VERSION ""

NS_ :

BS_:

BU_: ARM APIM_CDC APIM_CISM APIM ESPM DSP APIM_CIM FCIMB RACM_RCIM HUD_ADV WCM TRM_ITRM ACM GWM _delete IPC GENERIC TSTR

BO_ 974 DCACA_Data4_HS3: 8 GWM
 SG_ LowFuelDsplyType_B_Rq : 56|1@0+ (1,0) [0|1] "SED"  IPC
 SG_ PwBedPnlEnblScnd_B_Rq : 48|1@0+ (1,0) [0|1] "SED" Vector__XXX
 SG_ DcacSysScnd_B_Falt : 40|1@0+ (1,0) [0|1] "SED" Vector__XXX
 SG_ DcacOnScnd_B_Rq : 32|1@0+ (1,0) [0|1] "SED" Vector__XXX
 SG_ DcacGfciTestScnd_B_Rq : 24|1@0+ (1,0) [0|1] "SED" Vector__XXX
 SG_ DcacGfciTest_B_Rq : 0|1@0+ (1,0) [0|1] "SED" Vector__XXX
 SG_ EngExhMdeHrStrt_D_Stat : 53|5@0+ (1,0) [0|31] "SED"  APIM_CDC,APIM,APIM_CISM,APIM_CIM
 SG_ EngExhMdeHrEnd_D_Stat : 63|5@0+ (1,0) [0|31] "SED"  APIM_CDC,APIM,APIM_CISM,APIM_CIM
 SG_ EngExhMdeHrEnbl_D_Stat : 58|2@0+ (1,0) [0|3] "SED"  APIM_CDC,APIM,APIM_CISM,APIM_CIM
 SG_ DcacOut_Pw_DsplyMx : 23|10@0+ (10,0) [0|10220] "watts"  APIM_CDC,APIM,APIM_CIM,APIM_CISM
 SG_ DcacOut1_Pw_Dsply : 39|7@0+ (100,0) [0|12600] "watts"  APIM_CDC,APIM,APIM_CIM,APIM_CISM
 SG_ DcacOut2_Pw_Dsply : 47|7@0+ (100,0) [0|12600] "watts"  APIM_CDC,APIM,APIM_CIM,APIM_CISM
 SG_ DcacHw_D_Confg : 11|4@0+ (1,0) [0|15] "SED"  APIM_CDC,APIM,APIM_CIM,APIM_CISM
 SG_ DcacFaltMsgTxt_D_Rq : 15|4@0+ (1,0) [0|15] "SED"  APIM_CDC,APIM,APIM_CIM,APIM_CISM
 SG_ DcacLoFuelMsgTxt_D_Rq : 29|5@0+ (1,0) [0|31] "SED"  APIM_CDC,APIM,APIM_CIM,APIM_CISM
 SG_ DcacEngOnMsgTxt_D_Rq : 55|2@0+ (1,0) [0|3] "SED"  APIM_CDC,APIM,APIM_CIM,APIM_CISM
 SG_ DcacElPw_D_Stat : 2|2@0+ (1,0) [0|3] "SED"  APIM_CDC,APIM,APIM_CIM,APIM_CISM
 SG_ PwBedPnlEnbl_B_Rq : 3|1@0+ (1,0) [0|1] "SED"  GENERIC
 SG_ DcacOn_B_Rq : 4|1@0+ (1,0) [0|1] "SED"  GENERIC
 SG_ DcacSys_B_Falt : 5|1@0+ (1,0) [0|1] "SED"  GENERIC
 SG_ DcacLedCtl_D_Rq : 7|2@0+ (1,0) [0|3] "SED"  GENERIC

BO_ 810 ECG_Data_HS3: 8 GWM
 SG_ OneTEditActv_B_RqCld : 32|1@0+ (1,0) [0|1] "SED"  APIM_CDC,APIM,APIM_CIM,APIM_CISM
 SG_ ExtLghtDsply_B_StatArb : 7|1@0+ (1,0) [0|1] "SED"  APIM_CDC,APIM,APIM_CIM,APIM_CISM

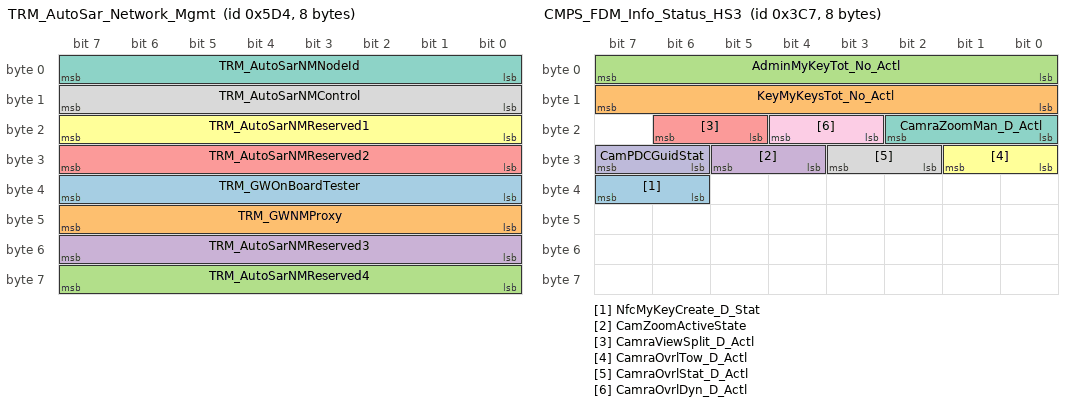
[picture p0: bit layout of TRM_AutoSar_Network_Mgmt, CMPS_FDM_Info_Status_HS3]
BO_ 1492 TRM_AutoSar_Network_Mgmt: 8 TRM_ITRM
 SG_ TRM_GWOnBoardTester : 39|8@0+ (1,0) [0|255] "unitless"  GENERIC
 SG_ TRM_GWNMProxy : 47|8@0+ (1,0) [0|255] "unitless"  GENERIC
 SG_ TRM_AutoSarNMReserved4 : 63|8@0+ (1,0) [0|255] "unitless"  GENERIC
 SG_ TRM_AutoSarNMReserved3 : 55|8@0+ (1,0) [0|255] "unitless"  GENERIC
 SG_ TRM_AutoSarNMReserved2 : 31|8@0+ (1,0) [0|255] "unitless"  GENERIC
 SG_ TRM_AutoSarNMReserved1 : 23|8@0+ (1,0) [0|255] "unitless"  GENERIC
 SG_ TRM_AutoSarNMNodeId : 7|8@0+ (1,0) [0|255] "unitless"  GENERIC
 SG_ TRM_AutoSarNMControl : 15|8@0+ (1,0) [0|255] "unitless"  GENERIC

BO_ 709 DSPAMP_RDISP_WORD_Tx: 8 DSP
 SG_ DSPAMP_RDISP_WORD_Tx : 7|64@0+ (1,0) [0|1.84467440737096E+019] "unitless"  APIM,APIM_CIM,APIM_CISM

BO_ 552 DSPAMP_Send_Signals: 8 DSP
 SG_ ActvNseMute_D_Stat : 58|2@0+ (1,0) [0|3] "SED"  APIM_CDC,APIM,APIM_CISM,APIM_CIM
 SG_ DSP_Treble_St : 55|4@0+ (1,-7) [-7|8] "unitless"  APIM_CDC,APIM,APIM_CISM,APIM_CIM
 SG_ DSP_VoiceFBVolume_Up : 35|1@0+ (1,0) [0|1] "SED"  APIM_CDC,APIM,APIM_CISM,IPC,HUD_ADV,APIM_CIM
 SG_ DSP_VoiceFBVolume_St : 63|5@0+ (1,0) [0|30] "unitless"  APIM_CDC,APIM,APIM_CISM,IPC,HUD_ADV,WCM,APIM_CIM
 SG_ DSP_TAVolume_Up : 34|1@0+ (1,0) [0|1] "SED"  APIM_CDC,APIM,APIM_CISM,IPC,HUD_ADV,APIM_CIM
 SG_ DSP_TAVolume_St : 44|5@0+ (1,0) [0|30] "unitless"  APIM_CDC,APIM,APIM_CISM,IPC,HUD_ADV,WCM,APIM_CIM
 SG_ DSP_Shaker_St : 1|1@0+ (1,0) [0|1] "SED"  APIM_CDC,APIM,APIM_CISM,APIM_CIM
 SG_ DSP_Reg_St : 27|2@0+ (1,0) [0|3] "SED"  APIM_CDC,APIM,APIM_CISM,APIM_CIM
 SG_ DSP_PhoneVolume_Up : 25|1@0+ (1,0) [0|1] "SED"  APIM_CDC,APIM,APIM_CISM,IPC,HUD_ADV,APIM_CIM
 SG_ DSP_PhoneVolume_St : 33|5@0+ (1,0) [0|30] "unitless"  APIM_CDC,APIM,APIM_CISM,IPC,HUD_ADV,WCM,APIM_CIM
 SG_ DSP_NavCmdVolume_Up : 7|1@0+ (1,0) [0|1] "SED"  APIM_CDC,APIM,APIM_CISM,IPC,HUD_ADV,APIM_CIM
 SG_ DSP_NavCmdVolume_St : 24|5@0+ (1,0) [0|30] "SED"  APIM_CDC,APIM,APIM_CISM,IPC,HUD_ADV,WCM,APIM_CIM
 SG_ DSP_Midrange_St : 51|4@0+ (1,-7) [-7|8] "unitless"  APIM_CDC,APIM,APIM_CISM,APIM_CIM
 SG_ DSP_Fader_St : 20|4@0+ (1,-7) [-7|8] "unitless"  APIM_CDC,APIM,APIM_CISM,APIM_CIM
 SG_ DSP_DSPProgram_St : 15|3@0+ (1,0) [0|7] "SED"  APIM_CDC,APIM,APIM_CISM,APIM_CIM
 SG_ DSP_DSP_St : 16|5@0+ (1,0) [0|31] "SED"  APIM_CDC,APIM,APIM_CISM,APIM_CIM
 SG_ DSP_Bass_St : 12|4@0+ (1,-7) [-7|8] "unitless"  APIM_CDC,APIM,APIM_CISM,APIM_CIM
 SG_ DSP_Balance_St : 8|4@0+ (1,-7) [-7|8] "unitless"  APIM_CDC,APIM,APIM_CISM,APIM_CIM
 SG_ DSP_AVC_St : 6|3@0+ (1,0) [0|7] "SED"  APIM_CDC,APIM,APIM_CISM,APIM_CIM
 SG_ Audio_Demo_Status : 0|1@0+ (1,0) [0|1] "SED"  APIM_CDC,APIM,APIM_CISM,APIM_CIM

BO_ 967 CMPS_FDM_Info_Status_HS3: 8 GWM
 SG_ NfcMyKeyCreate_D_Stat : 39|2@0+ (1,0) [0|3] "SED"  APIM,APIM_CIM
 SG_ KeyMyKeysTot_No_Actl : 15|8@0+ (1,0) [0|255] "unitless"  APIM,APIM_CIM
 SG_ AdminMyKeyTot_No_Actl : 7|8@0+ (1,0) [0|255] "unitless"  APIM,APIM_CIM
 SG_ CamZoomActiveState : 29|2@0+ (1,0) [0|3] "SED"  APIM_CDC,APIM,APIM_CIM,APIM_CISM
 SG_ CamraViewSplit_D_Actl : 22|2@0+ (1,0) [0|3] "SED"  APIM_CDC,APIM,APIM_CIM,APIM_CISM
 SG_ CamraOvrlTow_D_Actl : 25|2@0+ (1,0) [0|3] "SED"  APIM_CDC,APIM,APIM_CIM,APIM_CISM
 SG_ CamraZoomMan_D_Actl : 18|3@0+ (1,0) [0|7] "SED"  APIM_CDC,APIM,APIM_CIM,APIM_CISM
 SG_ CamraOvrlStat_D_Actl : 27|2@0+ (1,0) [0|3] "SED"  APIM_CDC,APIM,APIM_CIM,APIM_CISM
 SG_ CamraOvrlDyn_D_Actl : 20|2@0+ (1,0) [0|3] "SED"  APIM_CDC,APIM,APIM_CIM,APIM_CISM
 SG_ CamPDCGuidStat : 31|2@0+ (1,0) [0|3] "SED"  APIM_CDC,APIM,APIM_CIM,APIM_CISM

BO_ 1105 Image_Processing_Data_HS3: 8 GWM
 SG_ ClrExitAsstActv_B_Rq : 24|1@0+ (1,0) [0|1] "SED"  APIM_CDC,APIM,APIM_CISM,APIM_CIM
 SG_ ClrExitAsstMsgTxt2_D_Rq : 55|4@0+ (1,0) [0|15] "SED"  APIM_CDC,APIM,APIM_CISM,APIM_CIM
 SG_ TrlrRvrseEnbl_D2_Stat : 18|3@0+ (1,0) [0|7] "SED"  APIM_CDC,APIM,APIM_CIM,APIM_CISM,TRM_ITRM,IPC
 SG_ TrlrAidSwtchLamp_B_Rq : 32|1@0+ (1,0) [0|1] "SED"  TRM_ITRM
 SG_ TrlrAidEnbl_D_RqAdas : 5|3@0+ (1,0) [0|7] "SED"  GENERIC
 SG_ TrlrHitchMsgTxt_D_Rq : 47|6@0+ (1,0) [0|63] "SED"  APIM_CDC,APIM,APIM_CIM,APIM_CISM
 SG_ TrlrHitchIcon_D_Rq : 36|4@0+ (1,0) [0|15] "SED"  APIM_CDC,APIM,APIM_CIM,APIM_CISM
 SG_ CamraFrntOffRd_B_Stat : 25|1@0+ (1,0) [0|1] "SED"  APIM_CDC,APIM,APIM_CIM,APIM_CISM
 SG_ TrlrHitchChime_D_Rq : 39|3@0+ (1,0) [0|7] "SED"  APIM_CDC,IPC,APIM_CIM
 SG_ TrlrRvrseMsgTxt_D2_Rq : 31|6@0+ (1,0) [0|63] "SED"  APIM_CDC,APIM,APIM_CIM,APIM_CISM,TRM_ITRM,IPC
 SG_ RbaMsg_D_Rq : 22|2@0+ (1,0) [0|3] "SED"  APIM_CDC,APIM_CIM,IPC
 SG_ BrkDecel_B_RqRba : 8|1@0+ (1,0) [0|1] "SED" Vector__XXX
 SG_ BrkEnbl_B_RqRba : 23|1@0+ (1,0) [0|1] "SED" Vector__XXX
 SG_ Rba_D_Stat : 14|2@0+ (1,0) [0|3] "SED"  APIM_CDC,APIM,APIM_CIM,APIM_CISM,IPC
 SG_ RbaAlrt_D_Dsply : 12|2@0+ (1,0) [0|3] "SED"  APIM_CDC,APIM,APIM_CIM,APIM_CISM,IPC
 SG_ RbaMnu_D_Rq : 10|2@0+ (1,0) [0|3] "SED"  APIM_CDC,APIM,APIM_CIM,APIM_CISM
 SG_ CamraFrntStat_D_Stat : 7|2@0+ (1,0) [0|3] "SED"  APIM_CDC,APIM,APIM_CISM,APIM_CIM,FCIMB,ACM,IPC
 SG_ TrlrHitchLamp_D_Rq2 : 15|1@0+ (1,0) [0|1] "SED" Vector__XXX

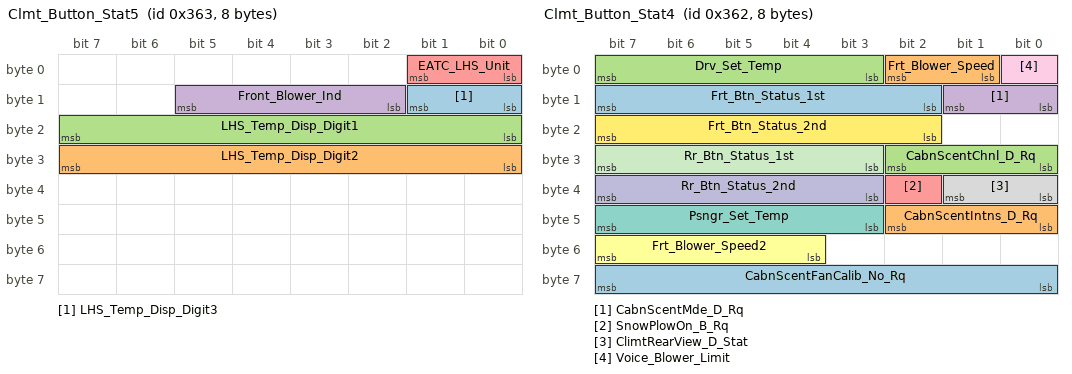
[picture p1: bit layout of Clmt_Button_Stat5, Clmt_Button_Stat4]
BO_ 867 Clmt_Button_Stat5: 8 IPC
 SG_ LHS_Temp_Disp_Digit3 : 9|2@0+ (1,0) [0|3] "SED"  HUD_ADV,GWM
 SG_ LHS_Temp_Disp_Digit2 : 31|8@0+ (1,0) [0|255] "ASCII"  HUD_ADV,GWM
 SG_ LHS_Temp_Disp_Digit1 : 23|8@0+ (1,0) [0|255] "ASCII"  HUD_ADV,GWM
 SG_ Front_Blower_Ind : 13|4@0+ (1,0) [0|15] "SED"  GWM
 SG_ EATC_LHS_Unit : 1|2@0+ (1,0) [0|3] "SED"  HUD_ADV,GWM

BO_ 866 Clmt_Button_Stat4: 8 APIM
 SG_ CabnScentFanCalib_No_Rq : 63|8@0+ (1,0) [0|255] "SED"  GWM
 SG_ CabnScentIntns_D_Rq : 42|3@0+ (1,0) [0|7] "SED"  GWM
 SG_ CabnScentChnl_D_Rq : 26|3@0+ (1,0) [0|7] "SED"  GWM
 SG_ CabnScentMde_D_Rq : 9|2@0+ (1,0) [0|3] "SED"  GWM
 SG_ SnowPlowOn_B_Rq : 34|1@0+ (1,0) [0|1] "SED"  GWM
 SG_ Frt_Blower_Speed2 : 55|4@0+ (1,0) [0|15] "SED"  RACM_RCIM,GWM
 SG_ Psngr_Set_Temp : 47|5@0+ (1,0) [0|31] "SED"  RACM_RCIM,GWM
 SG_ ClimtRearView_D_Stat : 33|2@0+ (1,0) [0|3] "SED"  GWM,RACM_RCIM
 SG_ Voice_Blower_Limit : 0|1@0+ (1,0) [0|1] "SED"  GWM
 SG_ Rr_Btn_Status_2nd : 39|5@0+ (1,0) [0|31] "SED"  RACM_RCIM,GWM
 SG_ Rr_Btn_Status_1st : 31|5@0+ (1,0) [0|31] "SED"  RACM_RCIM,GWM
 SG_ Frt_Btn_Status_2nd : 23|6@0+ (1,0) [0|63] "SED"  ACM,RACM_RCIM,GWM
 SG_ Frt_Btn_Status_1st : 15|6@0+ (1,0) [0|63] "SED"  ACM,RACM_RCIM,GWM
 SG_ Frt_Blower_Speed : 2|2@0+ (1,0) [0|3] "SED"  RACM_RCIM,GWM
 SG_ Drv_Set_Temp : 7|5@0+ (1,0) [0|31] "SED"  RACM_RCIM,GWM

BO_ 861 Clmt_Button_Stat3_HS3: 8 GWM
 SG_ Rr_Temp_Detents : 63|6@0+ (1,0) [0|63] "SED"  APIM_CDC,APIM,APIM_CIM,APIM_CISM,RACM_RCIM
 SG_ Rr_Power_Btn_Stt : 57|2@0+ (1,0) [0|3] "SED"  APIM_CDC,APIM,APIM_CIM,APIM_CISM,RACM_RCIM
 SG_ Rr_RH_Cond_Seat_Stat : 18|3@0+ (1,0) [0|7] "SED"  APIM_CDC,APIM,APIM_CIM,APIM_CISM,RACM_RCIM
 SG_ Rr_Pnl_Flr_Btn_Stt : 33|2@0+ (1,0) [0|3] "SED"  APIM_CDC,APIM,APIM_CIM,APIM_CISM,RACM_RCIM
 SG_ Rr_LH_Cond_Seat_Stat : 21|3@0+ (1,0) [0|7] "SED"  APIM_CDC,APIM,APIM_CIM,APIM_CISM,RACM_RCIM
 SG_ CC_Rr_Stat_User_Adj : 7|4@0+ (1,0) [0|15] "SED"  APIM_CDC,APIM,APIM_CIM,APIM_CISM,RACM_RCIM
 SG_ Rr_Set_Temp_Units : 41|2@0+ (1,0) [0|3] "SED"  APIM_CDC,APIM,APIM_CIM,APIM_CISM,RACM_RCIM
 SG_ Rr_RHS_Set_Temp_Dig3 : 43|2@0+ (1,0) [0|3] "SED"  APIM_CDC,APIM,APIM_CIM,APIM_CISM,RACM_RCIM
 SG_ Rr_RHS_Set_Temp_Dig2 : 51|4@0+ (1,0) [0|15] "SED"  APIM_CDC,APIM,APIM_CIM,APIM_CISM,RACM_RCIM
 SG_ Rr_RHS_Set_Temp_Dig1 : 55|4@0+ (1,0) [0|15] "SED"  APIM_CDC,APIM,APIM_CIM,APIM_CISM,RACM_RCIM
 SG_ Rr_RH_Htd_Seat_Btn_Stt : 45|2@0+ (1,0) [0|3] "SED"  APIM_CDC,APIM,APIM_CIM,APIM_CISM,RACM_RCIM
 SG_ Rr_RH_Cld_Seat_Btn_Stt : 47|2@0+ (1,0) [0|3] "SED"  APIM_CDC,APIM,APIM_CIM,APIM_CISM,RACM_RCIM
 SG_ Rr_Panel_Btn_Stt : 35|2@0+ (1,0) [0|3] "SED"  APIM_CDC,APIM,APIM_CIM,APIM_CISM,RACM_RCIM
 SG_ Rr_On_Indicator : 2|1@0+ (1,0) [0|1] "SED"  APIM_CDC,APIM,APIM_CIM,APIM_CISM,RACM_RCIM
 SG_ Rr_LHS_Set_Temp_Dig3 : 37|2@0+ (1,0) [0|3] "SED"  APIM_CDC,APIM,APIM_CIM,APIM_CISM,RACM_RCIM
 SG_ Rr_LHS_Set_Temp_Dig2 : 25|4@0+ (1,0) [0|15] "SED"  APIM_CDC,APIM,APIM_CIM,APIM_CISM,RACM_RCIM
 SG_ Rr_LHS_Set_Temp_Dig1 : 29|4@0+ (1,0) [0|15] "SED"  APIM_CDC,APIM,APIM_CIM,APIM_CISM,RACM_RCIM
 SG_ Rr_LH_Htd_Seat_Btn_Stt : 31|2@0+ (1,0) [0|3] "SED"  APIM_CDC,APIM,APIM_CIM,APIM_CISM,RACM_RCIM
 SG_ Rr_LH_Cld_Seat_Btn_Stt : 23|2@0+ (1,0) [0|3] "SED"  APIM_CDC,APIM,APIM_CIM,APIM_CISM,RACM_RCIM
 SG_ Rr_Floor_Btn_Stt : 9|2@0+ (1,0) [0|3] "SED"  APIM_CDC,APIM,APIM_CIM,APIM_CISM,RACM_RCIM
 SG_ Rr_Control_Btn_Stt : 11|2@0+ (1,0) [0|3] "SED"  APIM_CDC,APIM,APIM_CIM,APIM_CISM,RACM_RCIM
 SG_ Rr_Blower_Indicate : 15|4@0+ (1,0) [0|15] "SED"  APIM_CDC,APIM,APIM_CIM,APIM_CISM,RACM_RCIM
 SG_ Rr_AUTO_Btn_Stt : 1|2@0+ (1,0) [0|3] "SED"  APIM_CDC,APIM,APIM_CIM,APIM_CISM,RACM_RCIM

BO_ 865 Clmt_Button_Stat2_HS3: 8 GWM
 SG_ Dsp_RotAddrBtnEv_St : 63|4@0+ (1,0) [0|15] "SED"  APIM_CDC,APIM,APIM_CIM,APIM_CISM
 SG_ SelDrvMdeButtn_B_Stat : 55|1@0+ (1,0) [0|1] "SED" Vector__XXX
 SG_ SteEffortButtn_B_Stat : 54|1@0+ (1,0) [0|1] "SED"  APIM_CDC,APIM_CIM,IPC
 SG_ SelDrvMdeSwtch_D_Stat2 : 51|2@0+ (1,0) [0|3] "SED" Vector__XXX
 SG_ EngExhMdeQuiet_B_RqDrv : 52|1@0+ (1,0) [0|1] "SED"  APIM_CDC,APIM_CIM,IPC
 SG_ LnchCtlSys_B_RqDrv : 53|1@0+ (1,0) [0|1] "SED"  APIM_CDC,APIM_CIM,IPC
 SG_ CC_Fr_Stat_User_Adj : 6|3@0+ (1,0) [0|7] "SED"  HUD_ADV,GENERIC
 SG_ RHS_Auto_Seat_Btn_Stt : 57|2@0+ (1,0) [0|3] "SED"  APIM_CDC,APIM,APIM_CIM,APIM_CISM,FCIMB
 SG_ Front_Blower_Indicate : 13|4@0+ (1,0) [0|15] "SED"  APIM_CDC,APIM,APIM_CISM,HUD_ADV,APIM_CIM,IPC
 SG_ CC_Diagnostics_Active : 7|1@0+ (1,0) [0|1] "SED"  IPC
 SG_ RHS_Temp_Display_Digit3 : 3|2@0+ (1,0) [0|3] "SED"  APIM_CDC,APIM,APIM_CIM,APIM_CISM,IPC
 SG_ RHS_Temp_Display_Digit2 : 47|8@0+ (1,0) [0|255] "ASCII"  APIM_CDC,APIM,APIM_CIM,APIM_CISM,IPC
 SG_ RHS_Temp_Display_Digit1 : 39|8@0+ (1,0) [0|255] "ASCII"  APIM_CDC,APIM,APIM_CIM,APIM_CISM,IPC
 SG_ LHS_Temp_Display_Digit3 : 9|2@0+ (1,0) [0|3] "SED"  APIM_CDC,APIM,APIM_CIM,APIM_CISM,IPC
 SG_ LHS_Temp_Display_Digit2 : 31|8@0+ (1,0) [0|255] "ASCII"  APIM_CDC,APIM,APIM_CIM,APIM_CISM,IPC
 SG_ LHS_Temp_Display_Digit1 : 23|8@0+ (1,0) [0|255] "ASCII"  APIM_CDC,APIM,APIM_CIM,APIM_CISM,IPC
 SG_ EATC_RHS_Units : 15|2@0+ (1,0) [0|3] "SED"  APIM_CDC,APIM,APIM_CIM,APIM_CISM,IPC
 SG_ EATC_LHS_Units : 1|2@0+ (1,0) [0|3] "SED"  APIM_CDC,APIM,APIM_CIM,APIM_CISM,IPC
 SG_ LHS_Auto_Seat_Btn_Stt : 59|2@0+ (1,0) [0|3] "SED"  APIM_CDC,APIM,APIM_CIM,APIM_CISM,FCIMB

BO_ 1046 BrakeSysFeatures_2_HS3: 8 GWM
 SG_ PrkBrkDynmc_D_Allw : 39|2@0+ (1,0) [0|3] "SED"  IPC
 SG_ BrkPrkBrkDynmc_B_Actl : 24|1@0+ (1,0) [0|1] "SED"  IPC
 SG_ TRLR_SWAY_EVNT_IN_PROG : 25|1@0+ (1,0) [0|1] "SED"  APIM_CDC,APIM,APIM_CISM,APIM_CIM,IPC
 SG_ TRLR_SWAY_CONFIG_STAT : 26|1@0+ (1,0) [0|1] "SED"  APIM_CDC,APIM,APIM_CISM,APIM_CIM,IPC
 SG_ ReserveTracCtlPtActv : 28|1@0+ (1,0) [0|1] "SED" Vector__XXX
 SG_ HsaMde_D_Mem : 33|2@0+ (1,0) [0|3] "SED"  APIM_CDC,APIM,APIM_CISM,APIM_CIM,IPC
 SG_ BrkBstrVac_B_Rq : 27|1@0+ (1,0) [0|1] "Discrete" Vector__XXX
 SG_ BpedDiffLckTq_No_Cs : 23|8@0+ (1,0) [0|255] "unitless"  GENERIC
 SG_ DrvSlipCtlMde_D_Ind : 44|2@0+ (1,0) [0|3] "SED"  APIM_CDC,APIM_CIM,IPC
 SG_ DrvSlipCtlLamp_D_Rq : 42|2@0+ (1,0) [0|3] "SED"  APIM_CDC,APIM_CISM,APIM_CIM,IPC
 SG_ TCMode : 15|1@0+ (1,0) [0|1] "SED"  APIM_CDC,APIM,APIM_CIM,APIM_CISM,IPC
 SG_ HILL_DESC_MC : 47|3@0+ (1,0) [0|7] "SED"  APIM_CDC,APIM,APIM_CISM,APIM_CIM,IPC
 SG_ DrvAntiLckLamp_D_Rq : 55|2@0+ (1,0) [0|3] "SED"  APIM_CDC,APIM_CISM,APIM_CIM,IPC
 SG_ ChimeBrk_B_Rq : 14|1@0+ (1,0) [0|1] "SED"  APIM_CDC,APIM_CIM,IPC
 SG_ BrkLamp_B_Rq : 13|1@0+ (1,0) [0|1] "SED"  APIM_CDC,APIM_CIM,IPC
 SG_ Abs_B_Falt : 5|1@0+ (1,0) [0|1] "SED"  TRM_ITRM,IPC
 SG_ StabCtlBrk_B_Avail : 4|1@0+ (1,0) [0|1] "SED"  IPC
 SG_ DrvHdcWarnInfo_D_Rq : 35|2@0+ (1,0) [0|3] "SED"  APIM_CDC,APIM_CIM,IPC
 SG_ DrvHdcMsg_D_Rq : 10|3@0+ (1,0) [0|7] "SED"  IPC
 SG_ DrvHdcLampInfo_D_Rq : 12|2@0+ (1,0) [0|3] "SED"  APIM_CDC,APIM,APIM_CISM,APIM_CIM,IPC
 SG_ RearDiffElckrOpen_B_Rq : 40|1@0+ (1,0) [0|1] "SED"  GENERIC
 SG_ BpedMove_No_Cnt : 3|4@0+ (1,0) [0|15] "unitless"  GENERIC
 SG_ BpedMove_D_Actl : 7|2@0+ (1,0) [0|3] "SED" Vector__XXX
 SG_ RearDiffLck_Tq2_RqMx : 51|12@0+ (4,0) [0|16376] "Nm"  GENERIC
 SG_ HdcMde_D_Actl : 31|3@0+ (1,0) [0|7] "SED" Vector__XXX

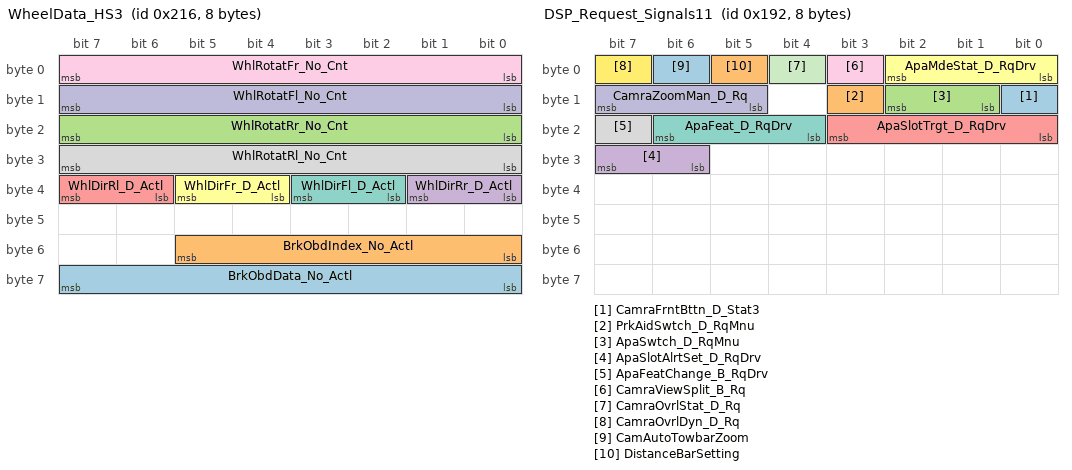
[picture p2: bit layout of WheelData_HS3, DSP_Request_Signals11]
BO_ 534 WheelData_HS3: 8 GWM
 SG_ BrkObdData_No_Actl : 63|8@0+ (1,0) [0|255] "unitless"  GENERIC
 SG_ BrkObdIndex_No_Actl : 53|6@0+ (1,0) [0|63] "unitless"  GENERIC
 SG_ WhlRotatRr_No_Cnt : 23|8@0+ (1,0) [0|255] "unitless"  APIM_CDC,APIM,APIM_CIM,APIM_CISM
 SG_ WhlDirRr_D_Actl : 33|2@0+ (1,0) [0|3] "SED"  APIM_CDC,APIM,APIM_CIM,APIM_CISM
 SG_ WhlDirRl_D_Actl : 39|2@0+ (1,0) [0|3] "SED"  APIM_CDC,APIM,APIM_CIM,APIM_CISM
 SG_ WhlDirFr_D_Actl : 37|2@0+ (1,0) [0|3] "SED"  APIM_CDC,APIM,APIM_CIM,APIM_CISM
 SG_ WhlDirFl_D_Actl : 35|2@0+ (1,0) [0|3] "SED"  APIM_CDC,APIM,APIM_CIM,APIM_CISM
 SG_ WhlRotatRl_No_Cnt : 31|8@0+ (1,0) [0|255] "unitless"  APIM_CDC,APIM,APIM_CIM,APIM_CISM
 SG_ WhlRotatFr_No_Cnt : 7|8@0+ (1,0) [0|255] "unitless"  APIM_CDC,APIM,APIM_CIM,APIM_CISM
 SG_ WhlRotatFl_No_Cnt : 15|8@0+ (1,0) [0|255] "unitless"  APIM_CDC,APIM,APIM_CIM,APIM_CISM

BO_ 402 DSP_Request_Signals11: 8 APIM_CIM
 SG_ CamraFrntBttn_D_Stat3 : 8|1@0+ (1,0) [0|1] "SED"  GWM
 SG_ PrkAidSwtch_D_RqMnu : 11|1@0+ (1,0) [0|1] "SED"  GWM
 SG_ ApaSwtch_D_RqMnu : 10|2@0+ (1,0) [0|3] "SED"  GWM
 SG_ ApaSlotAlrtSet_D_RqDrv : 31|2@0+ (1,0) [0|3] "SED"  GWM
 SG_ ApaSlotTrgt_D_RqDrv : 19|4@0+ (1,0) [0|15] "SED"  GWM
 SG_ ApaMdeStat_D_RqDrv : 2|3@0+ (1,0) [0|7] "SED"  GWM
 SG_ ApaFeat_D_RqDrv : 22|3@0+ (1,0) [0|7] "SED"  GWM
 SG_ ApaFeatChange_B_RqDrv : 23|1@0+ (1,0) [0|1] "SED"  GWM
 SG_ CamraViewSplit_B_Rq : 3|1@0+ (1,0) [0|1] "SED"  GWM
 SG_ CamraZoomMan_D_Rq : 15|3@0+ (1,0) [0|7] "SED"  GWM
 SG_ CamraOvrlStat_D_Rq : 4|1@0+ (1,0) [0|1] "SED"  IPC,GWM
 SG_ CamraOvrlDyn_D_Rq : 7|1@0+ (1,0) [0|1] "SED"  IPC,GWM
 SG_ CamAutoTowbarZoom : 6|1@0+ (1,0) [0|1] "SED"  IPC,GWM
 SG_ DistanceBarSetting : 5|1@0+ (1,0) [0|1] "SED"  GWM

BO_ 946 BodyInfo_3_HS3: 8 GWM
 SG_ ValetMode_D_Mem : 16|1@0+ (1,0) [0|1] "SED"  GENERIC
 SG_ DimmingLvlEvnt_No_Actl : 18|2@0+ (1,0) [0|3] "unitless"  APIM_CDC,APIM_CIM,IPC
 SG_ DrStatDrvErrCnt_B_Stat : 19|1@0+ (1,0) [0|1] "SED" Vector__XXX
 SG_ Backlit_LED_Status : 23|4@0+ (1,0) [0|15] "SED"  APIM_CDC,APIM,APIM_CIM,APIM_CISM,TRM_ITRM
 SG_ TurnLghtRightOn_B_Stat : 35|1@0+ (1,0) [0|1] "SED"  APIM_CDC,APIM_CISM,HUD_ADV,APIM_CIM,ACM,IPC
 SG_ TurnLghtLeftOn_B_Stat : 54|1@0+ (1,0) [0|1] "SED"  APIM_CDC,APIM_CISM,HUD_ADV,DSP,APIM_CIM,ACM,IPC
 SG_ FogLghtRearOn_B_Stat : 1|1@0+ (1,0) [0|1] "SED"  APIM_CDC,APIM_CISM,TRM_ITRM,APIM_CIM,IPC
 SG_ TurnLghtRight_D_Rq : 63|2@0+ (1,0) [0|3] "SED"  APIM_CISM,APIM_CIM,TRM_ITRM,DSP
 SG_ IgnKeyType_D_Actl : 39|4@0+ (1,0) [0|15] "SED"  APIM_CDC,APIM,APIM_CISM,APIM_CIM,DSP,ACM,IPC
 SG_ Parklamp_Status : 3|2@0+ (1,0) [0|3] "SED"  APIM_CDC,APIM,APIM_CISM,APIM_CIM,TRM_ITRM,RACM_RCIM,ACM,IPC
 SG_ Litval : 47|8@0+ (1,0) [0|253] "SED"  APIM_CDC,RACM_RCIM,APIM,APIM_CIM,APIM_CISM,ACM,IPC
 SG_ Key_In_Ignition_Stat : 11|1@0+ (1,0) [0|1] "SED"  APIM_CDC,APIM,APIM_CIM,APIM_CISM,DSP,ACM,IPC
 SG_ Ignition_Status : 7|4@0+ (1,0) [0|15] "SED"  ARM,APIM_CDC,APIM,APIM_CISM,APIM_CIM,ESPM,HUD_ADV,DSP,TRM_ITRM,RACM_RCIM,ACM,WCM,IPC
 SG_ Dimming_Lvl : 31|8@0+ (1,0) [0|253] "SED"  APIM_CDC,APIM,APIM_CISM,APIM_CIM,HUD_ADV,TRM_ITRM,RACM_RCIM,ACM,ARM,IPC
 SG_ Day_Night_Status : 15|2@0+ (1,0) [0|3] "SED"  ARM,APIM_CDC,APIM,APIM_CIM,APIM_CISM,HUD_ADV,TRM_ITRM,RACM_RCIM,ACM,IPC
 SG_ Remote_Start_Status : 13|2@0+ (1,0) [0|3] "SED"  ARM,APIM_CDC,APIM,APIM_CIM,APIM_CISM,IPC
 SG_ DrStatTgate_B_Actl : 0|1@0+ (1,0) [0|1] "SED"  APIM_CDC,APIM,APIM_CISM,APIM_CIM,TRM_ITRM,ACM,IPC
 SG_ DrStatRr_B_Actl : 49|1@0+ (1,0) [0|1] "SED"  APIM_CDC,APIM,APIM_CISM,APIM_CIM,TRM_ITRM,HUD_ADV,ACM,IPC
 SG_ DrStatRl_B_Actl : 48|1@0+ (1,0) [0|1] "SED"  APIM_CDC,APIM,APIM_CISM,APIM_CIM,TRM_ITRM,HUD_ADV,ACM,IPC
 SG_ DrStatPsngr_B_Actl : 60|1@0+ (1,0) [0|1] "SED"  APIM_CDC,APIM,APIM_CISM,APIM_CIM,TRM_ITRM,HUD_ADV,ACM,IPC
 SG_ FogLghtFrontOn_B_Stat : 56|1@0+ (1,0) [0|1] "SED"  ARM,APIM_CDC,APIM,APIM_CISM,APIM_CIM,IPC
 SG_ DrStatInnrTgate_B_Actl : 58|1@0+ (1,0) [0|1] "SED"  APIM_CDC,APIM,APIM_CISM,APIM_CIM,TRM_ITRM,HUD_ADV,IPC,ACM
 SG_ DrStatHood_B_Actl : 59|1@0+ (1,0) [0|1] "SED"  APIM_CDC,APIM,APIM_CISM,APIM_CIM,IPC,ACM
 SG_ DrStatDrv_B_Actl : 61|1@0+ (1,0) [0|1] "SED"  APIM_CDC,APIM,APIM_CISM,APIM_CIM,TRM_ITRM,HUD_ADV,ACM,IPC
 SG_ PrkBrkActv_B_Actl : 55|1@0+ (1,0) [0|1] "SED"  APIM_CDC,APIM,APIM_CIM,APIM_CISM,IPC
 SG_ LifeCycMde_D_Actl : 53|4@0+ (1,0) [0|15] "SED"  APIM_CDC,RACM_RCIM,APIM,APIM_CISM,APIM_CIM,WCM,TRM_ITRM,HUD_ADV,DSP,ACM,IPC
 SG_ Delay_Accy : 57|1@0+ (1,0) [0|1] "SED"  APIM_CDC,APIM,APIM_CISM,APIM_CIM,HUD_ADV,DSP,ACM,WCM,IPC
 SG_ TurnLghtLeft_D_Rq : 9|2@0+ (1,0) [0|3] "SED"  APIM_CISM,APIM_CIM,TRM_ITRM
 SG_ CrashEvnt_D_Stat : 34|2@0+ (1,0) [0|3] "SED" Vector__XXX
 SG_ FuelPmpInhbt_B_Stat : 32|1@0+ (1,0) [0|1] "SED" Vector__XXX
 SG_ BodySrvcRqd_B_Rq : 10|1@0+ (1,0) [0|1] "SED"  APIM_CDC,APIM_CIM,IPC

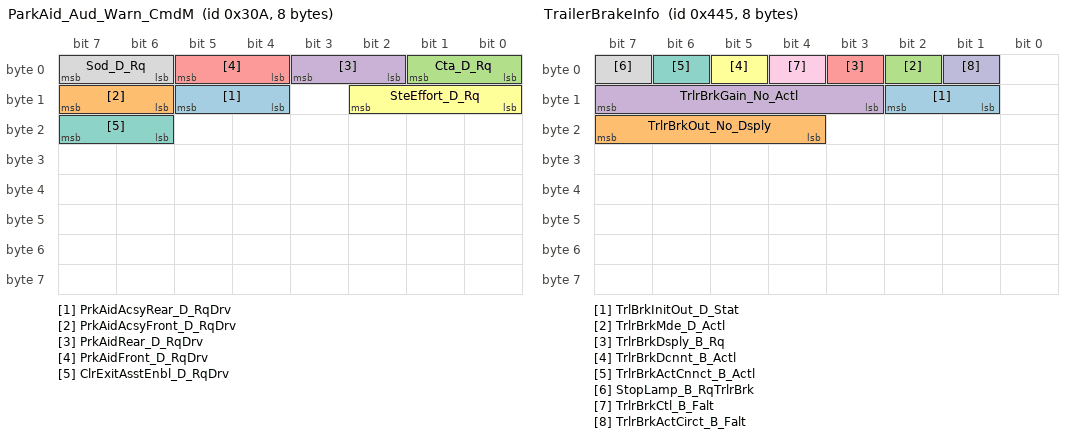
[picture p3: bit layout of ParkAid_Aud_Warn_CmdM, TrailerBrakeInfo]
BO_ 778 ParkAid_Aud_Warn_CmdM: 8 IPC
 SG_ PrkAidAcsyRear_D_RqDrv : 13|2@0+ (1,0) [0|3] "SED"  GWM
 SG_ PrkAidAcsyFront_D_RqDrv : 15|2@0+ (1,0) [0|3] "SED"  GWM
 SG_ Cta_D_Rq : 1|2@0+ (1,0) [0|3] "SED"  GWM
 SG_ PrkAidRear_D_RqDrv : 3|2@0+ (1,0) [0|3] "SED"  GWM
 SG_ PrkAidFront_D_RqDrv : 5|2@0+ (1,0) [0|3] "SED"  GWM
 SG_ SteEffort_D_Rq : 10|3@0+ (1,0) [0|7] "SED"  GWM
 SG_ ClrExitAsstEnbl_D_RqDrv : 23|2@0+ (1,0) [0|3] "SED"  GWM
 SG_ Sod_D_Rq : 7|2@0+ (1,0) [0|3] "SED"  GWM

BO_ 1093 TrailerBrakeInfo: 8 TRM_ITRM
 SG_ TrlBrkInitOut_D_Stat : 10|2@0+ (1,0) [0|3] "SED"  APIM_CDC,APIM_CIM,IPC,GWM
 SG_ TrlrBrkOut_No_Dsply : 23|4@0+ (1,0) [0|15] "unitless"  APIM_CDC,HUD_ADV,APIM_CIM,IPC,GWM
 SG_ TrlrBrkMde_D_Actl : 2|1@0+ (1,0) [0|1] "SED"  APIM_CDC,APIM_CIM,IPC,GWM
 SG_ TrlrBrkGain_No_Actl : 15|5@0+ (0.5,0) [0|15.5] "unitless"  APIM_CDC,HUD_ADV,APIM,APIM_CISM,APIM_CIM,IPC,GWM
 SG_ TrlrBrkDsply_B_Rq : 3|1@0+ (1,0) [0|1] "SED"  APIM_CDC,HUD_ADV,APIM_CIM,IPC,GWM
 SG_ TrlrBrkDcnnt_B_Actl : 5|1@0+ (1,0) [0|1] "SED"  APIM_CDC,HUD_ADV,APIM_CIM,IPC,GWM
 SG_ TrlrBrkActCnnct_B_Actl : 6|1@0+ (1,0) [0|1] "SED"  APIM_CDC,HUD_ADV,APIM,APIM_CISM,APIM_CIM,IPC,GWM
 SG_ StopLamp_B_RqTrlrBrk : 7|1@0+ (1,0) [0|1] "SED"  GWM
 SG_ TrlrBrkCtl_B_Falt : 4|1@0+ (1,0) [0|1] "SED"  APIM_CDC,APIM_CIM,IPC,GWM
 SG_ TrlrBrkActCirct_B_Falt : 1|1@0+ (1,0) [0|1] "SED"  APIM_CDC,APIM_CIM,IPC,GWM

BO_ 1879 TesterPhysicalReqTBM: 8 TSTR
 SG_ TesterPhysicalReqTBM : 7|64@0+ (1,0) [0|1.84467E+019] "unitless"  TRM_ITRM

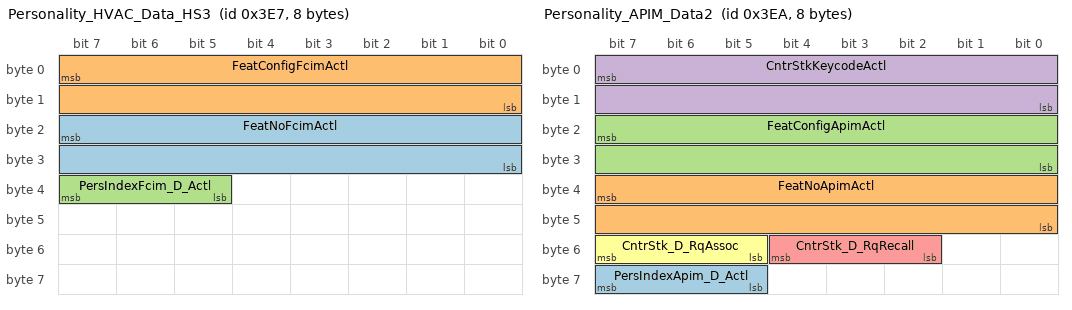
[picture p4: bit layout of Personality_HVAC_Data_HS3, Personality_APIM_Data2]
BO_ 999 Personality_HVAC_Data_HS3: 8 GWM
 SG_ FeatNoFcimActl : 23|16@0+ (1,0) [0|65535] "Number"  APIM_CDC,APIM,APIM_CIM,APIM_CISM,IPC
 SG_ FeatConfigFcimActl : 7|16@0+ (1,0) [0|65535] "Undefined"  APIM_CDC,APIM,APIM_CIM,APIM_CISM,IPC
 SG_ PersIndexFcim_D_Actl : 39|3@0+ (1,0) [0|7] "SED"  APIM_CDC,APIM,APIM_CIM,APIM_CISM,IPC

BO_ 1002 Personality_APIM_Data2: 8 APIM
 SG_ PersIndexApim_D_Actl : 63|3@0+ (1,0) [0|7] "SED"  IPC,GWM
 SG_ FeatNoApimActl : 39|16@0+ (1,0) [0|65535] "Number"  GWM,IPC
 SG_ FeatConfigApimActl : 23|16@0+ (1,0) [0|65535] "Number"  GWM,IPC
 SG_ CntrStkKeycodeActl : 7|16@0+ (1,0) [0|65535] "Undefined"  GWM
 SG_ CntrStk_D_RqRecall : 52|3@0+ (1,0) [0|7] "SED"  GWM
 SG_ CntrStk_D_RqAssoc : 55|3@0+ (1,0) [0|7] "SED"  GWM

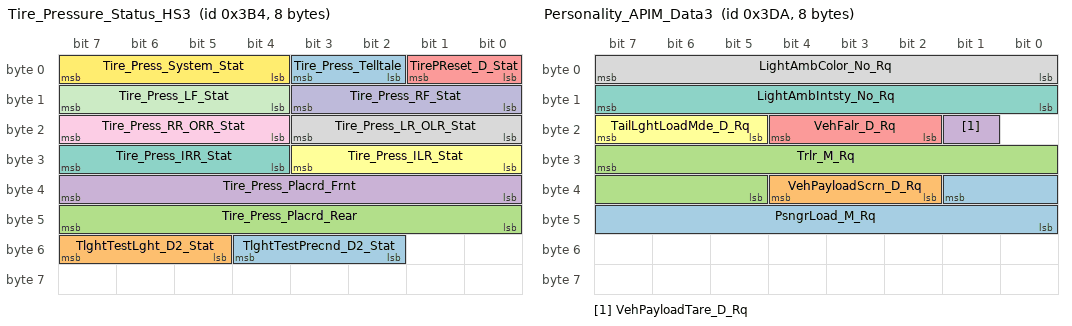
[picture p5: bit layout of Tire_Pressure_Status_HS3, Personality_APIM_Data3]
BO_ 948 Tire_Pressure_Status_HS3: 8 GWM
 SG_ TlghtTestPrecnd_D2_Stat : 52|3@0+ (1,0) [0|7] "SED"  APIM_CDC,APIM,APIM_CIM,APIM_CISM
 SG_ TlghtTestLght_D2_Stat : 55|3@0+ (1,0) [0|7] "SED"  APIM_CDC,APIM,APIM_CIM,APIM_CISM
 SG_ Tire_Press_Placrd_Rear : 47|8@0+ (1,0) [0|255] "pounds/inch^2"  APIM_CDC,APIM,APIM_CISM,APIM_CIM,IPC
 SG_ Tire_Press_Placrd_Frnt : 39|8@0+ (1,0) [0|255] "pounds/inch^2"  APIM_CDC,APIM,APIM_CISM,APIM_CIM,IPC
 SG_ TirePReset_D_Stat : 1|2@0+ (1,0) [0|3] "Discrete"  APIM_CDC,APIM,APIM_CISM,APIM_CIM,IPC
 SG_ Tire_Press_ILR_Stat : 27|4@0+ (1,0) [0|15] "SED"  APIM_CDC,HUD_ADV,APIM,APIM_CISM,APIM_CIM,IPC
 SG_ Tire_Press_IRR_Stat : 31|4@0+ (1,0) [0|15] "SED"  APIM_CDC,HUD_ADV,APIM,APIM_CISM,APIM_CIM,IPC
 SG_ Tire_Press_LR_OLR_Stat : 19|4@0+ (1,0) [0|15] "SED"  APIM_CDC,HUD_ADV,APIM,APIM_CISM,APIM_CIM,IPC
 SG_ Tire_Press_RR_ORR_Stat : 23|4@0+ (1,0) [0|15] "SED"  APIM_CDC,HUD_ADV,APIM,APIM_CISM,APIM_CIM,IPC
 SG_ Tire_Press_RF_Stat : 11|4@0+ (1,0) [0|15] "SED"  APIM_CDC,HUD_ADV,APIM,APIM_CISM,APIM_CIM,IPC
 SG_ Tire_Press_LF_Stat : 15|4@0+ (1,0) [0|15] "SED"  APIM_CDC,HUD_ADV,APIM,APIM_CISM,APIM_CIM,IPC
 SG_ Tire_Press_System_Stat : 7|4@0+ (1,0) [0|15] "SED"  APIM_CDC,APIM,APIM_CISM,APIM_CIM,IPC
 SG_ Tire_Press_Telltale : 3|2@0+ (1,0) [0|3] "SED"  APIM_CDC,APIM,APIM_CISM,APIM_CIM,IPC

BO_ 986 Personality_APIM_Data3: 8 APIM
 SG_ PsngrLoad_M_Rq : 33|10@0+ (1,0) [0|1021] "kilogram"  GWM
 SG_ VehPayloadScrn_D_Rq : 36|3@0+ (1,0) [0|7] "SED"  GWM
 SG_ Trlr_M_Rq : 31|11@0+ (10,0) [0|20450] "kilogram"  GWM
 SG_ VehPayloadTare_D_Rq : 17|1@0+ (1,0) [0|1] "SED"  GWM
 SG_ VehFalr_D_Rq : 20|3@0+ (1,0) [0|7] "SED"  GWM
 SG_ TailLghtLoadMde_D_Rq : 23|3@0+ (1,0) [0|7] "SED"  GWM
 SG_ LightAmbIntsty_No_Rq : 15|8@0+ (1,0) [0|255] "unitless"  GWM
 SG_ LightAmbColor_No_Rq : 7|8@0+ (1,0) [0|255] "Discrete"  GWM

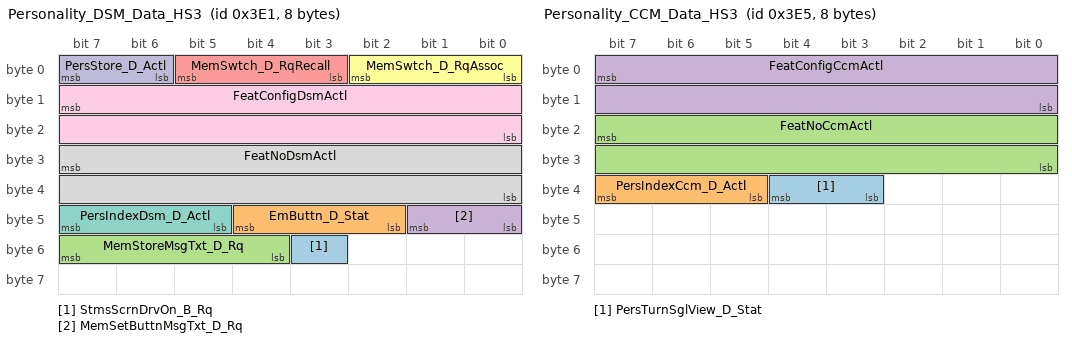
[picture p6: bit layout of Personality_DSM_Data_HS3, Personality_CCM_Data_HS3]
BO_ 993 Personality_DSM_Data_HS3: 8 GWM
 SG_ StmsScrnDrvOn_B_Rq : 51|1@0+ (1,0) [0|1] "SED"  APIM_CDC,APIM,APIM_CIM,APIM_CISM
 SG_ EmButtn_D_Stat : 44|3@0+ (1,0) [0|7] "SED"  APIM_CDC,APIM,APIM_CIM,APIM_CISM
 SG_ MemStoreMsgTxt_D_Rq : 55|4@0+ (1,0) [0|15] "SED"  APIM_CDC,APIM_CIM,IPC
 SG_ MemSetButtnMsgTxt_D_Rq : 41|2@0+ (1,0) [0|3] "SED"  APIM_CDC,APIM_CIM,IPC
 SG_ MemSwtch_D_RqRecall : 5|3@0+ (1,0) [0|7] "SED" Vector__XXX
 SG_ MemSwtch_D_RqAssoc : 2|3@0+ (1,0) [0|7] "SED" Vector__XXX
 SG_ PersIndexDsm_D_Actl : 47|3@0+ (1,0) [0|7] "SED"  APIM_CDC,APIM,APIM_CIM,APIM_CISM,IPC
 SG_ FeatNoDsmActl : 31|16@0+ (1,0) [0|65535] "Number"  APIM_CDC,APIM,APIM_CIM,APIM_CISM,IPC
 SG_ FeatConfigDsmActl : 15|16@0+ (1,0) [0|65535] "Undefined"  APIM_CDC,APIM,APIM_CIM,APIM_CISM,IPC
 SG_ PersStore_D_Actl : 7|2@0+ (1,0) [0|3] "SED"  APIM_CDC,APIM,APIM_CIM,APIM_CISM

BO_ 710 BEZEL_RDISP_WORD_Tx_HS3: 8 GWM
 SG_ BEZEL_RDISP_WORD_Tx : 7|64@0+ (1,0) [0|1.84467440737096E+019] "unitless"  APIM_CDC,APIM,APIM_CISM,APIM_CIM

BO_ 1814 TesterPhysicalReqGWM_H3: 8 TSTR
 SG_ TesterPhysicalReqGWM_H3 : 7|64@0+ (1,0) [0|1.84467E+019] "unitless"  GWM

BO_ 997 Personality_CCM_Data_HS3: 8 GWM
 SG_ PersTurnSglView_D_Stat : 36|2@0+ (1,0) [0|3] "SED"  APIM_CDC,APIM,APIM_CISM,APIM_CIM
 SG_ PersIndexCcm_D_Actl : 39|3@0+ (1,0) [0|7] "SED"  APIM_CDC,APIM,APIM_CIM,APIM_CISM,HUD_ADV,IPC
 SG_ FeatNoCcmActl : 23|16@0+ (1,0) [0|65535] "Number"  APIM_CDC,APIM,APIM_CIM,APIM_CISM,HUD_ADV,IPC
 SG_ FeatConfigCcmActl : 7|16@0+ (1,0) [0|65535] "Undefined"  APIM_CDC,APIM,APIM_CIM,APIM_CISM,HUD_ADV,IPC

BO_ 487 ACU_Request_Signals: 8 ACM
 SG_ Aioc_SetExtSrcOutpMd_Rq : 31|4@0+ (1,0) [0|15] "SED"  GENERIC

BO_ 464 ACU_Request_Signals_2: 8 ACM
 SG_ SdarsSampleRate_D_Rq : 31|2@0+ (1,0) [0|3] "SED"  APIM
 SG_ SDARS_DirectChannel_Rq : 9|10@0+ (1,0) [0|1023] "unitless"  APIM

BO_ 864 Clmt_Button_Stat1_HS3: 8 GWM
 SG_ MdeMnu_Buttn_Stat : 58|1@0+ (1,0) [0|1] "SED"  APIM_CDC,APIM,APIM_CIM,APIM_CISM
 SG_ Front_AUTO_Blwr_Lvl : 60|2@0+ (1,0) [0|3] "SED"  APIM_CDC,APIM,APIM_CIM,APIM_CISM
 SG_ RearMnu_Buttn_Stat : 48|1@0+ (1,0) [0|1] "SED"  APIM_CDC,APIM,APIM_CIM,APIM_CISM
 SG_ FrontMnu_Buttn_Stat : 49|1@0+ (1,0) [0|1] "SED"  APIM_CDC,APIM,APIM_CIM,APIM_CISM
 SG_ DrvrFcsdMde_Btn_Stt : 57|2@0+ (1,0) [0|3] "SED"  APIM_CDC,APIM,APIM_CIM,APIM_CISM
 SG_ RHS_Cond_Seat_Status : 63|3@0+ (1,0) [0|7] "SED"  APIM_CDC,APIM,APIM_CIM,APIM_CISM,IPC
 SG_ LHS_Cond_Seat_Status : 10|3@0+ (1,0) [0|7] "SED"  APIM_CDC,APIM,APIM_CIM,APIM_CISM,HUD_ADV,IPC
 SG_ Htd_Strg_Whl_Status : 27|2@0+ (1,0) [0|3] "SED"  APIM_CDC,APIM,APIM_CIM,APIM_CISM,HUD_ADV,IPC
 SG_ Htd_Strg_Whl_Btn_Stt : 29|2@0+ (1,0) [0|3] "SED"  APIM_CDC,APIM,APIM_CIM,APIM_CISM,IPC
 SG_ Defrost_Btn_Stt : 3|2@0+ (1,0) [0|3] "SED"  APIM_CDC,APIM,APIM_CIM,APIM_CISM,IPC
 SG_ CC_Fr_Btn_User_Adj : 15|5@0+ (1,0) [0|31] "SED"  APIM_CDC,APIM,APIM_CIM,APIM_CISM,HUD_ADV
 SG_ RHS_Htd_Seat_Btn_Stt : 53|2@0+ (1,0) [0|3] "SED"  APIM_CDC,APIM_CIM,IPC
 SG_ RHS_Cld_Seat_Btn_Stt : 55|2@0+ (1,0) [0|3] "SED"  APIM_CDC,APIM,APIM_CIM,APIM_CISM,IPC
 SG_ Outside_Btn_Stt : 47|2@0+ (1,0) [0|3] "SED"  IPC
 SG_ LHS_Htd_Seat_Btn_Stt : 39|2@0+ (1,0) [0|3] "SED"  APIM_CDC,APIM,APIM_CIM,APIM_CISM,IPC
 SG_ LHS_Cld_Seat_Btn_Stt : 25|2@0+ (1,0) [0|3] "SED"  APIM_CDC,APIM,APIM_CIM,APIM_CISM,IPC
 SG_ Htd_Frt_Wsh_Btn_Stt : 31|2@0+ (1,0) [0|3] "SED"  APIM_CDC,APIM,APIM_CIM,APIM_CISM,HUD_ADV,IPC
 SG_ Auto_Recirc_Btn_Stt : 5|2@0+ (1,0) [0|3] "SED"  IPC
 SG_ Recirc_Btn_Stt : 41|2@0+ (1,0) [0|3] "SED"  APIM_CDC,APIM,APIM_CIM,APIM_CISM,HUD_ADV,IPC
 SG_ Rear_Defrost_Btn_Stt : 43|2@0+ (1,0) [0|3] "SED"  APIM_CDC,APIM,APIM_CIM,APIM_CISM,HUD_ADV,IPC
 SG_ My_Temp_Btn_Stt : 33|2@0+ (1,0) [0|3] "SED"  APIM_CDC,APIM,APIM_CIM,APIM_CISM,HUD_ADV,IPC
 SG_ Max_Defrost_Btn_Stt : 35|2@0+ (1,0) [0|3] "SED"  APIM_CDC,APIM,APIM_CIM,APIM_CISM,HUD_ADV,IPC
 SG_ Max_AC_Btn_Stt : 37|2@0+ (1,0) [0|3] "SED"  APIM_CDC,APIM,APIM_CIM,APIM_CISM,HUD_ADV,IPC
 SG_ Front_AUTO_Label : 19|2@0+ (1,0) [0|3] "SED"  APIM_CDC,APIM,APIM_CIM,APIM_CISM,HUD_ADV,IPC
 SG_ Windscreen_Btn_Stt : 51|2@0+ (1,0) [0|3] "SED"  APIM_CDC,APIM,APIM_CIM,APIM_CISM,IPC
 SG_ Panel_Btn_Stt : 45|2@0+ (1,0) [0|3] "SED"  APIM_CDC,APIM,APIM_CIM,APIM_CISM,HUD_ADV,IPC
 SG_ Front_Power_Btn_Stt : 17|2@0+ (1,0) [0|3] "SED"  APIM_CDC,APIM,APIM_CIM,APIM_CISM,HUD_ADV,IPC
 SG_ Front_AUTO_Btn_Stt : 21|2@0+ (1,0) [0|3] "SED"  APIM_CDC,APIM,APIM_CIM,APIM_CISM,HUD_ADV,IPC
 SG_ Floor_Btn_Stt : 23|2@0+ (1,0) [0|3] "SED"  APIM_CDC,APIM,APIM_CIM,APIM_CISM,HUD_ADV,IPC
 SG_ Dual_Button_Stt : 1|2@0+ (1,0) [0|3] "SED"  APIM_CDC,APIM,APIM_CIM,APIM_CISM,HUD_ADV,IPC
 SG_ AC_Btn_Stt : 7|2@0+ (1,0) [0|3] "SED"  APIM_CDC,APIM,APIM_CIM,APIM_CISM,HUD_ADV,IPC

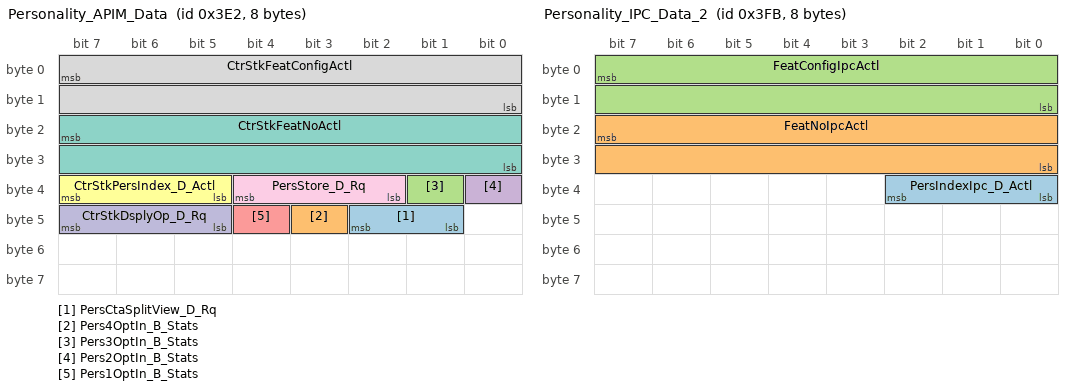
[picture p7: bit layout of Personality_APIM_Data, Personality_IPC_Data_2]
BO_ 994 Personality_APIM_Data: 8 APIM
 SG_ PersCtaSplitView_D_Rq : 42|2@0+ (1,0) [0|3] "SED"  GWM
 SG_ Pers4OptIn_B_Stats : 43|1@0+ (1,0) [0|1] "SED"  GWM
 SG_ Pers3OptIn_B_Stats : 33|1@0+ (1,0) [0|1] "SED"  GWM
 SG_ Pers2OptIn_B_Stats : 32|1@0+ (1,0) [0|1] "SED"  GWM
 SG_ Pers1OptIn_B_Stats : 44|1@0+ (1,0) [0|1] "SED"  GWM
 SG_ CtrStkPersIndex_D_Actl : 39|3@0+ (1,0) [0|7] "SED"  DSP,IPC,ACM,GWM
 SG_ CtrStkFeatNoActl : 23|16@0+ (1,0) [0|65535] "Undefined"  IPC,GWM
 SG_ CtrStkFeatConfigActl : 7|16@0+ (1,0) [0|65535] "Undefined"  IPC,GWM
 SG_ PersStore_D_Rq : 36|3@0+ (1,0) [0|7] "SED"  GWM
 SG_ CtrStkDsplyOp_D_Rq : 47|3@0+ (1,0) [0|7] "SED"  DSP,IPC,ACM,GWM

BO_ 1822 TesterPhysicalResGWM_HS3: 8 GWM
 SG_ TesterPhysicalResGWM_H3 : 7|64@0+ (1,0) [0|1.84467E+019] "unitless"  TSTR

BO_ 394 ACCDATA_3_HS3: 8 GWM
 SG_ AccStopStat_D_Dsply : 41|2@0+ (1,0) [0|3] "SED"  APIM_CDC,HUD_ADV,IPC,APIM_CIM
 SG_ AccTrgDist2_D_Dsply : 27|4@0+ (1,0) [0|15] "SED"  APIM_CDC,HUD_ADV,APIM_CIM,IPC
 SG_ AccStopRes_B_Dsply : 54|1@0+ (1,0) [0|1] "SED"  APIM_CDC,HUD_ADV,APIM_CIM,IPC
 SG_ TjaWarn_D_Rq : 50|3@0+ (1,0) [0|7] "SED"  APIM_CDC,HUD_ADV,APIM_CIM,IPC
 SG_ Tja_D_Stat : 44|3@0+ (1,0) [0|7] "SED"  APIM_CDC,HUD_ADV,APIM_CIM,IPC
 SG_ IaccLamp_D_Rq : 46|2@0+ (1,0) [0|3] "SED"  APIM_CDC,APIM,APIM_CIM,APIM_CISM,HUD_ADV,IPC
 SG_ AccMsgTxt_D2_Rq : 31|4@0+ (1,0) [0|15] "SED"  APIM_CDC,HUD_ADV,APIM_CIM,IPC
 SG_ TjaMsgTxt_D_Dsply : 53|3@0+ (1,0) [0|7] "SED"  APIM_CDC,APIM_CIM,HUD_ADV,IPC
 SG_ HaDsply_No_Cnt : 4|4@0+ (1,0) [0|15] "unitless"  APIM_CDC,IPC,APIM_CIM
 SG_ FcwDeny_B_Dsply : 10|1@0+ (1,0) [0|1] "SED"  APIM_CDC,APIM_CIM,IPC
 SG_ FcwMemStat_B_Actl : 13|1@0+ (1,0) [0|1] "SED"  APIM_CDC,APIM_CIM,IPC
 SG_ AccTGap_B_Dsply : 35|1@0+ (1,0) [0|1] "SED"  APIM_CDC,HUD_ADV,APIM_CIM,IPC
 SG_ CadsAlignIncplt_B_Actl : 11|1@0+ (1,0) [0|1] "SED"  APIM_CDC,APIM_CIM,IPC
 SG_ AccFllwMde_B_Dsply : 17|1@0+ (1,0) [0|1] "SED"  APIM_CDC,HUD_ADV,APIM_CIM,IPC
 SG_ CadsRadrBlck_B_Actl : 22|1@0+ (1,0) [0|1] "SED"  APIM_CDC,APIM_CIM,IPC
 SG_ CmbbPostEvnt_B_Dsply : 15|1@0+ (1,0) [0|1] "SED"  APIM_CDC,APIM_CIM,IPC
 SG_ AccStopMde_B_Dsply : 0|1@0+ (1,0) [0|1] "SED"  APIM_CDC,HUD_ADV,APIM_CIM,IPC
 SG_ FcwMemSens_D_Actl : 20|2@0+ (1,0) [0|3] "SED"  APIM_CDC,APIM_CIM,IPC
 SG_ FcwMsgTxt_D_Rq : 7|3@0+ (1,0) [0|7] "SED"  APIM_CDC,APIM_CIM,IPC
 SG_ AccTGap_D_Dsply : 34|3@0+ (1,0) [0|7] "SED"  APIM_CDC,HUD_ADV,APIM_CIM,IPC
 SG_ AccMemEnbl_B_RqDrv : 36|1@0+ (1,0) [0|1] "SED"  APIM_CDC,APIM_CIM,IPC
 SG_ HaDsply_No_Cs : 63|8@0+ (1,0) [0|255] "unitless"  APIM_CDC,IPC,APIM_CIM
 SG_ AccWarn_D_Dsply : 39|2@0+ (1,0) [0|3] "SED"  APIM_CDC,HUD_ADV,APIM_CIM,IPC
 SG_ FcwVisblWarn_B_Rq : 47|1@0+ (1,0) [0|1] "SED"  APIM_CDC,HUD_ADV,APIM_CIM,IPC
 SG_ FcwAudioWarn_B_Rq : 8|1@0+ (1,0) [0|1] "SED"  APIM_CDC,APIM_CIM,IPC

BO_ 1068 EnginePwrData_HS3: 8 GWM
 SG_ TrlrAidMsgTxt_D_Rq : 30|5@0+ (1,0) [0|31] "SED"  APIM_CDC,APIM_CIM,IPC

BO_ 1019 Personality_IPC_Data_2: 8 IPC
 SG_ PersIndexIpc_D_Actl : 34|3@0+ (1,0) [0|7] "SED"  APIM,APIM_CISM,GWM
 SG_ FeatNoIpcActl : 23|16@0+ (1,0) [0|65535] "Number"  APIM,APIM_CISM,GWM
 SG_ FeatConfigIpcActl : 7|16@0+ (1,0) [0|65535] "unitless"  APIM,APIM_CISM,GWM

BO_ 909 Body_Info_6_HS3: 8 GWM
 SG_ IgnPsswrdDsply_B_Rq : 57|1@0+ (1,0) [0|1] "SED"  APIM_CDC,APIM,APIM_CIM,APIM_CISM,IPC
 SG_ ElPwPoint_D_Rq : 59|2@0+ (1,0) [0|3] "SED"  GENERIC
 SG_ PoliceIdlMde_D_Stat : 55|4@0+ (1,0) [0|15] "SED"  APIM_CDC,APIM_CIM,IPC
 SG_ DrLatchMsgTxt_D_Rq : 43|3@0+ (1,0) [0|7] "SED"  APIM_CDC,APIM_CIM,IPC
 SG_ WiprFront_D_Stat2 : 63|4@0+ (1,0) [0|15] "SED"  APIM_CDC,APIM,APIM_CIM,APIM_CISM
 SG_ HazrdLght_B_Stat : 56|1@0+ (1,0) [0|1] "SED"  APIM_CDC,APIM,APIM_CIM,APIM_CISM
 SG_ TurnLghtSwtch_D_Stat2 : 49|2@0+ (1,0) [0|3] "SED"  APIM_CDC,APIM_CIM,IPC
 SG_ HeadLghtHiPrmsn_D_Stat : 51|2@0+ (1,0) [0|3] "SED"  GENERIC
 SG_ SecurityMsgTxt_D_Rq : 47|2@0+ (1,0) [0|3] "SED" Vector__XXX
 SG_ SteWhlLckMsgTxt_D_Rq : 25|2@0+ (1,0) [0|3] "SED"  APIM_CDC,APIM_CIM,IPC
 SG_ immoMsgTxt_D_Rq : 39|4@0+ (1,0) [0|15] "SED"  APIM_CDC,APIM_CIM,IPC
 SG_ PrsnlDevcChrgEnbl_B_Rq : 40|1@0+ (1,0) [0|1] "SED"  APIM_CDC,APIM,APIM_CIM,APIM_CISM,WCM
 SG_ PrmtrAlrmEvnt_D_Stat : 35|4@0+ (1,0) [0|15] "SED" Vector__XXX
 SG_ TracKeyMde_D_Stat : 45|2@0+ (1,0) [0|3] "SED"  APIM_CDC,APIM_CIM,IPC
 SG_ Keycode_Status : 15|20@0+ (1,0) [0|1048575] "unitless"  APIM_CDC,APIM_CIM,IPC
 SG_ PEBackupSlot_Stats : 27|2@0+ (1,0) [0|3] "SED"  APIM_CDC,APIM_CIM,IPC
 SG_ KeyMykeyTot_No_Cnt : 3|4@0+ (1,0) [0|15] "Counts"  APIM_CDC,APIM_CIM,ACM,IPC
 SG_ KeyAdmnTot_No_Cnt : 7|4@0+ (1,0) [0|15] "Counts"  APIM_CDC,APIM_CIM,IPC

BO_ 1824 TesterPhysicalReqIPC: 8 TSTR
 SG_ TesterPhysicalReqIPC : 7|64@0+ (1,0) [0|1.84467E+019] "unitless"  IPC

BO_TX_BU_ 867 : APIM_CDC,IPC;
BO_TX_BU_ 866 : APIM_CDC,APIM_CIM,APIM_CISM,APIM;
BO_TX_BU_ 402 : APIM,APIM_CDC,APIM_CISM,APIM_CIM;
BO_TX_BU_ 778 : APIM_CDC,APIM_CIM,IPC;
BO_TX_BU_ 1002 : APIM_CDC,APIM_CIM,APIM_CISM,APIM;
BO_TX_BU_ 986 : APIM_CDC,APIM_CIM,APIM_CISM,APIM;
BO_TX_BU_ 487 : APIM_CISM,ACM;
BO_TX_BU_ 994 : APIM_CDC,APIM_CIM,APIM_CISM,APIM;
BO_TX_BU_ 1019 : APIM_CDC,IPC;
CM_ SG_ 709 DSPAMP_RDISP_WORD_Tx "Object:BezelDiagnostics.DSP_Bezel_Diag_Data";
CM_ SG_ 552 DSP_Treble_St "Object Audio.Treble.St

Level -7..0..7";
CM_ SG_ 552 DSP_VoiceFBVolume_Up "Object AudioControl.DSP_VR_Vol_updated";
CM_ SG_ 552 DSP_VoiceFBVolume_St "Object.VolumeControl.DSP_VR_Vol_Level.St 
0x0 No Volume
0x1 Vol_Step1
0x2 Vol_Step2
0x3 Vol_Step3
Cont.
0x1E Vol_Step30";
CM_ SG_ 552 DSP_TAVolume_Up "Object Audio.DSP_TA_Vol_Updated
Indicate user value recalls if the value is set to lower/upper border ";
CM_ SG_ 552 DSP_TAVolume_St "Object.VolumeControl.DSP_TA_Vol_Level.St

0x0 No Volume
0x1 Vol_Step1
0x2 Vol_Step2
0x3 Vol_Step3
Cont.
0x1E Vol_Step30";
CM_ SG_ 552 DSP_Shaker_St "Method DSP_Shaker.St";
CM_ SG_ 552 DSP_Reg_St "Object Tuner.REG";
CM_ SG_ 552 DSP_PhoneVolume_Up "Object.VolumeControl.DSP_Phone_Vol_Updated
";
CM_ SG_ 552 DSP_PhoneVolume_St "Object.VolumeControl.DSP_Phone_Vol_Level.St

0x0 No Volume
0x1 Vol_Step1
0x2 Vol_Step2
0x3 Vol_Step3
Cont.
0x1E Vol_Step30";
CM_ SG_ 552 DSP_NavCmdVolume_Up "Object Audio.NavCmdVolume_UP. DSP_Prompt_Vol_Updated
";
CM_ SG_ 552 DSP_NavCmdVolume_St "Object Audio.NavCmdVolume. DSP_Prompt_Vol_Level.St

0x0 No Volume
0x1 Vol_Step1
0x2 Vol_Step2
0x3 Vol_Step3
Cont.
0x1E Vol_Step30";
CM_ SG_ 552 DSP_Midrange_St "MidRange.St

Level -7..0..7";
CM_ SG_ 552 DSP_Fader_St "Object Audio.Fader

Fade.St

Level -7..0..7";
CM_ SG_ 552 DSP_DSPProgram_St "Object Audio.DSPProgram
";
CM_ SG_ 552 DSP_DSP_St "Object Audio.DSP

";
CM_ SG_ 552 DSP_Bass_St "Object Audio.Bass.St

Level -7..0..7";
CM_ SG_ 552 DSP_Balance_St "Object Audio.Balance.St

Level -7..0..7";
CM_ SG_ 552 DSP_AVC_St "Object Audio.AVC
Off, Level 1 .. Level 7

Object.AudioSettings.DSP_Speed_Comp_Vol.St 
";
CM_ SG_ 552 Audio_Demo_Status "Object.AudioSettings.Audio_Demo_Status";
CM_ BO_ 967 "2008' programs, Tx by IC;  updated on 5/6/05";
CM_ SG_ 867 LHS_Temp_Disp_Digit3 "Added for MY 08";
CM_ SG_ 867 LHS_Temp_Disp_Digit2 "Added for MY 08";
CM_ SG_ 867 LHS_Temp_Disp_Digit1 "Added for MY 08";
CM_ SG_ 867 EATC_LHS_Unit "Added for MY 08";
CM_ BO_ 866 "APIM Tx";
CM_ SG_ 865 RHS_Temp_Display_Digit3 "Added for MY 08";
CM_ SG_ 865 RHS_Temp_Display_Digit2 "Added for MY 08";
CM_ SG_ 865 RHS_Temp_Display_Digit1 "Added for MY 08";
CM_ SG_ 865 LHS_Temp_Display_Digit3 "Added for MY 08";
CM_ SG_ 865 LHS_Temp_Display_Digit2 "Added for MY 08";
CM_ SG_ 865 LHS_Temp_Display_Digit1 "Added for MY 08";
CM_ SG_ 865 EATC_RHS_Units "Added for MY 08";
CM_ SG_ 865 EATC_LHS_Units "Added for MY 08";
CM_ SG_ 1046 TCMode "Signal data set to 0x0 for ABS only vehicle option content";
CM_ SG_ 1046 DrvAntiLckLamp_D_Rq "update value table v8.34, not align w/GSDB, need etracker.  ABS & IPC implemented as updated.";
CM_ SG_ 1046 BpedMove_D_Actl "CCMGenSigTimeoutTime=1000";
CM_ SG_ 534 BrkObdData_No_Actl "Signal not transmitted on gas, diesel and HEV.  Only supported on PHEV.";
CM_ SG_ 534 BrkObdIndex_No_Actl "Signal not transmitted on gas, diesel and HEV.  Only supported on PHEV.";
CM_ SG_ 534 WhlRotatRr_No_Cnt "DCR 1833 to update Tx from GWM to EP100ms. Wheel Count signals are used by complex algorithm to determine Tire Pressure by Location & can't change from 20msec. (jweinfur)";
CM_ SG_ 534 WhlRotatRl_No_Cnt "DCR 1833 to update Tx from GWM to EP100ms. Wheel Count signals are used by complex algorithm to determine Tire Pressure by Location & can't change from 20msec. (jweinfur)";
CM_ SG_ 534 WhlRotatFr_No_Cnt "DCR 1833 to update Tx from GWM to EP100ms. Wheel Count signals are used by complex algorithm to determine Tire Pressure by Location & can't change from 20msec. (jweinfur)";
CM_ SG_ 534 WhlRotatFl_No_Cnt "DCR 1833 to update Tx from GWM to EP100ms. Wheel Count signals are used by complex algorithm to determine Tire Pressure by Location & can't change from 20msec. (jweinfur)";
CM_ BO_ 402 "FCDIM,APIM Tx";
CM_ SG_ 946 Dimming_Lvl "Refer to Vehicle Interior Illum Dimming Ctrl Sys Eng Spec, Table 2

";
CM_ SG_ 946 PrkBrkActv_B_Actl "Signal not transmitted on vehicles with electric park brake. ";
CM_ SG_ 1093 StopLamp_B_RqTrlrBrk "Signal not transmitted on all variants.";
CM_ BO_ 948 "$3B4 used by CGEA SPDJB";
CM_ BO_ 986 "APIM Tx";
CM_ BO_ 710 "TP message(Transport Protocol), Rx's HS3 APIM & MFD, transmitted immediately";
CM_ SG_ 487 Aioc_SetExtSrcOutpMd_Rq "Object Audio Management Audio Switch.SetBVCOutputMode";
CM_ SG_ 394 HaDsply_No_Cnt "Signal not transmitted on gas variants.";
CM_ SG_ 394 HaDsply_No_Cs "Signal not transmitted on gas variants.";
BA_DEF_ BO_  "FrameRouting" STRING ;
BA_DEF_ BO_  "NetworkInitialization" ENUM  "No","Yes";
BA_DEF_ BO_  "GenMsgStartDelayTime" INT 0 10000;
BA_DEF_ BO_  "GenMsgNrOfRepetition" INT 0 100;
BA_DEF_ BO_  "GenMsgDelayTime" INT 0 1000;
BA_DEF_ BO_  "GenMsgCycleTime" INT 0 100000;
BA_DEF_ BO_  "GenMsgSendType" ENUM  "FixedPeriodic","Event","EnabledPeriodic","NotUsed","NotUsed","EventPeriodic","NotUsed","NotUsed","NoMsgSendType";
BA_DEF_ SG_  "U_P702_MY2024_Tx" ENUM  "No","Yes";
BA_DEF_ SG_  "U_V710_MY2023_Tx" ENUM  "No","Yes";
BA_DEF_ SG_  "U_CDX74X_MY2024_Tx" ENUM  "No","Yes";
BA_DEF_ SG_  "U_CDX707_MY2023_Tx" ENUM  "No","Yes";
BA_DEF_ SG_  "U_P708_MY2023_Tx" ENUM  "No","Yes";
BA_DEF_ SG_  "U_V713AV_MY2022_Tx" ENUM  "No","Yes";
BA_DEF_ SG_  "U_V713N_MY2022_Tx" ENUM  "No","Yes";
BA_DEF_ SG_  "ECGUsedTxSignal" ENUM  "No","Yes";
BA_DEF_ SG_  "U_P702_MY2024_Rx" ENUM  "No","Yes";
BA_DEF_ SG_  "U_V710_MY2023_Rx" ENUM  "No","Yes";
BA_DEF_ SG_  "U_CDX74X_MY2024_Rx" ENUM  "No","Yes";
BA_DEF_ SG_  "U_CDX707_MY2023_Rx" ENUM  "No","Yes";
BA_DEF_ SG_  "U_P708_MY2023_Rx" ENUM  "No","Yes";
BA_DEF_ SG_  "U_V713AV_MY2022_Rx" ENUM  "No","Yes";
BA_DEF_ SG_  "U_V713N_MY2022_Rx" ENUM  "No","Yes";
BA_DEF_ SG_  "ECGUsedRxSignal" ENUM  "No","Yes";
BA_DEF_ SG_  "UsedOnPgmDBC" ENUM  "No","Yes";
BA_DEF_ SG_  "ContentDependant" ENUM  "No","Yes";
BA_DEF_ SG_  "GenSigStartValue" HEX 0 268435455;
BA_DEF_ SG_  "MetaData" ENUM  "No","Yes";
BA_DEF_ SG_  "WakeupSignal" ENUM  "No","Yes";
BA_DEF_ SG_  "GenSigInactiveValue" INT 0 100000;
BA_DEF_ SG_  "GenSigSendType" ENUM  "Cyclic","OnWrite","vector_leerstring","OnChange","vector_leerstring","IfActive","vector_leerstring","NoSigSendType";
BA_DEF_ BO_  "TpTxIndex" INT 0 536870911;
BA_DEF_ BO_  "OvtpPushApplication" ENUM  "FALSE","TRUE";
BA_DEF_ BO_  "SCP_FreshnessValueLength" INT 0 512;
BA_DEF_ BO_  "SCP_DataId" INT 0 17663;
BA_DEF_ BO_  "SCP_FreshnessValueTxLength" INT 0 512;
BA_DEF_ BO_  "SCP_AuthInfoTxLength" INT 0 512;
BA_DEF_ BO_  "SC_Message" ENUM  "No","Yes";
BA_DEF_ BO_  "GenMsgRoutingTimeoutTime" INT 0 5000;
BA_DEF_ BO_  "MessageGateway" ENUM  "No","Yes";
BA_DEF_ BO_  "NmAsrMessage" ENUM  "No","Yes";
BA_DEF_ BO_  "DiagState" ENUM  "No","Yes";
BA_DEF_ BO_  "DiagRequest" ENUM  "No","Yes";
BA_DEF_ BO_  "DiagResponse" ENUM  "No","Yes";
BA_DEF_ BO_  "NmMessage" ENUM  "No","Yes";
BA_DEF_ BO_  "GenMsgILSupport" ENUM  "No","Yes";
BA_DEF_DEF_  "FrameRouting" "";
BA_DEF_DEF_  "NetworkInitialization" "Yes";
BA_DEF_DEF_  "GenMsgStartDelayTime" 0;
BA_DEF_DEF_  "GenMsgNrOfRepetition" 1;
BA_DEF_DEF_  "GenMsgDelayTime" 20;
BA_DEF_DEF_  "GenMsgCycleTime" 0;
BA_DEF_DEF_  "GenMsgSendType" "NoMsgSendType";
BA_DEF_DEF_  "U_P702_MY2024_Tx" "No";
BA_DEF_DEF_  "U_V710_MY2023_Tx" "No";
BA_DEF_DEF_  "U_CDX74X_MY2024_Tx" "No";
BA_DEF_DEF_  "U_CDX707_MY2023_Tx" "No";
BA_DEF_DEF_  "U_P708_MY2023_Tx" "No";
BA_DEF_DEF_  "U_V713AV_MY2022_Tx" "No";
BA_DEF_DEF_  "U_V713N_MY2022_Tx" "No";
BA_DEF_DEF_  "ECGUsedTxSignal" "No";
BA_DEF_DEF_  "U_P702_MY2024_Rx" "No";
BA_DEF_DEF_  "U_V710_MY2023_Rx" "No";
BA_DEF_DEF_  "U_CDX74X_MY2024_Rx" "No";
BA_DEF_DEF_  "U_CDX707_MY2023_Rx" "No";
BA_DEF_DEF_  "U_P708_MY2023_Rx" "No";
BA_DEF_DEF_  "U_V713AV_MY2022_Rx" "No";
BA_DEF_DEF_  "U_V713N_MY2022_Rx" "No";
BA_DEF_DEF_  "ECGUsedRxSignal" "No";
BA_DEF_DEF_  "UsedOnPgmDBC" "Yes";
BA_DEF_DEF_  "ContentDependant" "No";
BA_DEF_DEF_  "GenSigStartValue" 0;
BA_DEF_DEF_  "MetaData" "No";
BA_DEF_DEF_  "WakeupSignal" "No";
BA_DEF_DEF_  "GenSigInactiveValue" 0;
BA_DEF_DEF_  "GenSigSendType" "NoSigSendType";
BA_DEF_DEF_  "TpTxIndex" 0;
BA_DEF_DEF_  "OvtpPushApplication" "FALSE";
BA_DEF_DEF_  "SCP_FreshnessValueLength" 64;
BA_DEF_DEF_  "SCP_DataId" 0;
BA_DEF_DEF_  "SCP_FreshnessValueTxLength" 11;
BA_DEF_DEF_  "SCP_AuthInfoTxLength" 53;
BA_DEF_DEF_  "SC_Message" "No";
BA_DEF_DEF_  "GenMsgRoutingTimeoutTime" 0;
BA_DEF_DEF_  "MessageGateway" "No";
BA_DEF_DEF_  "NmAsrMessage" "No";
BA_DEF_DEF_  "DiagState" "No";
BA_DEF_DEF_  "DiagRequest" "No";
BA_DEF_DEF_  "DiagResponse" "No";
BA_DEF_DEF_  "NmMessage" "No";
BA_DEF_DEF_  "GenMsgILSupport" "Yes";
BA_ "FrameRouting" BO_ 974 "FD1_CAN,0x36E;";
BA_ "GenMsgSendType" BO_ 810 5;
BA_ "GenMsgCycleTime" BO_ 810 1000;
BA_ "GenMsgILSupport" BO_ 1492 0;
BA_ "NmAsrMessage" BO_ 1492 1;
BA_ "GenMsgSendType" BO_ 1492 0;
BA_ "GenMsgCycleTime" BO_ 1492 1000;
BA_ "NetworkInitialization" BO_ 1492 0;
BA_ "TpTxIndex" BO_ 709 25;
BA_ "GenMsgSendType" BO_ 552 5;
BA_ "GenMsgCycleTime" BO_ 552 1000;
BA_ "FrameRouting" BO_ 967 "FD1_CAN,0x3C7;";
BA_ "FrameRouting" BO_ 1105 "FD1_CAN,0x451;FD3_CAN,0x451";
BA_ "GenMsgSendType" BO_ 867 1;
BA_ "NetworkInitialization" BO_ 867 0;
BA_ "GenMsgSendType" BO_ 866 5;
BA_ "GenMsgCycleTime" BO_ 866 1000;
BA_ "FrameRouting" BO_ 861 "MS1_CAN,0x357;";
BA_ "FrameRouting" BO_ 865 "MS1_CAN,0x356;";
BA_ "FrameRouting" BO_ 1046 "FD1_CAN,0x416;";
BA_ "FrameRouting" BO_ 534 "FD1_CAN,0x216;";
BA_ "GenMsgSendType" BO_ 402 5;
BA_ "GenMsgCycleTime" BO_ 402 1000;
BA_ "FrameRouting" BO_ 946 "FD1_CAN,0x3B3;";
BA_ "GenMsgSendType" BO_ 778 5;
BA_ "GenMsgCycleTime" BO_ 778 200;
BA_ "GenMsgSendType" BO_ 1093 0;
BA_ "GenMsgCycleTime" BO_ 1093 100;
BA_ "GenMsgILSupport" BO_ 1879 0;
BA_ "DiagRequest" BO_ 1879 1;
BA_ "GenMsgSendType" BO_ 1879 1;
BA_ "GenMsgDelayTime" BO_ 1879 0;
BA_ "NetworkInitialization" BO_ 1879 0;
BA_ "FrameRouting" BO_ 999 "MS1_CAN,0x3E7;";
BA_ "GenMsgSendType" BO_ 1002 5;
BA_ "GenMsgCycleTime" BO_ 1002 1000;
BA_ "FrameRouting" BO_ 948 "FD1_CAN,0x3B4;";
BA_ "GenMsgSendType" BO_ 986 5;
BA_ "GenMsgCycleTime" BO_ 986 1000;
BA_ "FrameRouting" BO_ 993 "MS1_CAN,0x3E1;";
BA_ "TpTxIndex" BO_ 710 26;
BA_ "FrameRouting" BO_ 710 "MS1_CAN,0x2C6;";
BA_ "GenMsgILSupport" BO_ 1814 0;
BA_ "DiagRequest" BO_ 1814 1;
BA_ "GenMsgSendType" BO_ 1814 1;
BA_ "GenMsgDelayTime" BO_ 1814 0;
BA_ "NetworkInitialization" BO_ 1814 0;
BA_ "FrameRouting" BO_ 997 "FD1_CAN,0x3E5;FD3_CAN,0x3E5";
BA_ "GenMsgSendType" BO_ 487 1;
BA_ "GenMsgSendType" BO_ 464 1;
BA_ "FrameRouting" BO_ 864 "MS1_CAN,0x355;";
BA_ "GenMsgSendType" BO_ 994 5;
BA_ "GenMsgCycleTime" BO_ 994 1000;
BA_ "GenMsgILSupport" BO_ 1822 0;
BA_ "DiagResponse" BO_ 1822 1;
BA_ "GenMsgSendType" BO_ 1822 1;
BA_ "GenMsgDelayTime" BO_ 1822 0;
BA_ "NetworkInitialization" BO_ 1822 0;
BA_ "FrameRouting" BO_ 394 "FD1_CAN,0x18A;FD3_CAN,0x18A";
BA_ "MessageGateway" BO_ 1068 1;
BA_ "GenMsgSendType" BO_ 1068 5;
BA_ "GenMsgCycleTime" BO_ 1068 250;
BA_ "GenMsgDelayTime" BO_ 1068 10;
BA_ "GenMsgSendType" BO_ 1019 5;
BA_ "GenMsgCycleTime" BO_ 1019 1000;
BA_ "FrameRouting" BO_ 909 "FD1_CAN,0x38D;";
BA_ "GenMsgILSupport" BO_ 1824 0;
BA_ "DiagRequest" BO_ 1824 1;
BA_ "GenMsgSendType" BO_ 1824 1;
BA_ "GenMsgDelayTime" BO_ 1824 0;
BA_ "NetworkInitialization" BO_ 1824 0;
BA_ "U_V713AV_MY2022_Rx" SG_ 974 EngExhMdeHrStrt_D_Stat 1;
BA_ "U_P708_MY2023_Rx" SG_ 974 EngExhMdeHrStrt_D_Stat 1;
BA_ "U_V710_MY2023_Rx" SG_ 974 EngExhMdeHrStrt_D_Stat 1;
BA_ "U_P702_MY2024_Rx" SG_ 974 EngExhMdeHrStrt_D_Stat 1;
BA_ "U_V713AV_MY2022_Rx" SG_ 974 EngExhMdeHrEnd_D_Stat 1;
BA_ "U_P708_MY2023_Rx" SG_ 974 EngExhMdeHrEnd_D_Stat 1;
BA_ "U_V710_MY2023_Rx" SG_ 974 EngExhMdeHrEnd_D_Stat 1;
BA_ "U_P702_MY2024_Rx" SG_ 974 EngExhMdeHrEnd_D_Stat 1;
BA_ "U_V713AV_MY2022_Rx" SG_ 974 EngExhMdeHrEnbl_D_Stat 1;
BA_ "U_P708_MY2023_Rx" SG_ 974 EngExhMdeHrEnbl_D_Stat 1;
BA_ "U_V710_MY2023_Rx" SG_ 974 EngExhMdeHrEnbl_D_Stat 1;
BA_ "U_P702_MY2024_Rx" SG_ 974 EngExhMdeHrEnbl_D_Stat 1;
BA_ "U_V710_MY2023_Rx" SG_ 974 DcacOut_Pw_DsplyMx 1;
BA_ "U_P708_MY2023_Rx" SG_ 974 DcacOut_Pw_DsplyMx 1;
BA_ "U_P702_MY2024_Rx" SG_ 974 DcacOut_Pw_DsplyMx 1;
BA_ "U_V710_MY2023_Rx" SG_ 974 DcacOut1_Pw_Dsply 1;
BA_ "U_P708_MY2023_Rx" SG_ 974 DcacOut1_Pw_Dsply 1;
BA_ "U_P702_MY2024_Rx" SG_ 974 DcacOut1_Pw_Dsply 1;
BA_ "U_V710_MY2023_Rx" SG_ 974 DcacOut2_Pw_Dsply 1;
BA_ "U_P708_MY2023_Rx" SG_ 974 DcacOut2_Pw_Dsply 1;
BA_ "U_P702_MY2024_Rx" SG_ 974 DcacOut2_Pw_Dsply 1;
BA_ "U_V710_MY2023_Rx" SG_ 974 DcacHw_D_Confg 1;
BA_ "U_P708_MY2023_Rx" SG_ 974 DcacHw_D_Confg 1;
BA_ "U_P702_MY2024_Rx" SG_ 974 DcacHw_D_Confg 1;
BA_ "U_V710_MY2023_Rx" SG_ 974 DcacFaltMsgTxt_D_Rq 1;
BA_ "U_P708_MY2023_Rx" SG_ 974 DcacFaltMsgTxt_D_Rq 1;
BA_ "U_P702_MY2024_Rx" SG_ 974 DcacFaltMsgTxt_D_Rq 1;
BA_ "U_V710_MY2023_Rx" SG_ 974 DcacLoFuelMsgTxt_D_Rq 1;
BA_ "U_P708_MY2023_Rx" SG_ 974 DcacLoFuelMsgTxt_D_Rq 1;
BA_ "U_P702_MY2024_Rx" SG_ 974 DcacLoFuelMsgTxt_D_Rq 1;
BA_ "U_V710_MY2023_Rx" SG_ 974 DcacEngOnMsgTxt_D_Rq 1;
BA_ "U_P708_MY2023_Rx" SG_ 974 DcacEngOnMsgTxt_D_Rq 1;
BA_ "U_P702_MY2024_Rx" SG_ 974 DcacEngOnMsgTxt_D_Rq 1;
BA_ "GenSigStartValue" SG_ 974 DcacElPw_D_Stat 1;
BA_ "U_V710_MY2023_Rx" SG_ 974 DcacElPw_D_Stat 1;
BA_ "U_P708_MY2023_Rx" SG_ 974 DcacElPw_D_Stat 1;
BA_ "U_P702_MY2024_Rx" SG_ 974 DcacElPw_D_Stat 1;
BA_ "GenSigSendType" SG_ 810 OneTEditActv_B_RqCld 3;
BA_ "U_V710_MY2023_Rx" SG_ 810 OneTEditActv_B_RqCld 1;
BA_ "U_P708_MY2023_Rx" SG_ 810 OneTEditActv_B_RqCld 1;
BA_ "U_P702_MY2024_Rx" SG_ 810 OneTEditActv_B_RqCld 1;
BA_ "ECGUsedTxSignal" SG_ 810 OneTEditActv_B_RqCld 1;
BA_ "U_V713N_MY2022_Tx" SG_ 810 OneTEditActv_B_RqCld 1;
BA_ "U_V713AV_MY2022_Tx" SG_ 810 OneTEditActv_B_RqCld 1;
BA_ "U_CDX74X_MY2024_Tx" SG_ 810 OneTEditActv_B_RqCld 1;
BA_ "U_V710_MY2023_Tx" SG_ 810 OneTEditActv_B_RqCld 1;
BA_ "WakeupSignal" SG_ 810 ExtLghtDsply_B_StatArb 1;
BA_ "GenSigSendType" SG_ 810 ExtLghtDsply_B_StatArb 3;
BA_ "U_V710_MY2023_Rx" SG_ 810 ExtLghtDsply_B_StatArb 1;
BA_ "U_P708_MY2023_Rx" SG_ 810 ExtLghtDsply_B_StatArb 1;
BA_ "U_P702_MY2024_Rx" SG_ 810 ExtLghtDsply_B_StatArb 1;
BA_ "ECGUsedTxSignal" SG_ 810 ExtLghtDsply_B_StatArb 1;
BA_ "U_V713N_MY2022_Tx" SG_ 810 ExtLghtDsply_B_StatArb 1;
BA_ "U_V713AV_MY2022_Tx" SG_ 810 ExtLghtDsply_B_StatArb 1;
BA_ "U_P708_MY2023_Tx" SG_ 810 ExtLghtDsply_B_StatArb 1;
BA_ "U_CDX74X_MY2024_Tx" SG_ 810 ExtLghtDsply_B_StatArb 1;
BA_ "U_V710_MY2023_Tx" SG_ 810 ExtLghtDsply_B_StatArb 1;
BA_ "GenSigStartValue" SG_ 1492 TRM_GWOnBoardTester 255;
BA_ "U_P708_MY2023_Tx" SG_ 1492 TRM_GWOnBoardTester 1;
BA_ "U_CDX707_MY2023_Tx" SG_ 1492 TRM_GWOnBoardTester 1;
BA_ "U_CDX74X_MY2024_Tx" SG_ 1492 TRM_GWOnBoardTester 1;
BA_ "U_V710_MY2023_Tx" SG_ 1492 TRM_GWOnBoardTester 1;
BA_ "U_P702_MY2024_Tx" SG_ 1492 TRM_GWOnBoardTester 1;
BA_ "GenSigStartValue" SG_ 1492 TRM_GWNMProxy 255;
BA_ "U_P708_MY2023_Tx" SG_ 1492 TRM_GWNMProxy 1;
BA_ "U_CDX707_MY2023_Tx" SG_ 1492 TRM_GWNMProxy 1;
BA_ "U_CDX74X_MY2024_Tx" SG_ 1492 TRM_GWNMProxy 1;
BA_ "U_V710_MY2023_Tx" SG_ 1492 TRM_GWNMProxy 1;
BA_ "U_P702_MY2024_Tx" SG_ 1492 TRM_GWNMProxy 1;
BA_ "GenSigStartValue" SG_ 1492 TRM_AutoSarNMReserved4 255;
BA_ "U_P708_MY2023_Tx" SG_ 1492 TRM_AutoSarNMReserved4 1;
BA_ "U_CDX707_MY2023_Tx" SG_ 1492 TRM_AutoSarNMReserved4 1;
BA_ "U_CDX74X_MY2024_Tx" SG_ 1492 TRM_AutoSarNMReserved4 1;
BA_ "U_V710_MY2023_Tx" SG_ 1492 TRM_AutoSarNMReserved4 1;
BA_ "U_P702_MY2024_Tx" SG_ 1492 TRM_AutoSarNMReserved4 1;
BA_ "GenSigStartValue" SG_ 1492 TRM_AutoSarNMReserved3 255;
BA_ "U_P708_MY2023_Tx" SG_ 1492 TRM_AutoSarNMReserved3 1;
BA_ "U_CDX707_MY2023_Tx" SG_ 1492 TRM_AutoSarNMReserved3 1;
BA_ "U_CDX74X_MY2024_Tx" SG_ 1492 TRM_AutoSarNMReserved3 1;
BA_ "U_V710_MY2023_Tx" SG_ 1492 TRM_AutoSarNMReserved3 1;
BA_ "U_P702_MY2024_Tx" SG_ 1492 TRM_AutoSarNMReserved3 1;
BA_ "GenSigStartValue" SG_ 1492 TRM_AutoSarNMReserved2 255;
BA_ "U_P708_MY2023_Tx" SG_ 1492 TRM_AutoSarNMReserved2 1;
BA_ "U_CDX707_MY2023_Tx" SG_ 1492 TRM_AutoSarNMReserved2 1;
BA_ "U_CDX74X_MY2024_Tx" SG_ 1492 TRM_AutoSarNMReserved2 1;
BA_ "U_V710_MY2023_Tx" SG_ 1492 TRM_AutoSarNMReserved2 1;
BA_ "U_P702_MY2024_Tx" SG_ 1492 TRM_AutoSarNMReserved2 1;
BA_ "GenSigStartValue" SG_ 1492 TRM_AutoSarNMReserved1 255;
BA_ "U_P708_MY2023_Tx" SG_ 1492 TRM_AutoSarNMReserved1 1;
BA_ "U_CDX707_MY2023_Tx" SG_ 1492 TRM_AutoSarNMReserved1 1;
BA_ "U_CDX74X_MY2024_Tx" SG_ 1492 TRM_AutoSarNMReserved1 1;
BA_ "U_V710_MY2023_Tx" SG_ 1492 TRM_AutoSarNMReserved1 1;
BA_ "U_P702_MY2024_Tx" SG_ 1492 TRM_AutoSarNMReserved1 1;
BA_ "GenSigStartValue" SG_ 1492 TRM_AutoSarNMNodeId 212;
BA_ "U_P708_MY2023_Tx" SG_ 1492 TRM_AutoSarNMNodeId 1;
BA_ "U_CDX707_MY2023_Tx" SG_ 1492 TRM_AutoSarNMNodeId 1;
BA_ "U_CDX74X_MY2024_Tx" SG_ 1492 TRM_AutoSarNMNodeId 1;
BA_ "U_V710_MY2023_Tx" SG_ 1492 TRM_AutoSarNMNodeId 1;
BA_ "U_P702_MY2024_Tx" SG_ 1492 TRM_AutoSarNMNodeId 1;
BA_ "U_P708_MY2023_Tx" SG_ 1492 TRM_AutoSarNMControl 1;
BA_ "U_CDX707_MY2023_Tx" SG_ 1492 TRM_AutoSarNMControl 1;
BA_ "U_CDX74X_MY2024_Tx" SG_ 1492 TRM_AutoSarNMControl 1;
BA_ "U_V710_MY2023_Tx" SG_ 1492 TRM_AutoSarNMControl 1;
BA_ "U_P702_MY2024_Tx" SG_ 1492 TRM_AutoSarNMControl 1;
BA_ "U_P708_MY2023_Rx" SG_ 709 DSPAMP_RDISP_WORD_Tx 1;
BA_ "U_CDX74X_MY2024_Tx" SG_ 709 DSPAMP_RDISP_WORD_Tx 1;
BA_ "U_V710_MY2023_Tx" SG_ 709 DSPAMP_RDISP_WORD_Tx 1;
BA_ "GenSigSendType" SG_ 552 ActvNseMute_D_Stat 3;
BA_ "U_V710_MY2023_Rx" SG_ 552 ActvNseMute_D_Stat 1;
BA_ "U_P708_MY2023_Rx" SG_ 552 ActvNseMute_D_Stat 1;
BA_ "U_P702_MY2024_Rx" SG_ 552 ActvNseMute_D_Stat 1;
BA_ "U_CDX74X_MY2024_Tx" SG_ 552 ActvNseMute_D_Stat 1;
BA_ "U_V710_MY2023_Tx" SG_ 552 ActvNseMute_D_Stat 1;
BA_ "GenSigSendType" SG_ 552 DSP_Treble_St 3;
BA_ "U_V710_MY2023_Rx" SG_ 552 DSP_Treble_St 1;
BA_ "U_P708_MY2023_Rx" SG_ 552 DSP_Treble_St 1;
BA_ "U_P702_MY2024_Rx" SG_ 552 DSP_Treble_St 1;
BA_ "U_CDX74X_MY2024_Tx" SG_ 552 DSP_Treble_St 1;
BA_ "U_V710_MY2023_Tx" SG_ 552 DSP_Treble_St 1;
BA_ "GenSigSendType" SG_ 552 DSP_VoiceFBVolume_Up 1;
BA_ "U_P708_MY2023_Rx" SG_ 552 DSP_VoiceFBVolume_Up 1;
BA_ "U_P702_MY2024_Rx" SG_ 552 DSP_VoiceFBVolume_Up 1;
BA_ "U_V710_MY2023_Rx" SG_ 552 DSP_VoiceFBVolume_Up 1;
BA_ "U_CDX74X_MY2024_Tx" SG_ 552 DSP_VoiceFBVolume_Up 1;
BA_ "U_V710_MY2023_Tx" SG_ 552 DSP_VoiceFBVolume_Up 1;
BA_ "U_V713N_MY2022_Rx" SG_ 552 DSP_VoiceFBVolume_St 1;
BA_ "U_P708_MY2023_Rx" SG_ 552 DSP_VoiceFBVolume_St 1;
BA_ "U_CDX74X_MY2024_Rx" SG_ 552 DSP_VoiceFBVolume_St 1;
BA_ "U_P702_MY2024_Rx" SG_ 552 DSP_VoiceFBVolume_St 1;
BA_ "U_V710_MY2023_Rx" SG_ 552 DSP_VoiceFBVolume_St 1;
BA_ "U_CDX74X_MY2024_Tx" SG_ 552 DSP_VoiceFBVolume_St 1;
BA_ "U_V710_MY2023_Tx" SG_ 552 DSP_VoiceFBVolume_St 1;
BA_ "GenSigSendType" SG_ 552 DSP_TAVolume_Up 1;
BA_ "U_P708_MY2023_Rx" SG_ 552 DSP_TAVolume_Up 1;
BA_ "U_P702_MY2024_Rx" SG_ 552 DSP_TAVolume_Up 1;
BA_ "U_V710_MY2023_Rx" SG_ 552 DSP_TAVolume_Up 1;
BA_ "U_CDX74X_MY2024_Tx" SG_ 552 DSP_TAVolume_Up 1;
BA_ "U_V710_MY2023_Tx" SG_ 552 DSP_TAVolume_Up 1;
BA_ "U_V713N_MY2022_Rx" SG_ 552 DSP_TAVolume_St 1;
BA_ "U_P708_MY2023_Rx" SG_ 552 DSP_TAVolume_St 1;
BA_ "U_CDX74X_MY2024_Rx" SG_ 552 DSP_TAVolume_St 1;
BA_ "U_P702_MY2024_Rx" SG_ 552 DSP_TAVolume_St 1;
BA_ "U_V710_MY2023_Rx" SG_ 552 DSP_TAVolume_St 1;
BA_ "U_CDX74X_MY2024_Tx" SG_ 552 DSP_TAVolume_St 1;
BA_ "U_V710_MY2023_Tx" SG_ 552 DSP_TAVolume_St 1;
BA_ "GenSigSendType" SG_ 552 DSP_Shaker_St 3;
BA_ "U_V710_MY2023_Rx" SG_ 552 DSP_Shaker_St 1;
BA_ "U_P708_MY2023_Rx" SG_ 552 DSP_Shaker_St 1;
BA_ "U_P702_MY2024_Rx" SG_ 552 DSP_Shaker_St 1;
BA_ "GenSigSendType" SG_ 552 DSP_Reg_St 3;
BA_ "U_V710_MY2023_Rx" SG_ 552 DSP_Reg_St 1;
BA_ "U_P708_MY2023_Rx" SG_ 552 DSP_Reg_St 1;
BA_ "U_P702_MY2024_Rx" SG_ 552 DSP_Reg_St 1;
BA_ "U_CDX74X_MY2024_Tx" SG_ 552 DSP_Reg_St 1;
BA_ "U_V710_MY2023_Tx" SG_ 552 DSP_Reg_St 1;
BA_ "GenSigSendType" SG_ 552 DSP_PhoneVolume_Up 1;
BA_ "U_P708_MY2023_Rx" SG_ 552 DSP_PhoneVolume_Up 1;
BA_ "U_P702_MY2024_Rx" SG_ 552 DSP_PhoneVolume_Up 1;
BA_ "U_V710_MY2023_Rx" SG_ 552 DSP_PhoneVolume_Up 1;
BA_ "U_CDX74X_MY2024_Tx" SG_ 552 DSP_PhoneVolume_Up 1;
BA_ "U_V710_MY2023_Tx" SG_ 552 DSP_PhoneVolume_Up 1;
BA_ "U_V713N_MY2022_Rx" SG_ 552 DSP_PhoneVolume_St 1;
BA_ "U_P708_MY2023_Rx" SG_ 552 DSP_PhoneVolume_St 1;
BA_ "U_CDX74X_MY2024_Rx" SG_ 552 DSP_PhoneVolume_St 1;
BA_ "U_P702_MY2024_Rx" SG_ 552 DSP_PhoneVolume_St 1;
BA_ "U_V710_MY2023_Rx" SG_ 552 DSP_PhoneVolume_St 1;
BA_ "U_CDX74X_MY2024_Tx" SG_ 552 DSP_PhoneVolume_St 1;
BA_ "U_V710_MY2023_Tx" SG_ 552 DSP_PhoneVolume_St 1;
BA_ "GenSigSendType" SG_ 552 DSP_NavCmdVolume_Up 1;
BA_ "U_P708_MY2023_Rx" SG_ 552 DSP_NavCmdVolume_Up 1;
BA_ "U_P702_MY2024_Rx" SG_ 552 DSP_NavCmdVolume_Up 1;
BA_ "U_V710_MY2023_Rx" SG_ 552 DSP_NavCmdVolume_Up 1;
BA_ "U_CDX74X_MY2024_Tx" SG_ 552 DSP_NavCmdVolume_Up 1;
BA_ "U_V710_MY2023_Tx" SG_ 552 DSP_NavCmdVolume_Up 1;
BA_ "U_V713N_MY2022_Rx" SG_ 552 DSP_NavCmdVolume_St 1;
BA_ "U_P708_MY2023_Rx" SG_ 552 DSP_NavCmdVolume_St 1;
BA_ "U_CDX74X_MY2024_Rx" SG_ 552 DSP_NavCmdVolume_St 1;
BA_ "U_P702_MY2024_Rx" SG_ 552 DSP_NavCmdVolume_St 1;
BA_ "U_V710_MY2023_Rx" SG_ 552 DSP_NavCmdVolume_St 1;
BA_ "U_CDX74X_MY2024_Tx" SG_ 552 DSP_NavCmdVolume_St 1;
BA_ "U_V710_MY2023_Tx" SG_ 552 DSP_NavCmdVolume_St 1;
BA_ "GenSigSendType" SG_ 552 DSP_Midrange_St 3;
BA_ "U_V710_MY2023_Rx" SG_ 552 DSP_Midrange_St 1;
BA_ "U_P708_MY2023_Rx" SG_ 552 DSP_Midrange_St 1;
BA_ "U_P702_MY2024_Rx" SG_ 552 DSP_Midrange_St 1;
BA_ "U_CDX74X_MY2024_Tx" SG_ 552 DSP_Midrange_St 1;
BA_ "U_V710_MY2023_Tx" SG_ 552 DSP_Midrange_St 1;
BA_ "GenSigSendType" SG_ 552 DSP_Fader_St 3;
BA_ "U_V710_MY2023_Rx" SG_ 552 DSP_Fader_St 1;
BA_ "U_P708_MY2023_Rx" SG_ 552 DSP_Fader_St 1;
BA_ "U_P702_MY2024_Rx" SG_ 552 DSP_Fader_St 1;
BA_ "U_CDX74X_MY2024_Tx" SG_ 552 DSP_Fader_St 1;
BA_ "U_V710_MY2023_Tx" SG_ 552 DSP_Fader_St 1;
BA_ "GenSigSendType" SG_ 552 DSP_DSPProgram_St 3;
BA_ "U_V710_MY2023_Rx" SG_ 552 DSP_DSPProgram_St 1;
BA_ "U_P708_MY2023_Rx" SG_ 552 DSP_DSPProgram_St 1;
BA_ "U_P702_MY2024_Rx" SG_ 552 DSP_DSPProgram_St 1;
BA_ "U_CDX74X_MY2024_Tx" SG_ 552 DSP_DSPProgram_St 1;
BA_ "U_V710_MY2023_Tx" SG_ 552 DSP_DSPProgram_St 1;
BA_ "GenSigSendType" SG_ 552 DSP_DSP_St 3;
BA_ "U_V710_MY2023_Rx" SG_ 552 DSP_DSP_St 1;
BA_ "U_P708_MY2023_Rx" SG_ 552 DSP_DSP_St 1;
BA_ "U_P702_MY2024_Rx" SG_ 552 DSP_DSP_St 1;
BA_ "U_CDX74X_MY2024_Tx" SG_ 552 DSP_DSP_St 1;
BA_ "U_V710_MY2023_Tx" SG_ 552 DSP_DSP_St 1;
BA_ "GenSigSendType" SG_ 552 DSP_Bass_St 3;
BA_ "U_V710_MY2023_Rx" SG_ 552 DSP_Bass_St 1;
BA_ "U_P708_MY2023_Rx" SG_ 552 DSP_Bass_St 1;
BA_ "U_P702_MY2024_Rx" SG_ 552 DSP_Bass_St 1;
BA_ "U_CDX74X_MY2024_Tx" SG_ 552 DSP_Bass_St 1;
BA_ "U_V710_MY2023_Tx" SG_ 552 DSP_Bass_St 1;
BA_ "GenSigSendType" SG_ 552 DSP_Balance_St 3;
BA_ "U_V710_MY2023_Rx" SG_ 552 DSP_Balance_St 1;
BA_ "U_P708_MY2023_Rx" SG_ 552 DSP_Balance_St 1;
BA_ "U_P702_MY2024_Rx" SG_ 552 DSP_Balance_St 1;
BA_ "U_CDX74X_MY2024_Tx" SG_ 552 DSP_Balance_St 1;
BA_ "U_V710_MY2023_Tx" SG_ 552 DSP_Balance_St 1;
BA_ "GenSigSendType" SG_ 552 DSP_AVC_St 3;
BA_ "U_V710_MY2023_Rx" SG_ 552 DSP_AVC_St 1;
BA_ "U_P708_MY2023_Rx" SG_ 552 DSP_AVC_St 1;
BA_ "U_P702_MY2024_Rx" SG_ 552 DSP_AVC_St 1;
BA_ "U_CDX74X_MY2024_Tx" SG_ 552 DSP_AVC_St 1;
BA_ "U_V710_MY2023_Tx" SG_ 552 DSP_AVC_St 1;
BA_ "GenSigSendType" SG_ 552 Audio_Demo_Status 3;
BA_ "U_V710_MY2023_Rx" SG_ 552 Audio_Demo_Status 1;
BA_ "U_P708_MY2023_Rx" SG_ 552 Audio_Demo_Status 1;
BA_ "U_P702_MY2024_Rx" SG_ 552 Audio_Demo_Status 1;
BA_ "U_V710_MY2023_Tx" SG_ 552 Audio_Demo_Status 1;
BA_ "U_P708_MY2023_Rx" SG_ 967 NfcMyKeyCreate_D_Stat 1;
BA_ "U_P708_MY2023_Rx" SG_ 967 KeyMyKeysTot_No_Actl 1;
BA_ "U_P708_MY2023_Rx" SG_ 967 AdminMyKeyTot_No_Actl 1;
BA_ "U_V710_MY2023_Rx" SG_ 967 CamZoomActiveState 1;
BA_ "U_P708_MY2023_Rx" SG_ 967 CamZoomActiveState 1;
BA_ "U_P702_MY2024_Rx" SG_ 967 CamZoomActiveState 1;
BA_ "GenSigStartValue" SG_ 967 CamraViewSplit_D_Actl 2;
BA_ "U_V710_MY2023_Rx" SG_ 967 CamraViewSplit_D_Actl 1;
BA_ "U_P708_MY2023_Rx" SG_ 967 CamraViewSplit_D_Actl 1;
BA_ "U_P702_MY2024_Rx" SG_ 967 CamraViewSplit_D_Actl 1;
BA_ "U_V710_MY2023_Rx" SG_ 967 CamraOvrlTow_D_Actl 1;
BA_ "U_P708_MY2023_Rx" SG_ 967 CamraOvrlTow_D_Actl 1;
BA_ "U_P702_MY2024_Rx" SG_ 967 CamraOvrlTow_D_Actl 1;
BA_ "U_V710_MY2023_Rx" SG_ 967 CamraZoomMan_D_Actl 1;
BA_ "U_P708_MY2023_Rx" SG_ 967 CamraZoomMan_D_Actl 1;
BA_ "U_P702_MY2024_Rx" SG_ 967 CamraZoomMan_D_Actl 1;
BA_ "U_V710_MY2023_Rx" SG_ 967 CamraOvrlStat_D_Actl 1;
BA_ "U_P708_MY2023_Rx" SG_ 967 CamraOvrlStat_D_Actl 1;
BA_ "U_P702_MY2024_Rx" SG_ 967 CamraOvrlStat_D_Actl 1;
BA_ "U_V710_MY2023_Rx" SG_ 967 CamraOvrlDyn_D_Actl 1;
BA_ "U_P708_MY2023_Rx" SG_ 967 CamraOvrlDyn_D_Actl 1;
BA_ "U_P702_MY2024_Rx" SG_ 967 CamraOvrlDyn_D_Actl 1;
BA_ "U_V710_MY2023_Rx" SG_ 967 CamPDCGuidStat 1;
BA_ "U_P708_MY2023_Rx" SG_ 967 CamPDCGuidStat 1;
BA_ "U_P702_MY2024_Rx" SG_ 967 CamPDCGuidStat 1;
BA_ "U_P708_MY2023_Rx" SG_ 1105 ClrExitAsstActv_B_Rq 1;
BA_ "U_V710_MY2023_Rx" SG_ 1105 ClrExitAsstActv_B_Rq 1;
BA_ "U_P702_MY2024_Rx" SG_ 1105 ClrExitAsstActv_B_Rq 1;
BA_ "U_P708_MY2023_Rx" SG_ 1105 ClrExitAsstMsgTxt2_D_Rq 1;
BA_ "U_V710_MY2023_Rx" SG_ 1105 ClrExitAsstMsgTxt2_D_Rq 1;
BA_ "U_P702_MY2024_Rx" SG_ 1105 ClrExitAsstMsgTxt2_D_Rq 1;
BA_ "U_V713N_MY2022_Rx" SG_ 1105 TrlrRvrseEnbl_D2_Stat 1;
BA_ "U_V713AV_MY2022_Rx" SG_ 1105 TrlrRvrseEnbl_D2_Stat 1;
BA_ "U_P708_MY2023_Rx" SG_ 1105 TrlrRvrseEnbl_D2_Stat 1;
BA_ "U_V710_MY2023_Rx" SG_ 1105 TrlrRvrseEnbl_D2_Stat 1;
BA_ "U_P702_MY2024_Rx" SG_ 1105 TrlrRvrseEnbl_D2_Stat 1;
BA_ "U_P708_MY2023_Rx" SG_ 1105 TrlrAidSwtchLamp_B_Rq 1;
BA_ "U_P702_MY2024_Rx" SG_ 1105 TrlrAidSwtchLamp_B_Rq 1;
BA_ "U_V710_MY2023_Rx" SG_ 1105 TrlrHitchMsgTxt_D_Rq 1;
BA_ "U_P708_MY2023_Rx" SG_ 1105 TrlrHitchMsgTxt_D_Rq 1;
BA_ "U_P702_MY2024_Rx" SG_ 1105 TrlrHitchMsgTxt_D_Rq 1;
BA_ "U_V710_MY2023_Rx" SG_ 1105 TrlrHitchIcon_D_Rq 1;
BA_ "U_P708_MY2023_Rx" SG_ 1105 TrlrHitchIcon_D_Rq 1;
BA_ "U_P702_MY2024_Rx" SG_ 1105 TrlrHitchIcon_D_Rq 1;
BA_ "U_V710_MY2023_Rx" SG_ 1105 CamraFrntOffRd_B_Stat 1;
BA_ "U_P708_MY2023_Rx" SG_ 1105 CamraFrntOffRd_B_Stat 1;
BA_ "U_P702_MY2024_Rx" SG_ 1105 CamraFrntOffRd_B_Stat 1;
BA_ "U_V713N_MY2022_Rx" SG_ 1105 TrlrHitchChime_D_Rq 1;
BA_ "U_V713AV_MY2022_Rx" SG_ 1105 TrlrHitchChime_D_Rq 1;
BA_ "U_P708_MY2023_Rx" SG_ 1105 TrlrHitchChime_D_Rq 1;
BA_ "U_V710_MY2023_Rx" SG_ 1105 TrlrHitchChime_D_Rq 1;
BA_ "U_P702_MY2024_Rx" SG_ 1105 TrlrHitchChime_D_Rq 1;
BA_ "U_V713N_MY2022_Rx" SG_ 1105 TrlrRvrseMsgTxt_D2_Rq 1;
BA_ "U_V713AV_MY2022_Rx" SG_ 1105 TrlrRvrseMsgTxt_D2_Rq 1;
BA_ "U_P708_MY2023_Rx" SG_ 1105 TrlrRvrseMsgTxt_D2_Rq 1;
BA_ "U_V710_MY2023_Rx" SG_ 1105 TrlrRvrseMsgTxt_D2_Rq 1;
BA_ "U_P702_MY2024_Rx" SG_ 1105 TrlrRvrseMsgTxt_D2_Rq 1;
BA_ "U_V713N_MY2022_Rx" SG_ 1105 RbaMsg_D_Rq 1;
BA_ "U_V713AV_MY2022_Rx" SG_ 1105 RbaMsg_D_Rq 1;
BA_ "U_P708_MY2023_Rx" SG_ 1105 RbaMsg_D_Rq 1;
BA_ "U_V710_MY2023_Rx" SG_ 1105 RbaMsg_D_Rq 1;
BA_ "U_P702_MY2024_Rx" SG_ 1105 RbaMsg_D_Rq 1;
BA_ "WakeupSignal" SG_ 1105 BrkDecel_B_RqRba 1;
BA_ "WakeupSignal" SG_ 1105 BrkEnbl_B_RqRba 1;
BA_ "GenSigStartValue" SG_ 1105 Rba_D_Stat 1;
BA_ "U_V713N_MY2022_Rx" SG_ 1105 Rba_D_Stat 1;
BA_ "U_V713AV_MY2022_Rx" SG_ 1105 Rba_D_Stat 1;
BA_ "U_P708_MY2023_Rx" SG_ 1105 Rba_D_Stat 1;
BA_ "U_V710_MY2023_Rx" SG_ 1105 Rba_D_Stat 1;
BA_ "U_P702_MY2024_Rx" SG_ 1105 Rba_D_Stat 1;
BA_ "U_V713N_MY2022_Rx" SG_ 1105 RbaAlrt_D_Dsply 1;
BA_ "U_V713AV_MY2022_Rx" SG_ 1105 RbaAlrt_D_Dsply 1;
BA_ "U_P708_MY2023_Rx" SG_ 1105 RbaAlrt_D_Dsply 1;
BA_ "U_V710_MY2023_Rx" SG_ 1105 RbaAlrt_D_Dsply 1;
BA_ "U_P702_MY2024_Rx" SG_ 1105 RbaAlrt_D_Dsply 1;
BA_ "U_V710_MY2023_Rx" SG_ 1105 RbaMnu_D_Rq 1;
BA_ "U_P708_MY2023_Rx" SG_ 1105 RbaMnu_D_Rq 1;
BA_ "U_P702_MY2024_Rx" SG_ 1105 RbaMnu_D_Rq 1;
BA_ "U_V713N_MY2022_Rx" SG_ 1105 CamraFrntStat_D_Stat 1;
BA_ "U_V713AV_MY2022_Rx" SG_ 1105 CamraFrntStat_D_Stat 1;
BA_ "U_P708_MY2023_Rx" SG_ 1105 CamraFrntStat_D_Stat 1;
BA_ "U_V710_MY2023_Rx" SG_ 1105 CamraFrntStat_D_Stat 1;
BA_ "U_P702_MY2024_Rx" SG_ 1105 CamraFrntStat_D_Stat 1;
BA_ "GenSigSendType" SG_ 867 LHS_Temp_Disp_Digit3 1;
BA_ "U_P708_MY2023_Rx" SG_ 867 LHS_Temp_Disp_Digit3 1;
BA_ "U_P702_MY2024_Rx" SG_ 867 LHS_Temp_Disp_Digit3 1;
BA_ "U_P702_MY2024_Tx" SG_ 867 LHS_Temp_Disp_Digit3 1;
BA_ "GenSigSendType" SG_ 867 LHS_Temp_Disp_Digit2 1;
BA_ "U_P708_MY2023_Rx" SG_ 867 LHS_Temp_Disp_Digit2 1;
BA_ "U_P702_MY2024_Rx" SG_ 867 LHS_Temp_Disp_Digit2 1;
BA_ "U_P702_MY2024_Tx" SG_ 867 LHS_Temp_Disp_Digit2 1;
BA_ "GenSigSendType" SG_ 867 LHS_Temp_Disp_Digit1 1;
BA_ "U_P708_MY2023_Rx" SG_ 867 LHS_Temp_Disp_Digit1 1;
BA_ "U_P702_MY2024_Rx" SG_ 867 LHS_Temp_Disp_Digit1 1;
BA_ "U_P702_MY2024_Tx" SG_ 867 LHS_Temp_Disp_Digit1 1;
BA_ "GenSigStartValue" SG_ 867 Front_Blower_Ind 15;
BA_ "GenSigSendType" SG_ 867 Front_Blower_Ind 1;
BA_ "U_V713N_MY2022_Tx" SG_ 867 Front_Blower_Ind 1;
BA_ "U_V713AV_MY2022_Tx" SG_ 867 Front_Blower_Ind 1;
BA_ "U_P702_MY2024_Tx" SG_ 867 Front_Blower_Ind 1;
BA_ "GenSigSendType" SG_ 867 EATC_LHS_Unit 1;
BA_ "U_P708_MY2023_Rx" SG_ 867 EATC_LHS_Unit 1;
BA_ "U_P702_MY2024_Rx" SG_ 867 EATC_LHS_Unit 1;
BA_ "U_P702_MY2024_Tx" SG_ 867 EATC_LHS_Unit 1;
BA_ "GenSigSendType" SG_ 866 CabnScentFanCalib_No_Rq 3;
BA_ "U_P702_MY2024_Tx" SG_ 866 CabnScentFanCalib_No_Rq 1;
BA_ "GenSigSendType" SG_ 866 CabnScentIntns_D_Rq 3;
BA_ "U_P702_MY2024_Tx" SG_ 866 CabnScentIntns_D_Rq 1;
BA_ "GenSigSendType" SG_ 866 CabnScentChnl_D_Rq 3;
BA_ "U_P702_MY2024_Tx" SG_ 866 CabnScentChnl_D_Rq 1;
BA_ "GenSigSendType" SG_ 866 CabnScentMde_D_Rq 3;
BA_ "U_P702_MY2024_Tx" SG_ 866 CabnScentMde_D_Rq 1;
BA_ "GenSigSendType" SG_ 866 SnowPlowOn_B_Rq 3;
BA_ "U_V710_MY2023_Tx" SG_ 866 SnowPlowOn_B_Rq 1;
BA_ "U_P708_MY2023_Tx" SG_ 866 SnowPlowOn_B_Rq 1;
BA_ "U_P702_MY2024_Tx" SG_ 866 SnowPlowOn_B_Rq 1;
BA_ "GenSigSendType" SG_ 866 Frt_Blower_Speed2 3;
BA_ "U_CDX74X_MY2024_Rx" SG_ 866 Frt_Blower_Speed2 1;
BA_ "U_V710_MY2023_Tx" SG_ 866 Frt_Blower_Speed2 1;
BA_ "U_P708_MY2023_Tx" SG_ 866 Frt_Blower_Speed2 1;
BA_ "U_P702_MY2024_Tx" SG_ 866 Frt_Blower_Speed2 1;
BA_ "GenSigSendType" SG_ 866 Psngr_Set_Temp 3;
BA_ "U_CDX74X_MY2024_Rx" SG_ 866 Psngr_Set_Temp 1;
BA_ "U_V710_MY2023_Tx" SG_ 866 Psngr_Set_Temp 1;
BA_ "U_P708_MY2023_Tx" SG_ 866 Psngr_Set_Temp 1;
BA_ "U_P702_MY2024_Tx" SG_ 866 Psngr_Set_Temp 1;
BA_ "GenSigSendType" SG_ 866 ClimtRearView_D_Stat 3;
BA_ "U_CDX74X_MY2024_Rx" SG_ 866 ClimtRearView_D_Stat 1;
BA_ "U_V710_MY2023_Tx" SG_ 866 ClimtRearView_D_Stat 1;
BA_ "U_P708_MY2023_Tx" SG_ 866 ClimtRearView_D_Stat 1;
BA_ "U_P702_MY2024_Tx" SG_ 866 ClimtRearView_D_Stat 1;
BA_ "GenSigSendType" SG_ 866 Voice_Blower_Limit 3;
BA_ "U_V710_MY2023_Tx" SG_ 866 Voice_Blower_Limit 1;
BA_ "U_P708_MY2023_Tx" SG_ 866 Voice_Blower_Limit 1;
BA_ "U_P702_MY2024_Tx" SG_ 866 Voice_Blower_Limit 1;
BA_ "GenSigSendType" SG_ 866 Rr_Btn_Status_2nd 3;
BA_ "U_CDX74X_MY2024_Rx" SG_ 866 Rr_Btn_Status_2nd 1;
BA_ "U_V710_MY2023_Tx" SG_ 866 Rr_Btn_Status_2nd 1;
BA_ "U_P708_MY2023_Tx" SG_ 866 Rr_Btn_Status_2nd 1;
BA_ "U_P702_MY2024_Tx" SG_ 866 Rr_Btn_Status_2nd 1;
BA_ "GenSigSendType" SG_ 866 Rr_Btn_Status_1st 3;
BA_ "U_CDX74X_MY2024_Rx" SG_ 866 Rr_Btn_Status_1st 1;
BA_ "U_V710_MY2023_Tx" SG_ 866 Rr_Btn_Status_1st 1;
BA_ "U_P708_MY2023_Tx" SG_ 866 Rr_Btn_Status_1st 1;
BA_ "U_P702_MY2024_Tx" SG_ 866 Rr_Btn_Status_1st 1;
BA_ "GenSigSendType" SG_ 866 Frt_Btn_Status_2nd 3;
BA_ "U_CDX74X_MY2024_Rx" SG_ 866 Frt_Btn_Status_2nd 1;
BA_ "U_V710_MY2023_Tx" SG_ 866 Frt_Btn_Status_2nd 1;
BA_ "U_P708_MY2023_Tx" SG_ 866 Frt_Btn_Status_2nd 1;
BA_ "U_P702_MY2024_Tx" SG_ 866 Frt_Btn_Status_2nd 1;
BA_ "GenSigSendType" SG_ 866 Frt_Btn_Status_1st 3;
BA_ "U_CDX74X_MY2024_Rx" SG_ 866 Frt_Btn_Status_1st 1;
BA_ "U_V710_MY2023_Tx" SG_ 866 Frt_Btn_Status_1st 1;
BA_ "U_P708_MY2023_Tx" SG_ 866 Frt_Btn_Status_1st 1;
BA_ "U_P702_MY2024_Tx" SG_ 866 Frt_Btn_Status_1st 1;
BA_ "GenSigSendType" SG_ 866 Frt_Blower_Speed 3;
BA_ "U_CDX74X_MY2024_Rx" SG_ 866 Frt_Blower_Speed 1;
BA_ "U_V710_MY2023_Tx" SG_ 866 Frt_Blower_Speed 1;
BA_ "U_P708_MY2023_Tx" SG_ 866 Frt_Blower_Speed 1;
BA_ "U_P702_MY2024_Tx" SG_ 866 Frt_Blower_Speed 1;
BA_ "GenSigSendType" SG_ 866 Drv_Set_Temp 3;
BA_ "U_CDX74X_MY2024_Rx" SG_ 866 Drv_Set_Temp 1;
BA_ "U_V710_MY2023_Tx" SG_ 866 Drv_Set_Temp 1;
BA_ "U_P708_MY2023_Tx" SG_ 866 Drv_Set_Temp 1;
BA_ "U_P702_MY2024_Tx" SG_ 866 Drv_Set_Temp 1;
BA_ "U_CDX74X_MY2024_Rx" SG_ 861 Rr_Temp_Detents 1;
BA_ "U_V710_MY2023_Rx" SG_ 861 Rr_Temp_Detents 1;
BA_ "U_P708_MY2023_Rx" SG_ 861 Rr_Temp_Detents 1;
BA_ "U_P702_MY2024_Rx" SG_ 861 Rr_Temp_Detents 1;
BA_ "GenSigStartValue" SG_ 861 Rr_Power_Btn_Stt 2;
BA_ "U_CDX74X_MY2024_Rx" SG_ 861 Rr_Power_Btn_Stt 1;
BA_ "U_V710_MY2023_Rx" SG_ 861 Rr_Power_Btn_Stt 1;
BA_ "U_P708_MY2023_Rx" SG_ 861 Rr_Power_Btn_Stt 1;
BA_ "U_P702_MY2024_Rx" SG_ 861 Rr_Power_Btn_Stt 1;
BA_ "U_CDX74X_MY2024_Rx" SG_ 861 Rr_RH_Cond_Seat_Stat 1;
BA_ "U_V710_MY2023_Rx" SG_ 861 Rr_RH_Cond_Seat_Stat 1;
BA_ "U_P708_MY2023_Rx" SG_ 861 Rr_RH_Cond_Seat_Stat 1;
BA_ "U_P702_MY2024_Rx" SG_ 861 Rr_RH_Cond_Seat_Stat 1;
BA_ "GenSigStartValue" SG_ 861 Rr_Pnl_Flr_Btn_Stt 2;
BA_ "U_CDX74X_MY2024_Rx" SG_ 861 Rr_Pnl_Flr_Btn_Stt 1;
BA_ "U_V710_MY2023_Rx" SG_ 861 Rr_Pnl_Flr_Btn_Stt 1;
BA_ "U_P708_MY2023_Rx" SG_ 861 Rr_Pnl_Flr_Btn_Stt 1;
BA_ "U_P702_MY2024_Rx" SG_ 861 Rr_Pnl_Flr_Btn_Stt 1;
BA_ "U_CDX74X_MY2024_Rx" SG_ 861 Rr_LH_Cond_Seat_Stat 1;
BA_ "U_V710_MY2023_Rx" SG_ 861 Rr_LH_Cond_Seat_Stat 1;
BA_ "U_P708_MY2023_Rx" SG_ 861 Rr_LH_Cond_Seat_Stat 1;
BA_ "U_P702_MY2024_Rx" SG_ 861 Rr_LH_Cond_Seat_Stat 1;
BA_ "U_CDX74X_MY2024_Rx" SG_ 861 CC_Rr_Stat_User_Adj 1;
BA_ "U_V710_MY2023_Rx" SG_ 861 CC_Rr_Stat_User_Adj 1;
BA_ "U_P708_MY2023_Rx" SG_ 861 CC_Rr_Stat_User_Adj 1;
BA_ "U_P702_MY2024_Rx" SG_ 861 CC_Rr_Stat_User_Adj 1;
BA_ "GenSigStartValue" SG_ 861 Rr_Set_Temp_Units 2;
BA_ "U_CDX74X_MY2024_Rx" SG_ 861 Rr_Set_Temp_Units 1;
BA_ "U_V710_MY2023_Rx" SG_ 861 Rr_Set_Temp_Units 1;
BA_ "U_P708_MY2023_Rx" SG_ 861 Rr_Set_Temp_Units 1;
BA_ "U_P702_MY2024_Rx" SG_ 861 Rr_Set_Temp_Units 1;
BA_ "GenSigStartValue" SG_ 861 Rr_RHS_Set_Temp_Dig3 2;
BA_ "U_CDX74X_MY2024_Rx" SG_ 861 Rr_RHS_Set_Temp_Dig3 1;
BA_ "U_V710_MY2023_Rx" SG_ 861 Rr_RHS_Set_Temp_Dig3 1;
BA_ "U_P708_MY2023_Rx" SG_ 861 Rr_RHS_Set_Temp_Dig3 1;
BA_ "U_P702_MY2024_Rx" SG_ 861 Rr_RHS_Set_Temp_Dig3 1;
BA_ "GenSigStartValue" SG_ 861 Rr_RHS_Set_Temp_Dig2 15;
BA_ "U_CDX74X_MY2024_Rx" SG_ 861 Rr_RHS_Set_Temp_Dig2 1;
BA_ "U_V710_MY2023_Rx" SG_ 861 Rr_RHS_Set_Temp_Dig2 1;
BA_ "U_P708_MY2023_Rx" SG_ 861 Rr_RHS_Set_Temp_Dig2 1;
BA_ "U_P702_MY2024_Rx" SG_ 861 Rr_RHS_Set_Temp_Dig2 1;
BA_ "GenSigStartValue" SG_ 861 Rr_RHS_Set_Temp_Dig1 15;
BA_ "U_CDX74X_MY2024_Rx" SG_ 861 Rr_RHS_Set_Temp_Dig1 1;
BA_ "U_V710_MY2023_Rx" SG_ 861 Rr_RHS_Set_Temp_Dig1 1;
BA_ "U_P708_MY2023_Rx" SG_ 861 Rr_RHS_Set_Temp_Dig1 1;
BA_ "U_P702_MY2024_Rx" SG_ 861 Rr_RHS_Set_Temp_Dig1 1;
BA_ "GenSigStartValue" SG_ 861 Rr_RH_Htd_Seat_Btn_Stt 2;
BA_ "U_CDX74X_MY2024_Rx" SG_ 861 Rr_RH_Htd_Seat_Btn_Stt 1;
BA_ "U_V710_MY2023_Rx" SG_ 861 Rr_RH_Htd_Seat_Btn_Stt 1;
BA_ "U_P708_MY2023_Rx" SG_ 861 Rr_RH_Htd_Seat_Btn_Stt 1;
BA_ "U_P702_MY2024_Rx" SG_ 861 Rr_RH_Htd_Seat_Btn_Stt 1;
BA_ "GenSigStartValue" SG_ 861 Rr_RH_Cld_Seat_Btn_Stt 2;
BA_ "U_CDX74X_MY2024_Rx" SG_ 861 Rr_RH_Cld_Seat_Btn_Stt 1;
BA_ "U_V710_MY2023_Rx" SG_ 861 Rr_RH_Cld_Seat_Btn_Stt 1;
BA_ "U_P708_MY2023_Rx" SG_ 861 Rr_RH_Cld_Seat_Btn_Stt 1;
BA_ "U_P702_MY2024_Rx" SG_ 861 Rr_RH_Cld_Seat_Btn_Stt 1;
BA_ "GenSigStartValue" SG_ 861 Rr_Panel_Btn_Stt 2;
BA_ "U_CDX74X_MY2024_Rx" SG_ 861 Rr_Panel_Btn_Stt 1;
BA_ "U_V710_MY2023_Rx" SG_ 861 Rr_Panel_Btn_Stt 1;
BA_ "U_P708_MY2023_Rx" SG_ 861 Rr_Panel_Btn_Stt 1;
BA_ "U_P702_MY2024_Rx" SG_ 861 Rr_Panel_Btn_Stt 1;
BA_ "U_CDX74X_MY2024_Rx" SG_ 861 Rr_On_Indicator 1;
BA_ "U_V710_MY2023_Rx" SG_ 861 Rr_On_Indicator 1;
BA_ "U_P708_MY2023_Rx" SG_ 861 Rr_On_Indicator 1;
BA_ "U_P702_MY2024_Rx" SG_ 861 Rr_On_Indicator 1;
BA_ "U_CDX74X_MY2024_Rx" SG_ 861 Rr_LHS_Set_Temp_Dig3 1;
BA_ "U_V710_MY2023_Rx" SG_ 861 Rr_LHS_Set_Temp_Dig3 1;
BA_ "U_P708_MY2023_Rx" SG_ 861 Rr_LHS_Set_Temp_Dig3 1;
BA_ "U_P702_MY2024_Rx" SG_ 861 Rr_LHS_Set_Temp_Dig3 1;
BA_ "GenSigStartValue" SG_ 861 Rr_LHS_Set_Temp_Dig2 15;
BA_ "U_CDX74X_MY2024_Rx" SG_ 861 Rr_LHS_Set_Temp_Dig2 1;
BA_ "U_V710_MY2023_Rx" SG_ 861 Rr_LHS_Set_Temp_Dig2 1;
BA_ "U_P708_MY2023_Rx" SG_ 861 Rr_LHS_Set_Temp_Dig2 1;
BA_ "U_P702_MY2024_Rx" SG_ 861 Rr_LHS_Set_Temp_Dig2 1;
BA_ "GenSigStartValue" SG_ 861 Rr_LHS_Set_Temp_Dig1 15;
BA_ "U_CDX74X_MY2024_Rx" SG_ 861 Rr_LHS_Set_Temp_Dig1 1;
BA_ "U_V710_MY2023_Rx" SG_ 861 Rr_LHS_Set_Temp_Dig1 1;
BA_ "U_P708_MY2023_Rx" SG_ 861 Rr_LHS_Set_Temp_Dig1 1;
BA_ "U_P702_MY2024_Rx" SG_ 861 Rr_LHS_Set_Temp_Dig1 1;
BA_ "GenSigStartValue" SG_ 861 Rr_LH_Htd_Seat_Btn_Stt 2;
BA_ "U_CDX74X_MY2024_Rx" SG_ 861 Rr_LH_Htd_Seat_Btn_Stt 1;
BA_ "U_V710_MY2023_Rx" SG_ 861 Rr_LH_Htd_Seat_Btn_Stt 1;
BA_ "U_P708_MY2023_Rx" SG_ 861 Rr_LH_Htd_Seat_Btn_Stt 1;
BA_ "U_P702_MY2024_Rx" SG_ 861 Rr_LH_Htd_Seat_Btn_Stt 1;
BA_ "GenSigStartValue" SG_ 861 Rr_LH_Cld_Seat_Btn_Stt 2;
BA_ "U_CDX74X_MY2024_Rx" SG_ 861 Rr_LH_Cld_Seat_Btn_Stt 1;
BA_ "U_V710_MY2023_Rx" SG_ 861 Rr_LH_Cld_Seat_Btn_Stt 1;
BA_ "U_P708_MY2023_Rx" SG_ 861 Rr_LH_Cld_Seat_Btn_Stt 1;
BA_ "U_P702_MY2024_Rx" SG_ 861 Rr_LH_Cld_Seat_Btn_Stt 1;
BA_ "GenSigStartValue" SG_ 861 Rr_Floor_Btn_Stt 2;
BA_ "U_CDX74X_MY2024_Rx" SG_ 861 Rr_Floor_Btn_Stt 1;
BA_ "U_V710_MY2023_Rx" SG_ 861 Rr_Floor_Btn_Stt 1;
BA_ "U_P708_MY2023_Rx" SG_ 861 Rr_Floor_Btn_Stt 1;
BA_ "U_P702_MY2024_Rx" SG_ 861 Rr_Floor_Btn_Stt 1;
BA_ "GenSigStartValue" SG_ 861 Rr_Control_Btn_Stt 2;
BA_ "U_CDX74X_MY2024_Rx" SG_ 861 Rr_Control_Btn_Stt 1;
BA_ "U_V710_MY2023_Rx" SG_ 861 Rr_Control_Btn_Stt 1;
BA_ "U_P708_MY2023_Rx" SG_ 861 Rr_Control_Btn_Stt 1;
BA_ "U_P702_MY2024_Rx" SG_ 861 Rr_Control_Btn_Stt 1;
BA_ "GenSigStartValue" SG_ 861 Rr_Blower_Indicate 15;
BA_ "U_CDX74X_MY2024_Rx" SG_ 861 Rr_Blower_Indicate 1;
BA_ "U_V710_MY2023_Rx" SG_ 861 Rr_Blower_Indicate 1;
BA_ "U_P708_MY2023_Rx" SG_ 861 Rr_Blower_Indicate 1;
BA_ "U_P702_MY2024_Rx" SG_ 861 Rr_Blower_Indicate 1;
BA_ "GenSigStartValue" SG_ 861 Rr_AUTO_Btn_Stt 2;
BA_ "U_CDX74X_MY2024_Rx" SG_ 861 Rr_AUTO_Btn_Stt 1;
BA_ "U_V710_MY2023_Rx" SG_ 861 Rr_AUTO_Btn_Stt 1;
BA_ "U_P708_MY2023_Rx" SG_ 861 Rr_AUTO_Btn_Stt 1;
BA_ "U_P702_MY2024_Rx" SG_ 861 Rr_AUTO_Btn_Stt 1;
BA_ "GenSigStartValue" SG_ 865 Dsp_RotAddrBtnEv_St 7;
BA_ "U_V710_MY2023_Rx" SG_ 865 Dsp_RotAddrBtnEv_St 1;
BA_ "U_P708_MY2023_Rx" SG_ 865 Dsp_RotAddrBtnEv_St 1;
BA_ "U_P702_MY2024_Rx" SG_ 865 Dsp_RotAddrBtnEv_St 1;
BA_ "U_V713N_MY2022_Rx" SG_ 865 SteEffortButtn_B_Stat 1;
BA_ "U_V713AV_MY2022_Rx" SG_ 865 SteEffortButtn_B_Stat 1;
BA_ "U_P708_MY2023_Rx" SG_ 865 SteEffortButtn_B_Stat 1;
BA_ "U_V710_MY2023_Rx" SG_ 865 SteEffortButtn_B_Stat 1;
BA_ "U_P702_MY2024_Rx" SG_ 865 SteEffortButtn_B_Stat 1;
BA_ "U_V713N_MY2022_Rx" SG_ 865 EngExhMdeQuiet_B_RqDrv 1;
BA_ "U_V713AV_MY2022_Rx" SG_ 865 EngExhMdeQuiet_B_RqDrv 1;
BA_ "U_P708_MY2023_Rx" SG_ 865 EngExhMdeQuiet_B_RqDrv 1;
BA_ "U_V710_MY2023_Rx" SG_ 865 EngExhMdeQuiet_B_RqDrv 1;
BA_ "U_P702_MY2024_Rx" SG_ 865 EngExhMdeQuiet_B_RqDrv 1;
BA_ "U_V713N_MY2022_Rx" SG_ 865 LnchCtlSys_B_RqDrv 1;
BA_ "U_V713AV_MY2022_Rx" SG_ 865 LnchCtlSys_B_RqDrv 1;
BA_ "U_P708_MY2023_Rx" SG_ 865 LnchCtlSys_B_RqDrv 1;
BA_ "U_V710_MY2023_Rx" SG_ 865 LnchCtlSys_B_RqDrv 1;
BA_ "U_P702_MY2024_Rx" SG_ 865 LnchCtlSys_B_RqDrv 1;
BA_ "U_P708_MY2023_Rx" SG_ 865 CC_Fr_Stat_User_Adj 1;
BA_ "U_P702_MY2024_Rx" SG_ 865 CC_Fr_Stat_User_Adj 1;
BA_ "GenSigStartValue" SG_ 865 RHS_Auto_Seat_Btn_Stt 2;
BA_ "U_V710_MY2023_Rx" SG_ 865 RHS_Auto_Seat_Btn_Stt 1;
BA_ "U_P708_MY2023_Rx" SG_ 865 RHS_Auto_Seat_Btn_Stt 1;
BA_ "U_P702_MY2024_Rx" SG_ 865 RHS_Auto_Seat_Btn_Stt 1;
BA_ "GenSigStartValue" SG_ 865 Front_Blower_Indicate 15;
BA_ "U_V713N_MY2022_Rx" SG_ 865 Front_Blower_Indicate 1;
BA_ "U_P708_MY2023_Rx" SG_ 865 Front_Blower_Indicate 1;
BA_ "U_V710_MY2023_Rx" SG_ 865 Front_Blower_Indicate 1;
BA_ "U_P702_MY2024_Rx" SG_ 865 Front_Blower_Indicate 1;
BA_ "U_V713N_MY2022_Rx" SG_ 865 CC_Diagnostics_Active 1;
BA_ "U_V713AV_MY2022_Rx" SG_ 865 CC_Diagnostics_Active 1;
BA_ "U_V713N_MY2022_Rx" SG_ 865 RHS_Temp_Display_Digit3 1;
BA_ "U_V713AV_MY2022_Rx" SG_ 865 RHS_Temp_Display_Digit3 1;
BA_ "U_V710_MY2023_Rx" SG_ 865 RHS_Temp_Display_Digit3 1;
BA_ "U_P708_MY2023_Rx" SG_ 865 RHS_Temp_Display_Digit3 1;
BA_ "U_P702_MY2024_Rx" SG_ 865 RHS_Temp_Display_Digit3 1;
BA_ "U_V713N_MY2022_Rx" SG_ 865 RHS_Temp_Display_Digit2 1;
BA_ "U_V713AV_MY2022_Rx" SG_ 865 RHS_Temp_Display_Digit2 1;
BA_ "U_V710_MY2023_Rx" SG_ 865 RHS_Temp_Display_Digit2 1;
BA_ "U_P708_MY2023_Rx" SG_ 865 RHS_Temp_Display_Digit2 1;
BA_ "U_P702_MY2024_Rx" SG_ 865 RHS_Temp_Display_Digit2 1;
BA_ "U_V713N_MY2022_Rx" SG_ 865 RHS_Temp_Display_Digit1 1;
BA_ "U_V713AV_MY2022_Rx" SG_ 865 RHS_Temp_Display_Digit1 1;
BA_ "U_V710_MY2023_Rx" SG_ 865 RHS_Temp_Display_Digit1 1;
BA_ "U_P708_MY2023_Rx" SG_ 865 RHS_Temp_Display_Digit1 1;
BA_ "U_P702_MY2024_Rx" SG_ 865 RHS_Temp_Display_Digit1 1;
BA_ "U_V713N_MY2022_Rx" SG_ 865 LHS_Temp_Display_Digit3 1;
BA_ "U_V713AV_MY2022_Rx" SG_ 865 LHS_Temp_Display_Digit3 1;
BA_ "U_V710_MY2023_Rx" SG_ 865 LHS_Temp_Display_Digit3 1;
BA_ "U_P708_MY2023_Rx" SG_ 865 LHS_Temp_Display_Digit3 1;
BA_ "U_P702_MY2024_Rx" SG_ 865 LHS_Temp_Display_Digit3 1;
BA_ "U_V713N_MY2022_Rx" SG_ 865 LHS_Temp_Display_Digit2 1;
BA_ "U_V713AV_MY2022_Rx" SG_ 865 LHS_Temp_Display_Digit2 1;
BA_ "U_V710_MY2023_Rx" SG_ 865 LHS_Temp_Display_Digit2 1;
BA_ "U_P708_MY2023_Rx" SG_ 865 LHS_Temp_Display_Digit2 1;
BA_ "U_P702_MY2024_Rx" SG_ 865 LHS_Temp_Display_Digit2 1;
BA_ "U_V713N_MY2022_Rx" SG_ 865 LHS_Temp_Display_Digit1 1;
BA_ "U_V713AV_MY2022_Rx" SG_ 865 LHS_Temp_Display_Digit1 1;
BA_ "U_V710_MY2023_Rx" SG_ 865 LHS_Temp_Display_Digit1 1;
BA_ "U_P708_MY2023_Rx" SG_ 865 LHS_Temp_Display_Digit1 1;
BA_ "U_P702_MY2024_Rx" SG_ 865 LHS_Temp_Display_Digit1 1;
BA_ "U_V713N_MY2022_Rx" SG_ 865 EATC_RHS_Units 1;
BA_ "U_V713AV_MY2022_Rx" SG_ 865 EATC_RHS_Units 1;
BA_ "U_V710_MY2023_Rx" SG_ 865 EATC_RHS_Units 1;
BA_ "U_P708_MY2023_Rx" SG_ 865 EATC_RHS_Units 1;
BA_ "U_P702_MY2024_Rx" SG_ 865 EATC_RHS_Units 1;
BA_ "U_V713N_MY2022_Rx" SG_ 865 EATC_LHS_Units 1;
BA_ "U_V713AV_MY2022_Rx" SG_ 865 EATC_LHS_Units 1;
BA_ "U_V710_MY2023_Rx" SG_ 865 EATC_LHS_Units 1;
BA_ "U_P708_MY2023_Rx" SG_ 865 EATC_LHS_Units 1;
BA_ "U_P702_MY2024_Rx" SG_ 865 EATC_LHS_Units 1;
BA_ "GenSigStartValue" SG_ 865 LHS_Auto_Seat_Btn_Stt 2;
BA_ "U_V710_MY2023_Rx" SG_ 865 LHS_Auto_Seat_Btn_Stt 1;
BA_ "U_P708_MY2023_Rx" SG_ 865 LHS_Auto_Seat_Btn_Stt 1;
BA_ "U_P702_MY2024_Rx" SG_ 865 LHS_Auto_Seat_Btn_Stt 1;
BA_ "U_V713N_MY2022_Rx" SG_ 1046 PrkBrkDynmc_D_Allw 1;
BA_ "U_V713AV_MY2022_Rx" SG_ 1046 PrkBrkDynmc_D_Allw 1;
BA_ "U_V713N_MY2022_Rx" SG_ 1046 BrkPrkBrkDynmc_B_Actl 1;
BA_ "U_V713AV_MY2022_Rx" SG_ 1046 BrkPrkBrkDynmc_B_Actl 1;
BA_ "U_V713N_MY2022_Rx" SG_ 1046 TRLR_SWAY_EVNT_IN_PROG 1;
BA_ "U_V713AV_MY2022_Rx" SG_ 1046 TRLR_SWAY_EVNT_IN_PROG 1;
BA_ "U_P708_MY2023_Rx" SG_ 1046 TRLR_SWAY_EVNT_IN_PROG 1;
BA_ "U_V710_MY2023_Rx" SG_ 1046 TRLR_SWAY_EVNT_IN_PROG 1;
BA_ "U_P702_MY2024_Rx" SG_ 1046 TRLR_SWAY_EVNT_IN_PROG 1;
BA_ "U_V713N_MY2022_Rx" SG_ 1046 TRLR_SWAY_CONFIG_STAT 1;
BA_ "U_V713AV_MY2022_Rx" SG_ 1046 TRLR_SWAY_CONFIG_STAT 1;
BA_ "U_P708_MY2023_Rx" SG_ 1046 TRLR_SWAY_CONFIG_STAT 1;
BA_ "U_V710_MY2023_Rx" SG_ 1046 TRLR_SWAY_CONFIG_STAT 1;
BA_ "U_P702_MY2024_Rx" SG_ 1046 TRLR_SWAY_CONFIG_STAT 1;
BA_ "GenSigStartValue" SG_ 1046 HsaMde_D_Mem 1;
BA_ "U_V713N_MY2022_Rx" SG_ 1046 HsaMde_D_Mem 1;
BA_ "U_P708_MY2023_Rx" SG_ 1046 HsaMde_D_Mem 1;
BA_ "U_V710_MY2023_Rx" SG_ 1046 HsaMde_D_Mem 1;
BA_ "U_P702_MY2024_Rx" SG_ 1046 HsaMde_D_Mem 1;
BA_ "MetaData" SG_ 1046 BpedDiffLckTq_No_Cs 1;
BA_ "U_V713N_MY2022_Rx" SG_ 1046 DrvSlipCtlMde_D_Ind 1;
BA_ "U_V713AV_MY2022_Rx" SG_ 1046 DrvSlipCtlMde_D_Ind 1;
BA_ "U_P708_MY2023_Rx" SG_ 1046 DrvSlipCtlMde_D_Ind 1;
BA_ "U_V710_MY2023_Rx" SG_ 1046 DrvSlipCtlMde_D_Ind 1;
BA_ "U_P702_MY2024_Rx" SG_ 1046 DrvSlipCtlMde_D_Ind 1;
BA_ "U_V713N_MY2022_Rx" SG_ 1046 DrvSlipCtlLamp_D_Rq 1;
BA_ "U_P708_MY2023_Rx" SG_ 1046 DrvSlipCtlLamp_D_Rq 1;
BA_ "U_V710_MY2023_Rx" SG_ 1046 DrvSlipCtlLamp_D_Rq 1;
BA_ "U_P702_MY2024_Rx" SG_ 1046 DrvSlipCtlLamp_D_Rq 1;
BA_ "U_V713N_MY2022_Rx" SG_ 1046 TCMode 1;
BA_ "U_V713AV_MY2022_Rx" SG_ 1046 TCMode 1;
BA_ "U_V710_MY2023_Rx" SG_ 1046 TCMode 1;
BA_ "U_P708_MY2023_Rx" SG_ 1046 TCMode 1;
BA_ "U_P702_MY2024_Rx" SG_ 1046 TCMode 1;
BA_ "U_V713N_MY2022_Rx" SG_ 1046 HILL_DESC_MC 1;
BA_ "U_V713AV_MY2022_Rx" SG_ 1046 HILL_DESC_MC 1;
BA_ "U_P708_MY2023_Rx" SG_ 1046 HILL_DESC_MC 1;
BA_ "U_V710_MY2023_Rx" SG_ 1046 HILL_DESC_MC 1;
BA_ "U_P702_MY2024_Rx" SG_ 1046 HILL_DESC_MC 1;
BA_ "U_V713N_MY2022_Rx" SG_ 1046 DrvAntiLckLamp_D_Rq 1;
BA_ "U_P708_MY2023_Rx" SG_ 1046 DrvAntiLckLamp_D_Rq 1;
BA_ "U_V710_MY2023_Rx" SG_ 1046 DrvAntiLckLamp_D_Rq 1;
BA_ "U_P702_MY2024_Rx" SG_ 1046 DrvAntiLckLamp_D_Rq 1;
BA_ "U_V713N_MY2022_Rx" SG_ 1046 ChimeBrk_B_Rq 1;
BA_ "U_V713AV_MY2022_Rx" SG_ 1046 ChimeBrk_B_Rq 1;
BA_ "U_P708_MY2023_Rx" SG_ 1046 ChimeBrk_B_Rq 1;
BA_ "U_V710_MY2023_Rx" SG_ 1046 ChimeBrk_B_Rq 1;
BA_ "U_P702_MY2024_Rx" SG_ 1046 ChimeBrk_B_Rq 1;
BA_ "U_V713N_MY2022_Rx" SG_ 1046 BrkLamp_B_Rq 1;
BA_ "U_V713AV_MY2022_Rx" SG_ 1046 BrkLamp_B_Rq 1;
BA_ "U_P708_MY2023_Rx" SG_ 1046 BrkLamp_B_Rq 1;
BA_ "U_V710_MY2023_Rx" SG_ 1046 BrkLamp_B_Rq 1;
BA_ "U_P702_MY2024_Rx" SG_ 1046 BrkLamp_B_Rq 1;
BA_ "U_V713N_MY2022_Rx" SG_ 1046 Abs_B_Falt 1;
BA_ "U_V713AV_MY2022_Rx" SG_ 1046 Abs_B_Falt 1;
BA_ "U_P708_MY2023_Rx" SG_ 1046 Abs_B_Falt 1;
BA_ "U_P702_MY2024_Rx" SG_ 1046 Abs_B_Falt 1;
BA_ "GenSigStartValue" SG_ 1046 StabCtlBrk_B_Avail 1;
BA_ "U_V713N_MY2022_Rx" SG_ 1046 StabCtlBrk_B_Avail 1;
BA_ "U_V713AV_MY2022_Rx" SG_ 1046 StabCtlBrk_B_Avail 1;
BA_ "U_V713N_MY2022_Rx" SG_ 1046 DrvHdcWarnInfo_D_Rq 1;
BA_ "U_V713AV_MY2022_Rx" SG_ 1046 DrvHdcWarnInfo_D_Rq 1;
BA_ "U_P702_MY2024_Rx" SG_ 1046 DrvHdcWarnInfo_D_Rq 1;
BA_ "U_V713N_MY2022_Rx" SG_ 1046 DrvHdcMsg_D_Rq 1;
BA_ "U_V713AV_MY2022_Rx" SG_ 1046 DrvHdcMsg_D_Rq 1;
BA_ "U_V713N_MY2022_Rx" SG_ 1046 DrvHdcLampInfo_D_Rq 1;
BA_ "U_V713AV_MY2022_Rx" SG_ 1046 DrvHdcLampInfo_D_Rq 1;
BA_ "U_P708_MY2023_Rx" SG_ 1046 DrvHdcLampInfo_D_Rq 1;
BA_ "U_V710_MY2023_Rx" SG_ 1046 DrvHdcLampInfo_D_Rq 1;
BA_ "U_P702_MY2024_Rx" SG_ 1046 DrvHdcLampInfo_D_Rq 1;
BA_ "MetaData" SG_ 1046 BpedMove_No_Cnt 1;
BA_ "GenSigStartValue" SG_ 1046 BpedMove_D_Actl 3;
BA_ "GenSigStartValue" SG_ 1046 RearDiffLck_Tq2_RqMx 4094;
BA_ "MetaData" SG_ 534 WhlRotatRr_No_Cnt 1;
BA_ "U_V710_MY2023_Rx" SG_ 534 WhlRotatRr_No_Cnt 1;
BA_ "U_P708_MY2023_Rx" SG_ 534 WhlRotatRr_No_Cnt 1;
BA_ "U_P702_MY2024_Rx" SG_ 534 WhlRotatRr_No_Cnt 1;
BA_ "U_V710_MY2023_Rx" SG_ 534 WhlDirRr_D_Actl 1;
BA_ "U_P708_MY2023_Rx" SG_ 534 WhlDirRr_D_Actl 1;
BA_ "U_P702_MY2024_Rx" SG_ 534 WhlDirRr_D_Actl 1;
BA_ "U_V710_MY2023_Rx" SG_ 534 WhlDirRl_D_Actl 1;
BA_ "U_P708_MY2023_Rx" SG_ 534 WhlDirRl_D_Actl 1;
BA_ "U_P702_MY2024_Rx" SG_ 534 WhlDirRl_D_Actl 1;
BA_ "U_V710_MY2023_Rx" SG_ 534 WhlDirFr_D_Actl 1;
BA_ "U_P708_MY2023_Rx" SG_ 534 WhlDirFr_D_Actl 1;
BA_ "U_P702_MY2024_Rx" SG_ 534 WhlDirFr_D_Actl 1;
BA_ "U_V710_MY2023_Rx" SG_ 534 WhlDirFl_D_Actl 1;
BA_ "U_P708_MY2023_Rx" SG_ 534 WhlDirFl_D_Actl 1;
BA_ "U_P702_MY2024_Rx" SG_ 534 WhlDirFl_D_Actl 1;
BA_ "MetaData" SG_ 534 WhlRotatRl_No_Cnt 1;
BA_ "U_V710_MY2023_Rx" SG_ 534 WhlRotatRl_No_Cnt 1;
BA_ "U_P708_MY2023_Rx" SG_ 534 WhlRotatRl_No_Cnt 1;
BA_ "U_P702_MY2024_Rx" SG_ 534 WhlRotatRl_No_Cnt 1;
BA_ "MetaData" SG_ 534 WhlRotatFr_No_Cnt 1;
BA_ "U_V710_MY2023_Rx" SG_ 534 WhlRotatFr_No_Cnt 1;
BA_ "U_P708_MY2023_Rx" SG_ 534 WhlRotatFr_No_Cnt 1;
BA_ "U_P702_MY2024_Rx" SG_ 534 WhlRotatFr_No_Cnt 1;
BA_ "MetaData" SG_ 534 WhlRotatFl_No_Cnt 1;
BA_ "U_V710_MY2023_Rx" SG_ 534 WhlRotatFl_No_Cnt 1;
BA_ "U_P708_MY2023_Rx" SG_ 534 WhlRotatFl_No_Cnt 1;
BA_ "U_P702_MY2024_Rx" SG_ 534 WhlRotatFl_No_Cnt 1;
BA_ "GenSigSendType" SG_ 402 CamraFrntBttn_D_Stat3 3;
BA_ "U_V713AV_MY2022_Tx" SG_ 402 CamraFrntBttn_D_Stat3 1;
BA_ "U_P708_MY2023_Tx" SG_ 402 CamraFrntBttn_D_Stat3 1;
BA_ "U_V710_MY2023_Tx" SG_ 402 CamraFrntBttn_D_Stat3 1;
BA_ "U_P702_MY2024_Tx" SG_ 402 CamraFrntBttn_D_Stat3 1;
BA_ "GenSigSendType" SG_ 402 PrkAidSwtch_D_RqMnu 3;
BA_ "U_V713AV_MY2022_Tx" SG_ 402 PrkAidSwtch_D_RqMnu 1;
BA_ "U_P708_MY2023_Tx" SG_ 402 PrkAidSwtch_D_RqMnu 1;
BA_ "U_V710_MY2023_Tx" SG_ 402 PrkAidSwtch_D_RqMnu 1;
BA_ "U_P702_MY2024_Tx" SG_ 402 PrkAidSwtch_D_RqMnu 1;
BA_ "GenSigSendType" SG_ 402 ApaSwtch_D_RqMnu 3;
BA_ "U_V713AV_MY2022_Tx" SG_ 402 ApaSwtch_D_RqMnu 1;
BA_ "U_P708_MY2023_Tx" SG_ 402 ApaSwtch_D_RqMnu 1;
BA_ "U_V710_MY2023_Tx" SG_ 402 ApaSwtch_D_RqMnu 1;
BA_ "U_P702_MY2024_Tx" SG_ 402 ApaSwtch_D_RqMnu 1;
BA_ "GenSigSendType" SG_ 402 ApaSlotAlrtSet_D_RqDrv 3;
BA_ "U_V713AV_MY2022_Tx" SG_ 402 ApaSlotAlrtSet_D_RqDrv 1;
BA_ "U_P708_MY2023_Tx" SG_ 402 ApaSlotAlrtSet_D_RqDrv 1;
BA_ "U_V710_MY2023_Tx" SG_ 402 ApaSlotAlrtSet_D_RqDrv 1;
BA_ "U_P702_MY2024_Tx" SG_ 402 ApaSlotAlrtSet_D_RqDrv 1;
BA_ "GenSigSendType" SG_ 402 ApaSlotTrgt_D_RqDrv 3;
BA_ "U_V713AV_MY2022_Tx" SG_ 402 ApaSlotTrgt_D_RqDrv 1;
BA_ "U_P708_MY2023_Tx" SG_ 402 ApaSlotTrgt_D_RqDrv 1;
BA_ "U_V710_MY2023_Tx" SG_ 402 ApaSlotTrgt_D_RqDrv 1;
BA_ "U_P702_MY2024_Tx" SG_ 402 ApaSlotTrgt_D_RqDrv 1;
BA_ "GenSigSendType" SG_ 402 ApaMdeStat_D_RqDrv 3;
BA_ "U_V713AV_MY2022_Tx" SG_ 402 ApaMdeStat_D_RqDrv 1;
BA_ "U_P708_MY2023_Tx" SG_ 402 ApaMdeStat_D_RqDrv 1;
BA_ "U_V710_MY2023_Tx" SG_ 402 ApaMdeStat_D_RqDrv 1;
BA_ "U_P702_MY2024_Tx" SG_ 402 ApaMdeStat_D_RqDrv 1;
BA_ "GenSigSendType" SG_ 402 ApaFeat_D_RqDrv 3;
BA_ "U_V713AV_MY2022_Tx" SG_ 402 ApaFeat_D_RqDrv 1;
BA_ "U_P708_MY2023_Tx" SG_ 402 ApaFeat_D_RqDrv 1;
BA_ "U_V710_MY2023_Tx" SG_ 402 ApaFeat_D_RqDrv 1;
BA_ "U_P702_MY2024_Tx" SG_ 402 ApaFeat_D_RqDrv 1;
BA_ "GenSigSendType" SG_ 402 ApaFeatChange_B_RqDrv 3;
BA_ "U_V713AV_MY2022_Tx" SG_ 402 ApaFeatChange_B_RqDrv 1;
BA_ "U_P708_MY2023_Tx" SG_ 402 ApaFeatChange_B_RqDrv 1;
BA_ "U_V710_MY2023_Tx" SG_ 402 ApaFeatChange_B_RqDrv 1;
BA_ "U_P702_MY2024_Tx" SG_ 402 ApaFeatChange_B_RqDrv 1;
BA_ "GenSigSendType" SG_ 402 CamraViewSplit_B_Rq 3;
BA_ "U_V713AV_MY2022_Tx" SG_ 402 CamraViewSplit_B_Rq 1;
BA_ "U_P708_MY2023_Tx" SG_ 402 CamraViewSplit_B_Rq 1;
BA_ "U_V710_MY2023_Tx" SG_ 402 CamraViewSplit_B_Rq 1;
BA_ "U_P702_MY2024_Tx" SG_ 402 CamraViewSplit_B_Rq 1;
BA_ "GenSigSendType" SG_ 402 CamraZoomMan_D_Rq 3;
BA_ "U_V713AV_MY2022_Tx" SG_ 402 CamraZoomMan_D_Rq 1;
BA_ "U_P708_MY2023_Tx" SG_ 402 CamraZoomMan_D_Rq 1;
BA_ "U_V710_MY2023_Tx" SG_ 402 CamraZoomMan_D_Rq 1;
BA_ "U_P702_MY2024_Tx" SG_ 402 CamraZoomMan_D_Rq 1;
BA_ "GenSigSendType" SG_ 402 CamraOvrlStat_D_Rq 3;
BA_ "U_V713N_MY2022_Rx" SG_ 402 CamraOvrlStat_D_Rq 1;
BA_ "U_V713AV_MY2022_Rx" SG_ 402 CamraOvrlStat_D_Rq 1;
BA_ "U_V713AV_MY2022_Tx" SG_ 402 CamraOvrlStat_D_Rq 1;
BA_ "U_P708_MY2023_Tx" SG_ 402 CamraOvrlStat_D_Rq 1;
BA_ "U_V710_MY2023_Tx" SG_ 402 CamraOvrlStat_D_Rq 1;
BA_ "U_P702_MY2024_Tx" SG_ 402 CamraOvrlStat_D_Rq 1;
BA_ "GenSigSendType" SG_ 402 CamraOvrlDyn_D_Rq 3;
BA_ "U_V713N_MY2022_Rx" SG_ 402 CamraOvrlDyn_D_Rq 1;
BA_ "U_V713AV_MY2022_Rx" SG_ 402 CamraOvrlDyn_D_Rq 1;
BA_ "U_V713AV_MY2022_Tx" SG_ 402 CamraOvrlDyn_D_Rq 1;
BA_ "U_P708_MY2023_Tx" SG_ 402 CamraOvrlDyn_D_Rq 1;
BA_ "U_V710_MY2023_Tx" SG_ 402 CamraOvrlDyn_D_Rq 1;
BA_ "U_P702_MY2024_Tx" SG_ 402 CamraOvrlDyn_D_Rq 1;
BA_ "GenSigSendType" SG_ 402 CamAutoTowbarZoom 3;
BA_ "U_V713N_MY2022_Rx" SG_ 402 CamAutoTowbarZoom 1;
BA_ "U_V713AV_MY2022_Rx" SG_ 402 CamAutoTowbarZoom 1;
BA_ "U_V713AV_MY2022_Tx" SG_ 402 CamAutoTowbarZoom 1;
BA_ "U_P708_MY2023_Tx" SG_ 402 CamAutoTowbarZoom 1;
BA_ "U_V710_MY2023_Tx" SG_ 402 CamAutoTowbarZoom 1;
BA_ "U_P702_MY2024_Tx" SG_ 402 CamAutoTowbarZoom 1;
BA_ "GenSigSendType" SG_ 402 DistanceBarSetting 3;
BA_ "U_V713AV_MY2022_Tx" SG_ 402 DistanceBarSetting 1;
BA_ "U_P708_MY2023_Tx" SG_ 402 DistanceBarSetting 1;
BA_ "U_V710_MY2023_Tx" SG_ 402 DistanceBarSetting 1;
BA_ "U_P702_MY2024_Tx" SG_ 402 DistanceBarSetting 1;
BA_ "WakeupSignal" SG_ 946 DimmingLvlEvnt_No_Actl 1;
BA_ "U_V713N_MY2022_Rx" SG_ 946 DimmingLvlEvnt_No_Actl 1;
BA_ "U_V713AV_MY2022_Rx" SG_ 946 DimmingLvlEvnt_No_Actl 1;
BA_ "U_P708_MY2023_Rx" SG_ 946 DimmingLvlEvnt_No_Actl 1;
BA_ "U_V710_MY2023_Rx" SG_ 946 DimmingLvlEvnt_No_Actl 1;
BA_ "U_P702_MY2024_Rx" SG_ 946 DimmingLvlEvnt_No_Actl 1;
BA_ "WakeupSignal" SG_ 946 Backlit_LED_Status 1;
BA_ "U_CDX74X_MY2024_Rx" SG_ 946 Backlit_LED_Status 1;
BA_ "U_V710_MY2023_Rx" SG_ 946 Backlit_LED_Status 1;
BA_ "U_P708_MY2023_Rx" SG_ 946 Backlit_LED_Status 1;
BA_ "U_P702_MY2024_Rx" SG_ 946 Backlit_LED_Status 1;
BA_ "U_V713N_MY2022_Rx" SG_ 946 TurnLghtRightOn_B_Stat 1;
BA_ "U_V713AV_MY2022_Rx" SG_ 946 TurnLghtRightOn_B_Stat 1;
BA_ "U_P708_MY2023_Rx" SG_ 946 TurnLghtRightOn_B_Stat 1;
BA_ "U_V710_MY2023_Rx" SG_ 946 TurnLghtRightOn_B_Stat 1;
BA_ "U_P702_MY2024_Rx" SG_ 946 TurnLghtRightOn_B_Stat 1;
BA_ "U_V713N_MY2022_Rx" SG_ 946 TurnLghtLeftOn_B_Stat 1;
BA_ "U_V713AV_MY2022_Rx" SG_ 946 TurnLghtLeftOn_B_Stat 1;
BA_ "U_P708_MY2023_Rx" SG_ 946 TurnLghtLeftOn_B_Stat 1;
BA_ "U_V710_MY2023_Rx" SG_ 946 TurnLghtLeftOn_B_Stat 1;
BA_ "U_CDX74X_MY2024_Rx" SG_ 946 TurnLghtLeftOn_B_Stat 1;
BA_ "U_P702_MY2024_Rx" SG_ 946 TurnLghtLeftOn_B_Stat 1;
BA_ "U_V713N_MY2022_Rx" SG_ 946 FogLghtRearOn_B_Stat 1;
BA_ "U_P708_MY2023_Rx" SG_ 946 FogLghtRearOn_B_Stat 1;
BA_ "U_V710_MY2023_Rx" SG_ 946 FogLghtRearOn_B_Stat 1;
BA_ "U_CDX74X_MY2024_Rx" SG_ 946 FogLghtRearOn_B_Stat 1;
BA_ "U_P702_MY2024_Rx" SG_ 946 FogLghtRearOn_B_Stat 1;
BA_ "WakeupSignal" SG_ 946 TurnLghtRight_D_Rq 1;
BA_ "U_CDX74X_MY2024_Rx" SG_ 946 TurnLghtRight_D_Rq 1;
BA_ "U_V710_MY2023_Rx" SG_ 946 TurnLghtRight_D_Rq 1;
BA_ "U_P708_MY2023_Rx" SG_ 946 TurnLghtRight_D_Rq 1;
BA_ "U_CDX707_MY2023_Rx" SG_ 946 TurnLghtRight_D_Rq 1;
BA_ "U_P702_MY2024_Rx" SG_ 946 TurnLghtRight_D_Rq 1;
BA_ "GenSigStartValue" SG_ 946 IgnKeyType_D_Actl 14;
BA_ "U_V713N_MY2022_Rx" SG_ 946 IgnKeyType_D_Actl 1;
BA_ "U_V713AV_MY2022_Rx" SG_ 946 IgnKeyType_D_Actl 1;
BA_ "U_P708_MY2023_Rx" SG_ 946 IgnKeyType_D_Actl 1;
BA_ "U_V710_MY2023_Rx" SG_ 946 IgnKeyType_D_Actl 1;
BA_ "U_P702_MY2024_Rx" SG_ 946 IgnKeyType_D_Actl 1;
BA_ "WakeupSignal" SG_ 946 Parklamp_Status 1;
BA_ "GenSigStartValue" SG_ 946 Parklamp_Status 1;
BA_ "U_V713N_MY2022_Rx" SG_ 946 Parklamp_Status 1;
BA_ "U_V713AV_MY2022_Rx" SG_ 946 Parklamp_Status 1;
BA_ "U_P708_MY2023_Rx" SG_ 946 Parklamp_Status 1;
BA_ "U_V710_MY2023_Rx" SG_ 946 Parklamp_Status 1;
BA_ "U_CDX74X_MY2024_Rx" SG_ 946 Parklamp_Status 1;
BA_ "U_CDX707_MY2023_Rx" SG_ 946 Parklamp_Status 1;
BA_ "U_P702_MY2024_Rx" SG_ 946 Parklamp_Status 1;
BA_ "WakeupSignal" SG_ 946 Litval 1;
BA_ "U_V713N_MY2022_Rx" SG_ 946 Litval 1;
BA_ "U_V713AV_MY2022_Rx" SG_ 946 Litval 1;
BA_ "U_P708_MY2023_Rx" SG_ 946 Litval 1;
BA_ "U_V710_MY2023_Rx" SG_ 946 Litval 1;
BA_ "U_CDX74X_MY2024_Rx" SG_ 946 Litval 1;
BA_ "U_P702_MY2024_Rx" SG_ 946 Litval 1;
BA_ "WakeupSignal" SG_ 946 Key_In_Ignition_Stat 1;
BA_ "U_V713N_MY2022_Rx" SG_ 946 Key_In_Ignition_Stat 1;
BA_ "U_V713AV_MY2022_Rx" SG_ 946 Key_In_Ignition_Stat 1;
BA_ "U_P708_MY2023_Rx" SG_ 946 Key_In_Ignition_Stat 1;
BA_ "U_V710_MY2023_Rx" SG_ 946 Key_In_Ignition_Stat 1;
BA_ "U_P702_MY2024_Rx" SG_ 946 Key_In_Ignition_Stat 1;
BA_ "WakeupSignal" SG_ 946 Ignition_Status 1;
BA_ "U_V713N_MY2022_Rx" SG_ 946 Ignition_Status 1;
BA_ "U_V713AV_MY2022_Rx" SG_ 946 Ignition_Status 1;
BA_ "U_P708_MY2023_Rx" SG_ 946 Ignition_Status 1;
BA_ "U_V710_MY2023_Rx" SG_ 946 Ignition_Status 1;
BA_ "U_CDX74X_MY2024_Rx" SG_ 946 Ignition_Status 1;
BA_ "U_P702_MY2024_Rx" SG_ 946 Ignition_Status 1;
BA_ "U_CDX707_MY2023_Rx" SG_ 946 Ignition_Status 1;
BA_ "WakeupSignal" SG_ 946 Dimming_Lvl 1;
BA_ "GenSigStartValue" SG_ 946 Dimming_Lvl 12;
BA_ "U_V713N_MY2022_Rx" SG_ 946 Dimming_Lvl 1;
BA_ "U_V713AV_MY2022_Rx" SG_ 946 Dimming_Lvl 1;
BA_ "U_P708_MY2023_Rx" SG_ 946 Dimming_Lvl 1;
BA_ "U_V710_MY2023_Rx" SG_ 946 Dimming_Lvl 1;
BA_ "U_CDX74X_MY2024_Rx" SG_ 946 Dimming_Lvl 1;
BA_ "U_CDX707_MY2023_Rx" SG_ 946 Dimming_Lvl 1;
BA_ "U_P702_MY2024_Rx" SG_ 946 Dimming_Lvl 1;
BA_ "WakeupSignal" SG_ 946 Day_Night_Status 1;
BA_ "U_V713N_MY2022_Rx" SG_ 946 Day_Night_Status 1;
BA_ "U_V713AV_MY2022_Rx" SG_ 946 Day_Night_Status 1;
BA_ "U_P708_MY2023_Rx" SG_ 946 Day_Night_Status 1;
BA_ "U_V710_MY2023_Rx" SG_ 946 Day_Night_Status 1;
BA_ "U_CDX74X_MY2024_Rx" SG_ 946 Day_Night_Status 1;
BA_ "U_P702_MY2024_Rx" SG_ 946 Day_Night_Status 1;
BA_ "WakeupSignal" SG_ 946 Remote_Start_Status 1;
BA_ "U_V713N_MY2022_Rx" SG_ 946 Remote_Start_Status 1;
BA_ "U_V713AV_MY2022_Rx" SG_ 946 Remote_Start_Status 1;
BA_ "U_P708_MY2023_Rx" SG_ 946 Remote_Start_Status 1;
BA_ "U_V710_MY2023_Rx" SG_ 946 Remote_Start_Status 1;
BA_ "U_P702_MY2024_Rx" SG_ 946 Remote_Start_Status 1;
BA_ "WakeupSignal" SG_ 946 DrStatTgate_B_Actl 1;
BA_ "U_V713N_MY2022_Rx" SG_ 946 DrStatTgate_B_Actl 1;
BA_ "U_V713AV_MY2022_Rx" SG_ 946 DrStatTgate_B_Actl 1;
BA_ "U_P708_MY2023_Rx" SG_ 946 DrStatTgate_B_Actl 1;
BA_ "U_V710_MY2023_Rx" SG_ 946 DrStatTgate_B_Actl 1;
BA_ "U_CDX74X_MY2024_Rx" SG_ 946 DrStatTgate_B_Actl 1;
BA_ "U_P702_MY2024_Rx" SG_ 946 DrStatTgate_B_Actl 1;
BA_ "WakeupSignal" SG_ 946 DrStatRr_B_Actl 1;
BA_ "U_V713N_MY2022_Rx" SG_ 946 DrStatRr_B_Actl 1;
BA_ "U_V713AV_MY2022_Rx" SG_ 946 DrStatRr_B_Actl 1;
BA_ "U_P708_MY2023_Rx" SG_ 946 DrStatRr_B_Actl 1;
BA_ "U_V710_MY2023_Rx" SG_ 946 DrStatRr_B_Actl 1;
BA_ "U_CDX74X_MY2024_Rx" SG_ 946 DrStatRr_B_Actl 1;
BA_ "U_P702_MY2024_Rx" SG_ 946 DrStatRr_B_Actl 1;
BA_ "WakeupSignal" SG_ 946 DrStatRl_B_Actl 1;
BA_ "U_V713N_MY2022_Rx" SG_ 946 DrStatRl_B_Actl 1;
BA_ "U_V713AV_MY2022_Rx" SG_ 946 DrStatRl_B_Actl 1;
BA_ "U_P708_MY2023_Rx" SG_ 946 DrStatRl_B_Actl 1;
BA_ "U_V710_MY2023_Rx" SG_ 946 DrStatRl_B_Actl 1;
BA_ "U_CDX74X_MY2024_Rx" SG_ 946 DrStatRl_B_Actl 1;
BA_ "U_P702_MY2024_Rx" SG_ 946 DrStatRl_B_Actl 1;
BA_ "WakeupSignal" SG_ 946 DrStatPsngr_B_Actl 1;
BA_ "U_V713N_MY2022_Rx" SG_ 946 DrStatPsngr_B_Actl 1;
BA_ "U_V713AV_MY2022_Rx" SG_ 946 DrStatPsngr_B_Actl 1;
BA_ "U_P708_MY2023_Rx" SG_ 946 DrStatPsngr_B_Actl 1;
BA_ "U_V710_MY2023_Rx" SG_ 946 DrStatPsngr_B_Actl 1;
BA_ "U_CDX74X_MY2024_Rx" SG_ 946 DrStatPsngr_B_Actl 1;
BA_ "U_P702_MY2024_Rx" SG_ 946 DrStatPsngr_B_Actl 1;
BA_ "U_V713N_MY2022_Rx" SG_ 946 FogLghtFrontOn_B_Stat 1;
BA_ "U_V713AV_MY2022_Rx" SG_ 946 FogLghtFrontOn_B_Stat 1;
BA_ "U_P708_MY2023_Rx" SG_ 946 FogLghtFrontOn_B_Stat 1;
BA_ "U_V710_MY2023_Rx" SG_ 946 FogLghtFrontOn_B_Stat 1;
BA_ "U_P702_MY2024_Rx" SG_ 946 FogLghtFrontOn_B_Stat 1;
BA_ "WakeupSignal" SG_ 946 DrStatInnrTgate_B_Actl 1;
BA_ "U_V713N_MY2022_Rx" SG_ 946 DrStatInnrTgate_B_Actl 1;
BA_ "U_V713AV_MY2022_Rx" SG_ 946 DrStatInnrTgate_B_Actl 1;
BA_ "U_P708_MY2023_Rx" SG_ 946 DrStatInnrTgate_B_Actl 1;
BA_ "U_V710_MY2023_Rx" SG_ 946 DrStatInnrTgate_B_Actl 1;
BA_ "U_CDX74X_MY2024_Rx" SG_ 946 DrStatInnrTgate_B_Actl 1;
BA_ "U_P702_MY2024_Rx" SG_ 946 DrStatInnrTgate_B_Actl 1;
BA_ "WakeupSignal" SG_ 946 DrStatHood_B_Actl 1;
BA_ "U_V713N_MY2022_Rx" SG_ 946 DrStatHood_B_Actl 1;
BA_ "U_V713AV_MY2022_Rx" SG_ 946 DrStatHood_B_Actl 1;
BA_ "U_P708_MY2023_Rx" SG_ 946 DrStatHood_B_Actl 1;
BA_ "U_V710_MY2023_Rx" SG_ 946 DrStatHood_B_Actl 1;
BA_ "U_P702_MY2024_Rx" SG_ 946 DrStatHood_B_Actl 1;
BA_ "WakeupSignal" SG_ 946 DrStatDrv_B_Actl 1;
BA_ "U_V713N_MY2022_Rx" SG_ 946 DrStatDrv_B_Actl 1;
BA_ "U_V713AV_MY2022_Rx" SG_ 946 DrStatDrv_B_Actl 1;
BA_ "U_P708_MY2023_Rx" SG_ 946 DrStatDrv_B_Actl 1;
BA_ "U_V710_MY2023_Rx" SG_ 946 DrStatDrv_B_Actl 1;
BA_ "U_CDX707_MY2023_Rx" SG_ 946 DrStatDrv_B_Actl 1;
BA_ "U_CDX74X_MY2024_Rx" SG_ 946 DrStatDrv_B_Actl 1;
BA_ "U_P702_MY2024_Rx" SG_ 946 DrStatDrv_B_Actl 1;
BA_ "WakeupSignal" SG_ 946 PrkBrkActv_B_Actl 1;
BA_ "U_V713N_MY2022_Rx" SG_ 946 PrkBrkActv_B_Actl 1;
BA_ "U_V713AV_MY2022_Rx" SG_ 946 PrkBrkActv_B_Actl 1;
BA_ "U_V710_MY2023_Rx" SG_ 946 PrkBrkActv_B_Actl 1;
BA_ "U_P708_MY2023_Rx" SG_ 946 PrkBrkActv_B_Actl 1;
BA_ "U_P702_MY2024_Rx" SG_ 946 PrkBrkActv_B_Actl 1;
BA_ "U_V713N_MY2022_Rx" SG_ 946 LifeCycMde_D_Actl 1;
BA_ "U_V713AV_MY2022_Rx" SG_ 946 LifeCycMde_D_Actl 1;
BA_ "U_P708_MY2023_Rx" SG_ 946 LifeCycMde_D_Actl 1;
BA_ "U_V710_MY2023_Rx" SG_ 946 LifeCycMde_D_Actl 1;
BA_ "U_CDX74X_MY2024_Rx" SG_ 946 LifeCycMde_D_Actl 1;
BA_ "U_P702_MY2024_Rx" SG_ 946 LifeCycMde_D_Actl 1;
BA_ "U_CDX707_MY2023_Rx" SG_ 946 LifeCycMde_D_Actl 1;
BA_ "WakeupSignal" SG_ 946 Delay_Accy 1;
BA_ "U_V713N_MY2022_Rx" SG_ 946 Delay_Accy 1;
BA_ "U_V713AV_MY2022_Rx" SG_ 946 Delay_Accy 1;
BA_ "U_P708_MY2023_Rx" SG_ 946 Delay_Accy 1;
BA_ "U_V710_MY2023_Rx" SG_ 946 Delay_Accy 1;
BA_ "U_CDX74X_MY2024_Rx" SG_ 946 Delay_Accy 1;
BA_ "U_P702_MY2024_Rx" SG_ 946 Delay_Accy 1;
BA_ "WakeupSignal" SG_ 946 TurnLghtLeft_D_Rq 1;
BA_ "U_P708_MY2023_Rx" SG_ 946 TurnLghtLeft_D_Rq 1;
BA_ "U_CDX707_MY2023_Rx" SG_ 946 TurnLghtLeft_D_Rq 1;
BA_ "U_CDX74X_MY2024_Rx" SG_ 946 TurnLghtLeft_D_Rq 1;
BA_ "U_V710_MY2023_Rx" SG_ 946 TurnLghtLeft_D_Rq 1;
BA_ "U_P702_MY2024_Rx" SG_ 946 TurnLghtLeft_D_Rq 1;
BA_ "WakeupSignal" SG_ 946 CrashEvnt_D_Stat 1;
BA_ "GenSigStartValue" SG_ 946 CrashEvnt_D_Stat 3;
BA_ "U_V713N_MY2022_Rx" SG_ 946 BodySrvcRqd_B_Rq 1;
BA_ "U_V713AV_MY2022_Rx" SG_ 946 BodySrvcRqd_B_Rq 1;
BA_ "U_P708_MY2023_Rx" SG_ 946 BodySrvcRqd_B_Rq 1;
BA_ "U_V710_MY2023_Rx" SG_ 946 BodySrvcRqd_B_Rq 1;
BA_ "U_P702_MY2024_Rx" SG_ 946 BodySrvcRqd_B_Rq 1;
BA_ "GenSigSendType" SG_ 778 PrkAidAcsyRear_D_RqDrv 3;
BA_ "U_V713AV_MY2022_Tx" SG_ 778 PrkAidAcsyRear_D_RqDrv 1;
BA_ "U_P708_MY2023_Tx" SG_ 778 PrkAidAcsyRear_D_RqDrv 1;
BA_ "U_V710_MY2023_Tx" SG_ 778 PrkAidAcsyRear_D_RqDrv 1;
BA_ "U_V713N_MY2022_Tx" SG_ 778 PrkAidAcsyRear_D_RqDrv 1;
BA_ "U_P702_MY2024_Tx" SG_ 778 PrkAidAcsyRear_D_RqDrv 1;
BA_ "GenSigSendType" SG_ 778 PrkAidAcsyFront_D_RqDrv 3;
BA_ "U_V713AV_MY2022_Tx" SG_ 778 PrkAidAcsyFront_D_RqDrv 1;
BA_ "U_P708_MY2023_Tx" SG_ 778 PrkAidAcsyFront_D_RqDrv 1;
BA_ "U_V710_MY2023_Tx" SG_ 778 PrkAidAcsyFront_D_RqDrv 1;
BA_ "U_V713N_MY2022_Tx" SG_ 778 PrkAidAcsyFront_D_RqDrv 1;
BA_ "U_P702_MY2024_Tx" SG_ 778 PrkAidAcsyFront_D_RqDrv 1;
BA_ "GenSigStartValue" SG_ 778 Cta_D_Rq 1;
BA_ "GenSigSendType" SG_ 778 Cta_D_Rq 3;
BA_ "U_V713N_MY2022_Tx" SG_ 778 Cta_D_Rq 1;
BA_ "U_V713AV_MY2022_Tx" SG_ 778 Cta_D_Rq 1;
BA_ "U_P708_MY2023_Tx" SG_ 778 Cta_D_Rq 1;
BA_ "U_V710_MY2023_Tx" SG_ 778 Cta_D_Rq 1;
BA_ "U_P702_MY2024_Tx" SG_ 778 Cta_D_Rq 1;
BA_ "GenSigSendType" SG_ 778 PrkAidRear_D_RqDrv 3;
BA_ "U_V713N_MY2022_Tx" SG_ 778 PrkAidRear_D_RqDrv 1;
BA_ "U_V713AV_MY2022_Tx" SG_ 778 PrkAidRear_D_RqDrv 1;
BA_ "U_P708_MY2023_Tx" SG_ 778 PrkAidRear_D_RqDrv 1;
BA_ "U_V710_MY2023_Tx" SG_ 778 PrkAidRear_D_RqDrv 1;
BA_ "U_P702_MY2024_Tx" SG_ 778 PrkAidRear_D_RqDrv 1;
BA_ "GenSigSendType" SG_ 778 PrkAidFront_D_RqDrv 3;
BA_ "U_V713N_MY2022_Tx" SG_ 778 PrkAidFront_D_RqDrv 1;
BA_ "U_V713AV_MY2022_Tx" SG_ 778 PrkAidFront_D_RqDrv 1;
BA_ "U_P708_MY2023_Tx" SG_ 778 PrkAidFront_D_RqDrv 1;
BA_ "U_V710_MY2023_Tx" SG_ 778 PrkAidFront_D_RqDrv 1;
BA_ "U_P702_MY2024_Tx" SG_ 778 PrkAidFront_D_RqDrv 1;
BA_ "GenSigSendType" SG_ 778 SteEffort_D_Rq 3;
BA_ "U_V713N_MY2022_Tx" SG_ 778 SteEffort_D_Rq 1;
BA_ "U_V713AV_MY2022_Tx" SG_ 778 SteEffort_D_Rq 1;
BA_ "U_P708_MY2023_Tx" SG_ 778 SteEffort_D_Rq 1;
BA_ "U_V710_MY2023_Tx" SG_ 778 SteEffort_D_Rq 1;
BA_ "U_P702_MY2024_Tx" SG_ 778 SteEffort_D_Rq 1;
BA_ "GenSigSendType" SG_ 778 ClrExitAsstEnbl_D_RqDrv 3;
BA_ "U_V713AV_MY2022_Tx" SG_ 778 ClrExitAsstEnbl_D_RqDrv 1;
BA_ "U_P708_MY2023_Tx" SG_ 778 ClrExitAsstEnbl_D_RqDrv 1;
BA_ "U_V710_MY2023_Tx" SG_ 778 ClrExitAsstEnbl_D_RqDrv 1;
BA_ "U_P702_MY2024_Tx" SG_ 778 ClrExitAsstEnbl_D_RqDrv 1;
BA_ "GenSigStartValue" SG_ 778 Sod_D_Rq 2;
BA_ "GenSigSendType" SG_ 778 Sod_D_Rq 3;
BA_ "U_V713N_MY2022_Tx" SG_ 778 Sod_D_Rq 1;
BA_ "U_V713AV_MY2022_Tx" SG_ 778 Sod_D_Rq 1;
BA_ "U_P708_MY2023_Tx" SG_ 778 Sod_D_Rq 1;
BA_ "U_V710_MY2023_Tx" SG_ 778 Sod_D_Rq 1;
BA_ "U_P702_MY2024_Tx" SG_ 778 Sod_D_Rq 1;
BA_ "U_V713N_MY2022_Rx" SG_ 1093 TrlBrkInitOut_D_Stat 1;
BA_ "U_V713AV_MY2022_Rx" SG_ 1093 TrlBrkInitOut_D_Stat 1;
BA_ "U_P708_MY2023_Rx" SG_ 1093 TrlBrkInitOut_D_Stat 1;
BA_ "U_V710_MY2023_Rx" SG_ 1093 TrlBrkInitOut_D_Stat 1;
BA_ "U_P702_MY2024_Rx" SG_ 1093 TrlBrkInitOut_D_Stat 1;
BA_ "U_P708_MY2023_Tx" SG_ 1093 TrlBrkInitOut_D_Stat 1;
BA_ "U_P702_MY2024_Tx" SG_ 1093 TrlBrkInitOut_D_Stat 1;
BA_ "U_V713N_MY2022_Rx" SG_ 1093 TrlrBrkOut_No_Dsply 1;
BA_ "U_V713AV_MY2022_Rx" SG_ 1093 TrlrBrkOut_No_Dsply 1;
BA_ "U_P708_MY2023_Rx" SG_ 1093 TrlrBrkOut_No_Dsply 1;
BA_ "U_V710_MY2023_Rx" SG_ 1093 TrlrBrkOut_No_Dsply 1;
BA_ "U_P702_MY2024_Rx" SG_ 1093 TrlrBrkOut_No_Dsply 1;
BA_ "U_P708_MY2023_Tx" SG_ 1093 TrlrBrkOut_No_Dsply 1;
BA_ "U_P702_MY2024_Tx" SG_ 1093 TrlrBrkOut_No_Dsply 1;
BA_ "U_V713N_MY2022_Rx" SG_ 1093 TrlrBrkMde_D_Actl 1;
BA_ "U_V713AV_MY2022_Rx" SG_ 1093 TrlrBrkMde_D_Actl 1;
BA_ "U_P708_MY2023_Rx" SG_ 1093 TrlrBrkMde_D_Actl 1;
BA_ "U_V710_MY2023_Rx" SG_ 1093 TrlrBrkMde_D_Actl 1;
BA_ "U_P702_MY2024_Rx" SG_ 1093 TrlrBrkMde_D_Actl 1;
BA_ "U_P708_MY2023_Tx" SG_ 1093 TrlrBrkMde_D_Actl 1;
BA_ "U_P702_MY2024_Tx" SG_ 1093 TrlrBrkMde_D_Actl 1;
BA_ "U_V713N_MY2022_Rx" SG_ 1093 TrlrBrkGain_No_Actl 1;
BA_ "U_V713AV_MY2022_Rx" SG_ 1093 TrlrBrkGain_No_Actl 1;
BA_ "U_P708_MY2023_Rx" SG_ 1093 TrlrBrkGain_No_Actl 1;
BA_ "U_V710_MY2023_Rx" SG_ 1093 TrlrBrkGain_No_Actl 1;
BA_ "U_P702_MY2024_Rx" SG_ 1093 TrlrBrkGain_No_Actl 1;
BA_ "U_P708_MY2023_Tx" SG_ 1093 TrlrBrkGain_No_Actl 1;
BA_ "U_P702_MY2024_Tx" SG_ 1093 TrlrBrkGain_No_Actl 1;
BA_ "U_V713N_MY2022_Rx" SG_ 1093 TrlrBrkDsply_B_Rq 1;
BA_ "U_V713AV_MY2022_Rx" SG_ 1093 TrlrBrkDsply_B_Rq 1;
BA_ "U_P708_MY2023_Rx" SG_ 1093 TrlrBrkDsply_B_Rq 1;
BA_ "U_V710_MY2023_Rx" SG_ 1093 TrlrBrkDsply_B_Rq 1;
BA_ "U_P702_MY2024_Rx" SG_ 1093 TrlrBrkDsply_B_Rq 1;
BA_ "U_P708_MY2023_Tx" SG_ 1093 TrlrBrkDsply_B_Rq 1;
BA_ "U_P702_MY2024_Tx" SG_ 1093 TrlrBrkDsply_B_Rq 1;
BA_ "U_V713N_MY2022_Rx" SG_ 1093 TrlrBrkDcnnt_B_Actl 1;
BA_ "U_V713AV_MY2022_Rx" SG_ 1093 TrlrBrkDcnnt_B_Actl 1;
BA_ "U_P708_MY2023_Rx" SG_ 1093 TrlrBrkDcnnt_B_Actl 1;
BA_ "U_V710_MY2023_Rx" SG_ 1093 TrlrBrkDcnnt_B_Actl 1;
BA_ "U_P702_MY2024_Rx" SG_ 1093 TrlrBrkDcnnt_B_Actl 1;
BA_ "U_P708_MY2023_Tx" SG_ 1093 TrlrBrkDcnnt_B_Actl 1;
BA_ "U_P702_MY2024_Tx" SG_ 1093 TrlrBrkDcnnt_B_Actl 1;
BA_ "U_V713N_MY2022_Rx" SG_ 1093 TrlrBrkActCnnct_B_Actl 1;
BA_ "U_V713AV_MY2022_Rx" SG_ 1093 TrlrBrkActCnnct_B_Actl 1;
BA_ "U_P708_MY2023_Rx" SG_ 1093 TrlrBrkActCnnct_B_Actl 1;
BA_ "U_V710_MY2023_Rx" SG_ 1093 TrlrBrkActCnnct_B_Actl 1;
BA_ "U_P702_MY2024_Rx" SG_ 1093 TrlrBrkActCnnct_B_Actl 1;
BA_ "U_P708_MY2023_Tx" SG_ 1093 TrlrBrkActCnnct_B_Actl 1;
BA_ "U_P702_MY2024_Tx" SG_ 1093 TrlrBrkActCnnct_B_Actl 1;
BA_ "U_P708_MY2023_Tx" SG_ 1093 StopLamp_B_RqTrlrBrk 1;
BA_ "U_P702_MY2024_Tx" SG_ 1093 StopLamp_B_RqTrlrBrk 1;
BA_ "U_V713N_MY2022_Rx" SG_ 1093 TrlrBrkCtl_B_Falt 1;
BA_ "U_V713AV_MY2022_Rx" SG_ 1093 TrlrBrkCtl_B_Falt 1;
BA_ "U_P708_MY2023_Rx" SG_ 1093 TrlrBrkCtl_B_Falt 1;
BA_ "U_V710_MY2023_Rx" SG_ 1093 TrlrBrkCtl_B_Falt 1;
BA_ "U_P702_MY2024_Rx" SG_ 1093 TrlrBrkCtl_B_Falt 1;
BA_ "U_P708_MY2023_Tx" SG_ 1093 TrlrBrkCtl_B_Falt 1;
BA_ "U_P702_MY2024_Tx" SG_ 1093 TrlrBrkCtl_B_Falt 1;
BA_ "U_V713N_MY2022_Rx" SG_ 1093 TrlrBrkActCirct_B_Falt 1;
BA_ "U_V713AV_MY2022_Rx" SG_ 1093 TrlrBrkActCirct_B_Falt 1;
BA_ "U_P708_MY2023_Rx" SG_ 1093 TrlrBrkActCirct_B_Falt 1;
BA_ "U_V710_MY2023_Rx" SG_ 1093 TrlrBrkActCirct_B_Falt 1;
BA_ "U_P702_MY2024_Rx" SG_ 1093 TrlrBrkActCirct_B_Falt 1;
BA_ "U_P708_MY2023_Tx" SG_ 1093 TrlrBrkActCirct_B_Falt 1;
BA_ "U_P702_MY2024_Tx" SG_ 1093 TrlrBrkActCirct_B_Falt 1;
BA_ "GenSigSendType" SG_ 1879 TesterPhysicalReqTBM 3;
BA_ "U_V713N_MY2022_Rx" SG_ 999 FeatNoFcimActl 1;
BA_ "U_V713AV_MY2022_Rx" SG_ 999 FeatNoFcimActl 1;
BA_ "U_P708_MY2023_Rx" SG_ 999 FeatNoFcimActl 1;
BA_ "U_V710_MY2023_Rx" SG_ 999 FeatNoFcimActl 1;
BA_ "U_P702_MY2024_Rx" SG_ 999 FeatNoFcimActl 1;
BA_ "U_V713N_MY2022_Rx" SG_ 999 FeatConfigFcimActl 1;
BA_ "U_V713AV_MY2022_Rx" SG_ 999 FeatConfigFcimActl 1;
BA_ "U_P708_MY2023_Rx" SG_ 999 FeatConfigFcimActl 1;
BA_ "U_V710_MY2023_Rx" SG_ 999 FeatConfigFcimActl 1;
BA_ "U_P702_MY2024_Rx" SG_ 999 FeatConfigFcimActl 1;
BA_ "GenSigStartValue" SG_ 999 PersIndexFcim_D_Actl 4;
BA_ "U_V713N_MY2022_Rx" SG_ 999 PersIndexFcim_D_Actl 1;
BA_ "U_V713AV_MY2022_Rx" SG_ 999 PersIndexFcim_D_Actl 1;
BA_ "U_P708_MY2023_Rx" SG_ 999 PersIndexFcim_D_Actl 1;
BA_ "U_V710_MY2023_Rx" SG_ 999 PersIndexFcim_D_Actl 1;
BA_ "U_P702_MY2024_Rx" SG_ 999 PersIndexFcim_D_Actl 1;
BA_ "GenSigStartValue" SG_ 1002 PersIndexApim_D_Actl 4;
BA_ "GenSigSendType" SG_ 1002 PersIndexApim_D_Actl 3;
BA_ "U_V713N_MY2022_Rx" SG_ 1002 PersIndexApim_D_Actl 1;
BA_ "U_V713AV_MY2022_Rx" SG_ 1002 PersIndexApim_D_Actl 1;
BA_ "U_V710_MY2023_Tx" SG_ 1002 PersIndexApim_D_Actl 1;
BA_ "U_P708_MY2023_Tx" SG_ 1002 PersIndexApim_D_Actl 1;
BA_ "GenSigSendType" SG_ 1002 FeatNoApimActl 3;
BA_ "U_V713N_MY2022_Rx" SG_ 1002 FeatNoApimActl 1;
BA_ "U_V713AV_MY2022_Rx" SG_ 1002 FeatNoApimActl 1;
BA_ "U_V710_MY2023_Tx" SG_ 1002 FeatNoApimActl 1;
BA_ "U_P708_MY2023_Tx" SG_ 1002 FeatNoApimActl 1;
BA_ "GenSigSendType" SG_ 1002 FeatConfigApimActl 3;
BA_ "U_V713N_MY2022_Rx" SG_ 1002 FeatConfigApimActl 1;
BA_ "U_V713AV_MY2022_Rx" SG_ 1002 FeatConfigApimActl 1;
BA_ "U_V710_MY2023_Tx" SG_ 1002 FeatConfigApimActl 1;
BA_ "U_P708_MY2023_Tx" SG_ 1002 FeatConfigApimActl 1;
BA_ "GenSigSendType" SG_ 1002 CntrStkKeycodeActl 3;
BA_ "U_V710_MY2023_Tx" SG_ 1002 CntrStkKeycodeActl 1;
BA_ "U_P708_MY2023_Tx" SG_ 1002 CntrStkKeycodeActl 1;
BA_ "U_P702_MY2024_Tx" SG_ 1002 CntrStkKeycodeActl 1;
BA_ "WakeupSignal" SG_ 1002 CntrStk_D_RqRecall 1;
BA_ "GenSigSendType" SG_ 1002 CntrStk_D_RqRecall 3;
BA_ "U_V710_MY2023_Tx" SG_ 1002 CntrStk_D_RqRecall 1;
BA_ "U_P708_MY2023_Tx" SG_ 1002 CntrStk_D_RqRecall 1;
BA_ "U_P702_MY2024_Tx" SG_ 1002 CntrStk_D_RqRecall 1;
BA_ "GenSigStartValue" SG_ 1002 CntrStk_D_RqAssoc 3;
BA_ "GenSigSendType" SG_ 1002 CntrStk_D_RqAssoc 3;
BA_ "U_V710_MY2023_Tx" SG_ 1002 CntrStk_D_RqAssoc 1;
BA_ "U_P708_MY2023_Tx" SG_ 1002 CntrStk_D_RqAssoc 1;
BA_ "U_P702_MY2024_Tx" SG_ 1002 CntrStk_D_RqAssoc 1;
BA_ "U_V710_MY2023_Rx" SG_ 948 TlghtTestPrecnd_D2_Stat 1;
BA_ "U_P708_MY2023_Rx" SG_ 948 TlghtTestPrecnd_D2_Stat 1;
BA_ "U_P702_MY2024_Rx" SG_ 948 TlghtTestPrecnd_D2_Stat 1;
BA_ "U_V710_MY2023_Rx" SG_ 948 TlghtTestLght_D2_Stat 1;
BA_ "U_P708_MY2023_Rx" SG_ 948 TlghtTestLght_D2_Stat 1;
BA_ "U_P702_MY2024_Rx" SG_ 948 TlghtTestLght_D2_Stat 1;
BA_ "GenSigStartValue" SG_ 948 Tire_Press_Placrd_Rear 255;
BA_ "U_V713N_MY2022_Rx" SG_ 948 Tire_Press_Placrd_Rear 1;
BA_ "U_V713AV_MY2022_Rx" SG_ 948 Tire_Press_Placrd_Rear 1;
BA_ "U_P708_MY2023_Rx" SG_ 948 Tire_Press_Placrd_Rear 1;
BA_ "U_V710_MY2023_Rx" SG_ 948 Tire_Press_Placrd_Rear 1;
BA_ "U_P702_MY2024_Rx" SG_ 948 Tire_Press_Placrd_Rear 1;
BA_ "GenSigStartValue" SG_ 948 Tire_Press_Placrd_Frnt 255;
BA_ "U_V713N_MY2022_Rx" SG_ 948 Tire_Press_Placrd_Frnt 1;
BA_ "U_V713AV_MY2022_Rx" SG_ 948 Tire_Press_Placrd_Frnt 1;
BA_ "U_P708_MY2023_Rx" SG_ 948 Tire_Press_Placrd_Frnt 1;
BA_ "U_V710_MY2023_Rx" SG_ 948 Tire_Press_Placrd_Frnt 1;
BA_ "U_P702_MY2024_Rx" SG_ 948 Tire_Press_Placrd_Frnt 1;
BA_ "U_V713N_MY2022_Rx" SG_ 948 TirePReset_D_Stat 1;
BA_ "U_V713AV_MY2022_Rx" SG_ 948 TirePReset_D_Stat 1;
BA_ "U_P708_MY2023_Rx" SG_ 948 TirePReset_D_Stat 1;
BA_ "U_V710_MY2023_Rx" SG_ 948 TirePReset_D_Stat 1;
BA_ "U_P702_MY2024_Rx" SG_ 948 TirePReset_D_Stat 1;
BA_ "U_V713N_MY2022_Rx" SG_ 948 Tire_Press_ILR_Stat 1;
BA_ "U_V713AV_MY2022_Rx" SG_ 948 Tire_Press_ILR_Stat 1;
BA_ "U_P708_MY2023_Rx" SG_ 948 Tire_Press_ILR_Stat 1;
BA_ "U_V710_MY2023_Rx" SG_ 948 Tire_Press_ILR_Stat 1;
BA_ "U_P702_MY2024_Rx" SG_ 948 Tire_Press_ILR_Stat 1;
BA_ "U_V713N_MY2022_Rx" SG_ 948 Tire_Press_IRR_Stat 1;
BA_ "U_V713AV_MY2022_Rx" SG_ 948 Tire_Press_IRR_Stat 1;
BA_ "U_P708_MY2023_Rx" SG_ 948 Tire_Press_IRR_Stat 1;
BA_ "U_V710_MY2023_Rx" SG_ 948 Tire_Press_IRR_Stat 1;
BA_ "U_P702_MY2024_Rx" SG_ 948 Tire_Press_IRR_Stat 1;
BA_ "U_V713N_MY2022_Rx" SG_ 948 Tire_Press_LR_OLR_Stat 1;
BA_ "U_V713AV_MY2022_Rx" SG_ 948 Tire_Press_LR_OLR_Stat 1;
BA_ "U_P708_MY2023_Rx" SG_ 948 Tire_Press_LR_OLR_Stat 1;
BA_ "U_V710_MY2023_Rx" SG_ 948 Tire_Press_LR_OLR_Stat 1;
BA_ "U_P702_MY2024_Rx" SG_ 948 Tire_Press_LR_OLR_Stat 1;
BA_ "U_V713N_MY2022_Rx" SG_ 948 Tire_Press_RR_ORR_Stat 1;
BA_ "U_V713AV_MY2022_Rx" SG_ 948 Tire_Press_RR_ORR_Stat 1;
BA_ "U_P708_MY2023_Rx" SG_ 948 Tire_Press_RR_ORR_Stat 1;
BA_ "U_V710_MY2023_Rx" SG_ 948 Tire_Press_RR_ORR_Stat 1;
BA_ "U_P702_MY2024_Rx" SG_ 948 Tire_Press_RR_ORR_Stat 1;
BA_ "U_V713N_MY2022_Rx" SG_ 948 Tire_Press_RF_Stat 1;
BA_ "U_V713AV_MY2022_Rx" SG_ 948 Tire_Press_RF_Stat 1;
BA_ "U_P708_MY2023_Rx" SG_ 948 Tire_Press_RF_Stat 1;
BA_ "U_V710_MY2023_Rx" SG_ 948 Tire_Press_RF_Stat 1;
BA_ "U_P702_MY2024_Rx" SG_ 948 Tire_Press_RF_Stat 1;
BA_ "U_V713N_MY2022_Rx" SG_ 948 Tire_Press_LF_Stat 1;
BA_ "U_V713AV_MY2022_Rx" SG_ 948 Tire_Press_LF_Stat 1;
BA_ "U_P708_MY2023_Rx" SG_ 948 Tire_Press_LF_Stat 1;
BA_ "U_V710_MY2023_Rx" SG_ 948 Tire_Press_LF_Stat 1;
BA_ "U_P702_MY2024_Rx" SG_ 948 Tire_Press_LF_Stat 1;
BA_ "U_V713N_MY2022_Rx" SG_ 948 Tire_Press_System_Stat 1;
BA_ "U_V713AV_MY2022_Rx" SG_ 948 Tire_Press_System_Stat 1;
BA_ "U_P708_MY2023_Rx" SG_ 948 Tire_Press_System_Stat 1;
BA_ "U_V710_MY2023_Rx" SG_ 948 Tire_Press_System_Stat 1;
BA_ "U_P702_MY2024_Rx" SG_ 948 Tire_Press_System_Stat 1;
BA_ "U_V713N_MY2022_Rx" SG_ 948 Tire_Press_Telltale 1;
BA_ "U_V713AV_MY2022_Rx" SG_ 948 Tire_Press_Telltale 1;
BA_ "U_P708_MY2023_Rx" SG_ 948 Tire_Press_Telltale 1;
BA_ "U_V710_MY2023_Rx" SG_ 948 Tire_Press_Telltale 1;
BA_ "U_P702_MY2024_Rx" SG_ 948 Tire_Press_Telltale 1;
BA_ "GenSigStartValue" SG_ 986 PsngrLoad_M_Rq 1022;
BA_ "GenSigSendType" SG_ 986 VehPayloadScrn_D_Rq 3;
BA_ "U_V710_MY2023_Tx" SG_ 986 VehPayloadScrn_D_Rq 1;
BA_ "U_P708_MY2023_Tx" SG_ 986 VehPayloadScrn_D_Rq 1;
BA_ "U_P702_MY2024_Tx" SG_ 986 VehPayloadScrn_D_Rq 1;
BA_ "GenSigStartValue" SG_ 986 Trlr_M_Rq 2046;
BA_ "GenSigSendType" SG_ 986 Trlr_M_Rq 3;
BA_ "U_V710_MY2023_Tx" SG_ 986 Trlr_M_Rq 1;
BA_ "U_P708_MY2023_Tx" SG_ 986 Trlr_M_Rq 1;
BA_ "U_P702_MY2024_Tx" SG_ 986 Trlr_M_Rq 1;
BA_ "GenSigSendType" SG_ 986 VehPayloadTare_D_Rq 3;
BA_ "U_V710_MY2023_Tx" SG_ 986 VehPayloadTare_D_Rq 1;
BA_ "U_P708_MY2023_Tx" SG_ 986 VehPayloadTare_D_Rq 1;
BA_ "U_P702_MY2024_Tx" SG_ 986 VehPayloadTare_D_Rq 1;
BA_ "GenSigSendType" SG_ 986 VehFalr_D_Rq 3;
BA_ "U_V710_MY2023_Tx" SG_ 986 VehFalr_D_Rq 1;
BA_ "U_P708_MY2023_Tx" SG_ 986 VehFalr_D_Rq 1;
BA_ "U_P702_MY2024_Tx" SG_ 986 VehFalr_D_Rq 1;
BA_ "GenSigSendType" SG_ 986 TailLghtLoadMde_D_Rq 3;
BA_ "U_V710_MY2023_Tx" SG_ 986 TailLghtLoadMde_D_Rq 1;
BA_ "U_P708_MY2023_Tx" SG_ 986 TailLghtLoadMde_D_Rq 1;
BA_ "U_P702_MY2024_Tx" SG_ 986 TailLghtLoadMde_D_Rq 1;
BA_ "GenSigSendType" SG_ 986 LightAmbIntsty_No_Rq 3;
BA_ "U_V710_MY2023_Tx" SG_ 986 LightAmbIntsty_No_Rq 1;
BA_ "U_P708_MY2023_Tx" SG_ 986 LightAmbIntsty_No_Rq 1;
BA_ "U_P702_MY2024_Tx" SG_ 986 LightAmbIntsty_No_Rq 1;
BA_ "GenSigSendType" SG_ 986 LightAmbColor_No_Rq 3;
BA_ "U_V710_MY2023_Tx" SG_ 986 LightAmbColor_No_Rq 1;
BA_ "U_P708_MY2023_Tx" SG_ 986 LightAmbColor_No_Rq 1;
BA_ "U_P702_MY2024_Tx" SG_ 986 LightAmbColor_No_Rq 1;
BA_ "U_V710_MY2023_Rx" SG_ 993 StmsScrnDrvOn_B_Rq 1;
BA_ "U_P708_MY2023_Rx" SG_ 993 StmsScrnDrvOn_B_Rq 1;
BA_ "U_P702_MY2024_Rx" SG_ 993 StmsScrnDrvOn_B_Rq 1;
BA_ "U_V710_MY2023_Rx" SG_ 993 EmButtn_D_Stat 1;
BA_ "U_P708_MY2023_Rx" SG_ 993 EmButtn_D_Stat 1;
BA_ "U_P702_MY2024_Rx" SG_ 993 EmButtn_D_Stat 1;
BA_ "U_V713N_MY2022_Rx" SG_ 993 MemStoreMsgTxt_D_Rq 1;
BA_ "U_V713AV_MY2022_Rx" SG_ 993 MemStoreMsgTxt_D_Rq 1;
BA_ "U_P708_MY2023_Rx" SG_ 993 MemStoreMsgTxt_D_Rq 1;
BA_ "U_V710_MY2023_Rx" SG_ 993 MemStoreMsgTxt_D_Rq 1;
BA_ "U_P702_MY2024_Rx" SG_ 993 MemStoreMsgTxt_D_Rq 1;
BA_ "U_V713N_MY2022_Rx" SG_ 993 MemSetButtnMsgTxt_D_Rq 1;
BA_ "U_V713AV_MY2022_Rx" SG_ 993 MemSetButtnMsgTxt_D_Rq 1;
BA_ "U_P708_MY2023_Rx" SG_ 993 MemSetButtnMsgTxt_D_Rq 1;
BA_ "U_V710_MY2023_Rx" SG_ 993 MemSetButtnMsgTxt_D_Rq 1;
BA_ "U_P702_MY2024_Rx" SG_ 993 MemSetButtnMsgTxt_D_Rq 1;
BA_ "WakeupSignal" SG_ 993 MemSwtch_D_RqRecall 1;
BA_ "WakeupSignal" SG_ 993 MemSwtch_D_RqAssoc 1;
BA_ "GenSigStartValue" SG_ 993 PersIndexDsm_D_Actl 4;
BA_ "U_V713N_MY2022_Rx" SG_ 993 PersIndexDsm_D_Actl 1;
BA_ "U_V713AV_MY2022_Rx" SG_ 993 PersIndexDsm_D_Actl 1;
BA_ "U_P708_MY2023_Rx" SG_ 993 PersIndexDsm_D_Actl 1;
BA_ "U_V710_MY2023_Rx" SG_ 993 PersIndexDsm_D_Actl 1;
BA_ "U_P702_MY2024_Rx" SG_ 993 PersIndexDsm_D_Actl 1;
BA_ "U_V713N_MY2022_Rx" SG_ 993 FeatNoDsmActl 1;
BA_ "U_V713AV_MY2022_Rx" SG_ 993 FeatNoDsmActl 1;
BA_ "U_P708_MY2023_Rx" SG_ 993 FeatNoDsmActl 1;
BA_ "U_V710_MY2023_Rx" SG_ 993 FeatNoDsmActl 1;
BA_ "U_P702_MY2024_Rx" SG_ 993 FeatNoDsmActl 1;
BA_ "U_V713N_MY2022_Rx" SG_ 993 FeatConfigDsmActl 1;
BA_ "U_V713AV_MY2022_Rx" SG_ 993 FeatConfigDsmActl 1;
BA_ "U_P708_MY2023_Rx" SG_ 993 FeatConfigDsmActl 1;
BA_ "U_V710_MY2023_Rx" SG_ 993 FeatConfigDsmActl 1;
BA_ "U_P702_MY2024_Rx" SG_ 993 FeatConfigDsmActl 1;
BA_ "U_V710_MY2023_Rx" SG_ 993 PersStore_D_Actl 1;
BA_ "U_P708_MY2023_Rx" SG_ 993 PersStore_D_Actl 1;
BA_ "U_P702_MY2024_Rx" SG_ 993 PersStore_D_Actl 1;
BA_ "U_V710_MY2023_Rx" SG_ 710 BEZEL_RDISP_WORD_Tx 1;
BA_ "U_P708_MY2023_Rx" SG_ 710 BEZEL_RDISP_WORD_Tx 1;
BA_ "U_P702_MY2024_Rx" SG_ 710 BEZEL_RDISP_WORD_Tx 1;
BA_ "GenSigSendType" SG_ 1814 TesterPhysicalReqGWM_H3 3;
BA_ "ECGUsedRxSignal" SG_ 1814 TesterPhysicalReqGWM_H3 1;
BA_ "U_V713N_MY2022_Rx" SG_ 1814 TesterPhysicalReqGWM_H3 1;
BA_ "U_V713AV_MY2022_Rx" SG_ 1814 TesterPhysicalReqGWM_H3 1;
BA_ "U_P708_MY2023_Rx" SG_ 1814 TesterPhysicalReqGWM_H3 1;
BA_ "U_CDX74X_MY2024_Rx" SG_ 1814 TesterPhysicalReqGWM_H3 1;
BA_ "U_V710_MY2023_Rx" SG_ 1814 TesterPhysicalReqGWM_H3 1;
BA_ "GenSigStartValue" SG_ 997 PersTurnSglView_D_Stat 3;
BA_ "U_V710_MY2023_Rx" SG_ 997 PersTurnSglView_D_Stat 1;
BA_ "U_P708_MY2023_Rx" SG_ 997 PersTurnSglView_D_Stat 1;
BA_ "U_P702_MY2024_Rx" SG_ 997 PersTurnSglView_D_Stat 1;
BA_ "GenSigStartValue" SG_ 997 PersIndexCcm_D_Actl 4;
BA_ "U_V713N_MY2022_Rx" SG_ 997 PersIndexCcm_D_Actl 1;
BA_ "U_V713AV_MY2022_Rx" SG_ 997 PersIndexCcm_D_Actl 1;
BA_ "U_P708_MY2023_Rx" SG_ 997 PersIndexCcm_D_Actl 1;
BA_ "U_V710_MY2023_Rx" SG_ 997 PersIndexCcm_D_Actl 1;
BA_ "U_P702_MY2024_Rx" SG_ 997 PersIndexCcm_D_Actl 1;
BA_ "U_V713N_MY2022_Rx" SG_ 997 FeatNoCcmActl 1;
BA_ "U_V713AV_MY2022_Rx" SG_ 997 FeatNoCcmActl 1;
BA_ "U_P708_MY2023_Rx" SG_ 997 FeatNoCcmActl 1;
BA_ "U_V710_MY2023_Rx" SG_ 997 FeatNoCcmActl 1;
BA_ "U_P702_MY2024_Rx" SG_ 997 FeatNoCcmActl 1;
BA_ "U_V713N_MY2022_Rx" SG_ 997 FeatConfigCcmActl 1;
BA_ "U_V713AV_MY2022_Rx" SG_ 997 FeatConfigCcmActl 1;
BA_ "U_P708_MY2023_Rx" SG_ 997 FeatConfigCcmActl 1;
BA_ "U_V710_MY2023_Rx" SG_ 997 FeatConfigCcmActl 1;
BA_ "U_P702_MY2024_Rx" SG_ 997 FeatConfigCcmActl 1;
BA_ "GenSigSendType" SG_ 487 Aioc_SetExtSrcOutpMd_Rq 3;
BA_ "U_V713N_MY2022_Tx" SG_ 487 Aioc_SetExtSrcOutpMd_Rq 1;
BA_ "U_V713AV_MY2022_Tx" SG_ 487 Aioc_SetExtSrcOutpMd_Rq 1;
BA_ "U_P708_MY2023_Tx" SG_ 487 Aioc_SetExtSrcOutpMd_Rq 1;
BA_ "GenSigSendType" SG_ 464 SdarsSampleRate_D_Rq 3;
BA_ "U_P708_MY2023_Rx" SG_ 464 SdarsSampleRate_D_Rq 1;
BA_ "U_V713N_MY2022_Tx" SG_ 464 SdarsSampleRate_D_Rq 1;
BA_ "U_V713AV_MY2022_Tx" SG_ 464 SdarsSampleRate_D_Rq 1;
BA_ "U_P708_MY2023_Tx" SG_ 464 SdarsSampleRate_D_Rq 1;
BA_ "U_V710_MY2023_Tx" SG_ 464 SdarsSampleRate_D_Rq 1;
BA_ "GenSigStartValue" SG_ 464 SDARS_DirectChannel_Rq 1023;
BA_ "U_P708_MY2023_Rx" SG_ 464 SDARS_DirectChannel_Rq 1;
BA_ "U_V713N_MY2022_Tx" SG_ 464 SDARS_DirectChannel_Rq 1;
BA_ "U_V713AV_MY2022_Tx" SG_ 464 SDARS_DirectChannel_Rq 1;
BA_ "U_P708_MY2023_Tx" SG_ 464 SDARS_DirectChannel_Rq 1;
BA_ "U_V710_MY2023_Tx" SG_ 464 SDARS_DirectChannel_Rq 1;
BA_ "U_V710_MY2023_Rx" SG_ 864 MdeMnu_Buttn_Stat 1;
BA_ "U_P708_MY2023_Rx" SG_ 864 MdeMnu_Buttn_Stat 1;
BA_ "U_P702_MY2024_Rx" SG_ 864 MdeMnu_Buttn_Stat 1;
BA_ "U_V710_MY2023_Rx" SG_ 864 Front_AUTO_Blwr_Lvl 1;
BA_ "U_P708_MY2023_Rx" SG_ 864 Front_AUTO_Blwr_Lvl 1;
BA_ "U_P702_MY2024_Rx" SG_ 864 Front_AUTO_Blwr_Lvl 1;
BA_ "U_V710_MY2023_Rx" SG_ 864 RearMnu_Buttn_Stat 1;
BA_ "U_P708_MY2023_Rx" SG_ 864 RearMnu_Buttn_Stat 1;
BA_ "U_P702_MY2024_Rx" SG_ 864 RearMnu_Buttn_Stat 1;
BA_ "U_V710_MY2023_Rx" SG_ 864 FrontMnu_Buttn_Stat 1;
BA_ "U_P708_MY2023_Rx" SG_ 864 FrontMnu_Buttn_Stat 1;
BA_ "U_P702_MY2024_Rx" SG_ 864 FrontMnu_Buttn_Stat 1;
BA_ "GenSigStartValue" SG_ 864 DrvrFcsdMde_Btn_Stt 2;
BA_ "U_V710_MY2023_Rx" SG_ 864 DrvrFcsdMde_Btn_Stt 1;
BA_ "U_P708_MY2023_Rx" SG_ 864 DrvrFcsdMde_Btn_Stt 1;
BA_ "U_P702_MY2024_Rx" SG_ 864 DrvrFcsdMde_Btn_Stt 1;
BA_ "U_V713N_MY2022_Rx" SG_ 864 RHS_Cond_Seat_Status 1;
BA_ "U_V713AV_MY2022_Rx" SG_ 864 RHS_Cond_Seat_Status 1;
BA_ "U_V710_MY2023_Rx" SG_ 864 RHS_Cond_Seat_Status 1;
BA_ "U_P708_MY2023_Rx" SG_ 864 RHS_Cond_Seat_Status 1;
BA_ "U_P702_MY2024_Rx" SG_ 864 RHS_Cond_Seat_Status 1;
BA_ "U_V713N_MY2022_Rx" SG_ 864 LHS_Cond_Seat_Status 1;
BA_ "U_V713AV_MY2022_Rx" SG_ 864 LHS_Cond_Seat_Status 1;
BA_ "U_P708_MY2023_Rx" SG_ 864 LHS_Cond_Seat_Status 1;
BA_ "U_P702_MY2024_Rx" SG_ 864 LHS_Cond_Seat_Status 1;
BA_ "U_V710_MY2023_Rx" SG_ 864 LHS_Cond_Seat_Status 1;
BA_ "GenSigStartValue" SG_ 864 Htd_Strg_Whl_Status 2;
BA_ "U_V713N_MY2022_Rx" SG_ 864 Htd_Strg_Whl_Status 1;
BA_ "U_V713AV_MY2022_Rx" SG_ 864 Htd_Strg_Whl_Status 1;
BA_ "U_P708_MY2023_Rx" SG_ 864 Htd_Strg_Whl_Status 1;
BA_ "U_P702_MY2024_Rx" SG_ 864 Htd_Strg_Whl_Status 1;
BA_ "U_V710_MY2023_Rx" SG_ 864 Htd_Strg_Whl_Status 1;
BA_ "GenSigStartValue" SG_ 864 Htd_Strg_Whl_Btn_Stt 2;
BA_ "U_V713N_MY2022_Rx" SG_ 864 Htd_Strg_Whl_Btn_Stt 1;
BA_ "U_V713AV_MY2022_Rx" SG_ 864 Htd_Strg_Whl_Btn_Stt 1;
BA_ "U_V710_MY2023_Rx" SG_ 864 Htd_Strg_Whl_Btn_Stt 1;
BA_ "U_P708_MY2023_Rx" SG_ 864 Htd_Strg_Whl_Btn_Stt 1;
BA_ "U_P702_MY2024_Rx" SG_ 864 Htd_Strg_Whl_Btn_Stt 1;
BA_ "GenSigStartValue" SG_ 864 Defrost_Btn_Stt 2;
BA_ "U_V713N_MY2022_Rx" SG_ 864 Defrost_Btn_Stt 1;
BA_ "U_V713AV_MY2022_Rx" SG_ 864 Defrost_Btn_Stt 1;
BA_ "U_V710_MY2023_Rx" SG_ 864 Defrost_Btn_Stt 1;
BA_ "U_P708_MY2023_Rx" SG_ 864 Defrost_Btn_Stt 1;
BA_ "U_P702_MY2024_Rx" SG_ 864 Defrost_Btn_Stt 1;
BA_ "U_P708_MY2023_Rx" SG_ 864 CC_Fr_Btn_User_Adj 1;
BA_ "U_P702_MY2024_Rx" SG_ 864 CC_Fr_Btn_User_Adj 1;
BA_ "U_V710_MY2023_Rx" SG_ 864 CC_Fr_Btn_User_Adj 1;
BA_ "GenSigStartValue" SG_ 864 RHS_Htd_Seat_Btn_Stt 2;
BA_ "U_V713N_MY2022_Rx" SG_ 864 RHS_Htd_Seat_Btn_Stt 1;
BA_ "U_V713AV_MY2022_Rx" SG_ 864 RHS_Htd_Seat_Btn_Stt 1;
BA_ "U_V710_MY2023_Rx" SG_ 864 RHS_Htd_Seat_Btn_Stt 1;
BA_ "U_P702_MY2024_Rx" SG_ 864 RHS_Htd_Seat_Btn_Stt 1;
BA_ "GenSigStartValue" SG_ 864 RHS_Cld_Seat_Btn_Stt 2;
BA_ "U_V713N_MY2022_Rx" SG_ 864 RHS_Cld_Seat_Btn_Stt 1;
BA_ "U_V713AV_MY2022_Rx" SG_ 864 RHS_Cld_Seat_Btn_Stt 1;
BA_ "U_V710_MY2023_Rx" SG_ 864 RHS_Cld_Seat_Btn_Stt 1;
BA_ "U_P708_MY2023_Rx" SG_ 864 RHS_Cld_Seat_Btn_Stt 1;
BA_ "U_P702_MY2024_Rx" SG_ 864 RHS_Cld_Seat_Btn_Stt 1;
BA_ "GenSigStartValue" SG_ 864 Outside_Btn_Stt 2;
BA_ "U_V713N_MY2022_Rx" SG_ 864 Outside_Btn_Stt 1;
BA_ "U_V713AV_MY2022_Rx" SG_ 864 Outside_Btn_Stt 1;
BA_ "GenSigStartValue" SG_ 864 LHS_Htd_Seat_Btn_Stt 2;
BA_ "U_V713N_MY2022_Rx" SG_ 864 LHS_Htd_Seat_Btn_Stt 1;
BA_ "U_V713AV_MY2022_Rx" SG_ 864 LHS_Htd_Seat_Btn_Stt 1;
BA_ "U_V710_MY2023_Rx" SG_ 864 LHS_Htd_Seat_Btn_Stt 1;
BA_ "U_P708_MY2023_Rx" SG_ 864 LHS_Htd_Seat_Btn_Stt 1;
BA_ "U_P702_MY2024_Rx" SG_ 864 LHS_Htd_Seat_Btn_Stt 1;
BA_ "GenSigStartValue" SG_ 864 LHS_Cld_Seat_Btn_Stt 2;
BA_ "U_V713N_MY2022_Rx" SG_ 864 LHS_Cld_Seat_Btn_Stt 1;
BA_ "U_V713AV_MY2022_Rx" SG_ 864 LHS_Cld_Seat_Btn_Stt 1;
BA_ "U_V710_MY2023_Rx" SG_ 864 LHS_Cld_Seat_Btn_Stt 1;
BA_ "U_P708_MY2023_Rx" SG_ 864 LHS_Cld_Seat_Btn_Stt 1;
BA_ "U_P702_MY2024_Rx" SG_ 864 LHS_Cld_Seat_Btn_Stt 1;
BA_ "GenSigStartValue" SG_ 864 Htd_Frt_Wsh_Btn_Stt 2;
BA_ "U_V713N_MY2022_Rx" SG_ 864 Htd_Frt_Wsh_Btn_Stt 1;
BA_ "U_V713AV_MY2022_Rx" SG_ 864 Htd_Frt_Wsh_Btn_Stt 1;
BA_ "U_P708_MY2023_Rx" SG_ 864 Htd_Frt_Wsh_Btn_Stt 1;
BA_ "U_P702_MY2024_Rx" SG_ 864 Htd_Frt_Wsh_Btn_Stt 1;
BA_ "U_V710_MY2023_Rx" SG_ 864 Htd_Frt_Wsh_Btn_Stt 1;
BA_ "GenSigStartValue" SG_ 864 Auto_Recirc_Btn_Stt 2;
BA_ "U_V713N_MY2022_Rx" SG_ 864 Auto_Recirc_Btn_Stt 1;
BA_ "U_V713AV_MY2022_Rx" SG_ 864 Auto_Recirc_Btn_Stt 1;
BA_ "GenSigStartValue" SG_ 864 Recirc_Btn_Stt 2;
BA_ "U_V713N_MY2022_Rx" SG_ 864 Recirc_Btn_Stt 1;
BA_ "U_V713AV_MY2022_Rx" SG_ 864 Recirc_Btn_Stt 1;
BA_ "U_P708_MY2023_Rx" SG_ 864 Recirc_Btn_Stt 1;
BA_ "U_P702_MY2024_Rx" SG_ 864 Recirc_Btn_Stt 1;
BA_ "U_V710_MY2023_Rx" SG_ 864 Recirc_Btn_Stt 1;
BA_ "GenSigStartValue" SG_ 864 Rear_Defrost_Btn_Stt 2;
BA_ "U_V713N_MY2022_Rx" SG_ 864 Rear_Defrost_Btn_Stt 1;
BA_ "U_V713AV_MY2022_Rx" SG_ 864 Rear_Defrost_Btn_Stt 1;
BA_ "U_P708_MY2023_Rx" SG_ 864 Rear_Defrost_Btn_Stt 1;
BA_ "U_P702_MY2024_Rx" SG_ 864 Rear_Defrost_Btn_Stt 1;
BA_ "U_V710_MY2023_Rx" SG_ 864 Rear_Defrost_Btn_Stt 1;
BA_ "GenSigStartValue" SG_ 864 My_Temp_Btn_Stt 2;
BA_ "U_V713N_MY2022_Rx" SG_ 864 My_Temp_Btn_Stt 1;
BA_ "U_V713AV_MY2022_Rx" SG_ 864 My_Temp_Btn_Stt 1;
BA_ "U_P708_MY2023_Rx" SG_ 864 My_Temp_Btn_Stt 1;
BA_ "U_P702_MY2024_Rx" SG_ 864 My_Temp_Btn_Stt 1;
BA_ "U_V710_MY2023_Rx" SG_ 864 My_Temp_Btn_Stt 1;
BA_ "GenSigStartValue" SG_ 864 Max_Defrost_Btn_Stt 2;
BA_ "U_V713N_MY2022_Rx" SG_ 864 Max_Defrost_Btn_Stt 1;
BA_ "U_V713AV_MY2022_Rx" SG_ 864 Max_Defrost_Btn_Stt 1;
BA_ "U_P708_MY2023_Rx" SG_ 864 Max_Defrost_Btn_Stt 1;
BA_ "U_P702_MY2024_Rx" SG_ 864 Max_Defrost_Btn_Stt 1;
BA_ "U_V710_MY2023_Rx" SG_ 864 Max_Defrost_Btn_Stt 1;
BA_ "GenSigStartValue" SG_ 864 Max_AC_Btn_Stt 2;
BA_ "U_V713N_MY2022_Rx" SG_ 864 Max_AC_Btn_Stt 1;
BA_ "U_V713AV_MY2022_Rx" SG_ 864 Max_AC_Btn_Stt 1;
BA_ "U_P708_MY2023_Rx" SG_ 864 Max_AC_Btn_Stt 1;
BA_ "U_P702_MY2024_Rx" SG_ 864 Max_AC_Btn_Stt 1;
BA_ "U_V710_MY2023_Rx" SG_ 864 Max_AC_Btn_Stt 1;
BA_ "GenSigStartValue" SG_ 864 Front_AUTO_Label 2;
BA_ "U_V713N_MY2022_Rx" SG_ 864 Front_AUTO_Label 1;
BA_ "U_V713AV_MY2022_Rx" SG_ 864 Front_AUTO_Label 1;
BA_ "U_P708_MY2023_Rx" SG_ 864 Front_AUTO_Label 1;
BA_ "U_P702_MY2024_Rx" SG_ 864 Front_AUTO_Label 1;
BA_ "U_V710_MY2023_Rx" SG_ 864 Front_AUTO_Label 1;
BA_ "GenSigStartValue" SG_ 864 Windscreen_Btn_Stt 2;
BA_ "U_V713N_MY2022_Rx" SG_ 864 Windscreen_Btn_Stt 1;
BA_ "U_V713AV_MY2022_Rx" SG_ 864 Windscreen_Btn_Stt 1;
BA_ "U_V710_MY2023_Rx" SG_ 864 Windscreen_Btn_Stt 1;
BA_ "U_P708_MY2023_Rx" SG_ 864 Windscreen_Btn_Stt 1;
BA_ "U_P702_MY2024_Rx" SG_ 864 Windscreen_Btn_Stt 1;
BA_ "GenSigStartValue" SG_ 864 Panel_Btn_Stt 2;
BA_ "U_V713N_MY2022_Rx" SG_ 864 Panel_Btn_Stt 1;
BA_ "U_V713AV_MY2022_Rx" SG_ 864 Panel_Btn_Stt 1;
BA_ "U_P708_MY2023_Rx" SG_ 864 Panel_Btn_Stt 1;
BA_ "U_P702_MY2024_Rx" SG_ 864 Panel_Btn_Stt 1;
BA_ "U_V710_MY2023_Rx" SG_ 864 Panel_Btn_Stt 1;
BA_ "GenSigStartValue" SG_ 864 Front_Power_Btn_Stt 2;
BA_ "U_V713N_MY2022_Rx" SG_ 864 Front_Power_Btn_Stt 1;
BA_ "U_V713AV_MY2022_Rx" SG_ 864 Front_Power_Btn_Stt 1;
BA_ "U_P708_MY2023_Rx" SG_ 864 Front_Power_Btn_Stt 1;
BA_ "U_P702_MY2024_Rx" SG_ 864 Front_Power_Btn_Stt 1;
BA_ "U_V710_MY2023_Rx" SG_ 864 Front_Power_Btn_Stt 1;
BA_ "GenSigStartValue" SG_ 864 Front_AUTO_Btn_Stt 2;
BA_ "U_V713N_MY2022_Rx" SG_ 864 Front_AUTO_Btn_Stt 1;
BA_ "U_V713AV_MY2022_Rx" SG_ 864 Front_AUTO_Btn_Stt 1;
BA_ "U_P708_MY2023_Rx" SG_ 864 Front_AUTO_Btn_Stt 1;
BA_ "U_P702_MY2024_Rx" SG_ 864 Front_AUTO_Btn_Stt 1;
BA_ "U_V710_MY2023_Rx" SG_ 864 Front_AUTO_Btn_Stt 1;
BA_ "GenSigStartValue" SG_ 864 Floor_Btn_Stt 2;
BA_ "U_V713N_MY2022_Rx" SG_ 864 Floor_Btn_Stt 1;
BA_ "U_V713AV_MY2022_Rx" SG_ 864 Floor_Btn_Stt 1;
BA_ "U_P708_MY2023_Rx" SG_ 864 Floor_Btn_Stt 1;
BA_ "U_P702_MY2024_Rx" SG_ 864 Floor_Btn_Stt 1;
BA_ "U_V710_MY2023_Rx" SG_ 864 Floor_Btn_Stt 1;
BA_ "GenSigStartValue" SG_ 864 Dual_Button_Stt 2;
BA_ "U_V713N_MY2022_Rx" SG_ 864 Dual_Button_Stt 1;
BA_ "U_V713AV_MY2022_Rx" SG_ 864 Dual_Button_Stt 1;
BA_ "U_P708_MY2023_Rx" SG_ 864 Dual_Button_Stt 1;
BA_ "U_P702_MY2024_Rx" SG_ 864 Dual_Button_Stt 1;
BA_ "U_V710_MY2023_Rx" SG_ 864 Dual_Button_Stt 1;
BA_ "GenSigStartValue" SG_ 864 AC_Btn_Stt 2;
BA_ "U_V713N_MY2022_Rx" SG_ 864 AC_Btn_Stt 1;
BA_ "U_V713AV_MY2022_Rx" SG_ 864 AC_Btn_Stt 1;
BA_ "U_P708_MY2023_Rx" SG_ 864 AC_Btn_Stt 1;
BA_ "U_P702_MY2024_Rx" SG_ 864 AC_Btn_Stt 1;
BA_ "U_V710_MY2023_Rx" SG_ 864 AC_Btn_Stt 1;
BA_ "GenSigSendType" SG_ 994 PersCtaSplitView_D_Rq 3;
BA_ "U_V710_MY2023_Tx" SG_ 994 PersCtaSplitView_D_Rq 1;
BA_ "U_P708_MY2023_Tx" SG_ 994 PersCtaSplitView_D_Rq 1;
BA_ "U_P702_MY2024_Tx" SG_ 994 PersCtaSplitView_D_Rq 1;
BA_ "WakeupSignal" SG_ 994 Pers4OptIn_B_Stats 1;
BA_ "GenSigSendType" SG_ 994 Pers4OptIn_B_Stats 3;
BA_ "U_V710_MY2023_Tx" SG_ 994 Pers4OptIn_B_Stats 1;
BA_ "U_P708_MY2023_Tx" SG_ 994 Pers4OptIn_B_Stats 1;
BA_ "U_P702_MY2024_Tx" SG_ 994 Pers4OptIn_B_Stats 1;
BA_ "WakeupSignal" SG_ 994 Pers3OptIn_B_Stats 1;
BA_ "GenSigSendType" SG_ 994 Pers3OptIn_B_Stats 3;
BA_ "U_V710_MY2023_Tx" SG_ 994 Pers3OptIn_B_Stats 1;
BA_ "U_P708_MY2023_Tx" SG_ 994 Pers3OptIn_B_Stats 1;
BA_ "U_P702_MY2024_Tx" SG_ 994 Pers3OptIn_B_Stats 1;
BA_ "WakeupSignal" SG_ 994 Pers2OptIn_B_Stats 1;
BA_ "GenSigSendType" SG_ 994 Pers2OptIn_B_Stats 3;
BA_ "U_V710_MY2023_Tx" SG_ 994 Pers2OptIn_B_Stats 1;
BA_ "U_P708_MY2023_Tx" SG_ 994 Pers2OptIn_B_Stats 1;
BA_ "U_P702_MY2024_Tx" SG_ 994 Pers2OptIn_B_Stats 1;
BA_ "WakeupSignal" SG_ 994 Pers1OptIn_B_Stats 1;
BA_ "GenSigSendType" SG_ 994 Pers1OptIn_B_Stats 3;
BA_ "U_V710_MY2023_Tx" SG_ 994 Pers1OptIn_B_Stats 1;
BA_ "U_P708_MY2023_Tx" SG_ 994 Pers1OptIn_B_Stats 1;
BA_ "U_P702_MY2024_Tx" SG_ 994 Pers1OptIn_B_Stats 1;
BA_ "GenSigStartValue" SG_ 994 CtrStkPersIndex_D_Actl 4;
BA_ "GenSigSendType" SG_ 994 CtrStkPersIndex_D_Actl 3;
BA_ "U_V713N_MY2022_Rx" SG_ 994 CtrStkPersIndex_D_Actl 1;
BA_ "U_V713AV_MY2022_Rx" SG_ 994 CtrStkPersIndex_D_Actl 1;
BA_ "U_P708_MY2023_Rx" SG_ 994 CtrStkPersIndex_D_Actl 1;
BA_ "U_V710_MY2023_Rx" SG_ 994 CtrStkPersIndex_D_Actl 1;
BA_ "U_CDX74X_MY2024_Rx" SG_ 994 CtrStkPersIndex_D_Actl 1;
BA_ "U_V710_MY2023_Tx" SG_ 994 CtrStkPersIndex_D_Actl 1;
BA_ "U_P708_MY2023_Tx" SG_ 994 CtrStkPersIndex_D_Actl 1;
BA_ "U_P702_MY2024_Tx" SG_ 994 CtrStkPersIndex_D_Actl 1;
BA_ "GenSigSendType" SG_ 994 CtrStkFeatNoActl 3;
BA_ "U_V713N_MY2022_Rx" SG_ 994 CtrStkFeatNoActl 1;
BA_ "U_V713AV_MY2022_Rx" SG_ 994 CtrStkFeatNoActl 1;
BA_ "U_P708_MY2023_Rx" SG_ 994 CtrStkFeatNoActl 1;
BA_ "U_V710_MY2023_Rx" SG_ 994 CtrStkFeatNoActl 1;
BA_ "U_V710_MY2023_Tx" SG_ 994 CtrStkFeatNoActl 1;
BA_ "U_P708_MY2023_Tx" SG_ 994 CtrStkFeatNoActl 1;
BA_ "U_P702_MY2024_Tx" SG_ 994 CtrStkFeatNoActl 1;
BA_ "GenSigSendType" SG_ 994 CtrStkFeatConfigActl 3;
BA_ "U_V713N_MY2022_Rx" SG_ 994 CtrStkFeatConfigActl 1;
BA_ "U_V713AV_MY2022_Rx" SG_ 994 CtrStkFeatConfigActl 1;
BA_ "U_P708_MY2023_Rx" SG_ 994 CtrStkFeatConfigActl 1;
BA_ "U_V710_MY2023_Rx" SG_ 994 CtrStkFeatConfigActl 1;
BA_ "U_V710_MY2023_Tx" SG_ 994 CtrStkFeatConfigActl 1;
BA_ "U_P708_MY2023_Tx" SG_ 994 CtrStkFeatConfigActl 1;
BA_ "U_P702_MY2024_Tx" SG_ 994 CtrStkFeatConfigActl 1;
BA_ "GenSigSendType" SG_ 994 PersStore_D_Rq 3;
BA_ "U_V710_MY2023_Tx" SG_ 994 PersStore_D_Rq 1;
BA_ "U_P708_MY2023_Tx" SG_ 994 PersStore_D_Rq 1;
BA_ "U_P702_MY2024_Tx" SG_ 994 PersStore_D_Rq 1;
BA_ "GenSigSendType" SG_ 994 CtrStkDsplyOp_D_Rq 3;
BA_ "U_V713N_MY2022_Rx" SG_ 994 CtrStkDsplyOp_D_Rq 1;
BA_ "U_V713AV_MY2022_Rx" SG_ 994 CtrStkDsplyOp_D_Rq 1;
BA_ "U_P708_MY2023_Rx" SG_ 994 CtrStkDsplyOp_D_Rq 1;
BA_ "U_V710_MY2023_Rx" SG_ 994 CtrStkDsplyOp_D_Rq 1;
BA_ "U_CDX74X_MY2024_Rx" SG_ 994 CtrStkDsplyOp_D_Rq 1;
BA_ "U_V710_MY2023_Tx" SG_ 994 CtrStkDsplyOp_D_Rq 1;
BA_ "U_P708_MY2023_Tx" SG_ 994 CtrStkDsplyOp_D_Rq 1;
BA_ "U_P702_MY2024_Tx" SG_ 994 CtrStkDsplyOp_D_Rq 1;
BA_ "GenSigSendType" SG_ 1822 TesterPhysicalResGWM_H3 3;
BA_ "ECGUsedTxSignal" SG_ 1822 TesterPhysicalResGWM_H3 1;
BA_ "U_V713N_MY2022_Tx" SG_ 1822 TesterPhysicalResGWM_H3 1;
BA_ "U_V713AV_MY2022_Tx" SG_ 1822 TesterPhysicalResGWM_H3 1;
BA_ "U_P708_MY2023_Tx" SG_ 1822 TesterPhysicalResGWM_H3 1;
BA_ "U_CDX74X_MY2024_Tx" SG_ 1822 TesterPhysicalResGWM_H3 1;
BA_ "U_V710_MY2023_Tx" SG_ 1822 TesterPhysicalResGWM_H3 1;
BA_ "U_V713AV_MY2022_Rx" SG_ 394 AccStopStat_D_Dsply 1;
BA_ "U_P708_MY2023_Rx" SG_ 394 AccStopStat_D_Dsply 1;
BA_ "U_V710_MY2023_Rx" SG_ 394 AccStopStat_D_Dsply 1;
BA_ "U_V713N_MY2022_Rx" SG_ 394 AccStopStat_D_Dsply 1;
BA_ "U_P702_MY2024_Rx" SG_ 394 AccStopStat_D_Dsply 1;
BA_ "U_V713N_MY2022_Rx" SG_ 394 AccTrgDist2_D_Dsply 1;
BA_ "U_V713AV_MY2022_Rx" SG_ 394 AccTrgDist2_D_Dsply 1;
BA_ "U_P708_MY2023_Rx" SG_ 394 AccTrgDist2_D_Dsply 1;
BA_ "U_P702_MY2024_Rx" SG_ 394 AccTrgDist2_D_Dsply 1;
BA_ "U_V710_MY2023_Rx" SG_ 394 AccTrgDist2_D_Dsply 1;
BA_ "U_V713N_MY2022_Rx" SG_ 394 AccStopRes_B_Dsply 1;
BA_ "U_V713AV_MY2022_Rx" SG_ 394 AccStopRes_B_Dsply 1;
BA_ "U_P708_MY2023_Rx" SG_ 394 AccStopRes_B_Dsply 1;
BA_ "U_P702_MY2024_Rx" SG_ 394 AccStopRes_B_Dsply 1;
BA_ "U_V710_MY2023_Rx" SG_ 394 AccStopRes_B_Dsply 1;
BA_ "U_P708_MY2023_Rx" SG_ 394 TjaWarn_D_Rq 1;
BA_ "U_P702_MY2024_Rx" SG_ 394 TjaWarn_D_Rq 1;
BA_ "U_V713N_MY2022_Rx" SG_ 394 TjaWarn_D_Rq 1;
BA_ "U_V713AV_MY2022_Rx" SG_ 394 TjaWarn_D_Rq 1;
BA_ "U_V710_MY2023_Rx" SG_ 394 TjaWarn_D_Rq 1;
BA_ "U_P708_MY2023_Rx" SG_ 394 Tja_D_Stat 1;
BA_ "U_P702_MY2024_Rx" SG_ 394 Tja_D_Stat 1;
BA_ "U_V713N_MY2022_Rx" SG_ 394 Tja_D_Stat 1;
BA_ "U_V713AV_MY2022_Rx" SG_ 394 Tja_D_Stat 1;
BA_ "U_V710_MY2023_Rx" SG_ 394 Tja_D_Stat 1;
BA_ "U_V713N_MY2022_Rx" SG_ 394 IaccLamp_D_Rq 1;
BA_ "U_V713AV_MY2022_Rx" SG_ 394 IaccLamp_D_Rq 1;
BA_ "U_P708_MY2023_Rx" SG_ 394 IaccLamp_D_Rq 1;
BA_ "U_V710_MY2023_Rx" SG_ 394 IaccLamp_D_Rq 1;
BA_ "U_P702_MY2024_Rx" SG_ 394 IaccLamp_D_Rq 1;
BA_ "U_V713N_MY2022_Rx" SG_ 394 AccMsgTxt_D2_Rq 1;
BA_ "U_V713AV_MY2022_Rx" SG_ 394 AccMsgTxt_D2_Rq 1;
BA_ "U_P708_MY2023_Rx" SG_ 394 AccMsgTxt_D2_Rq 1;
BA_ "U_P702_MY2024_Rx" SG_ 394 AccMsgTxt_D2_Rq 1;
BA_ "U_V710_MY2023_Rx" SG_ 394 AccMsgTxt_D2_Rq 1;
BA_ "U_P708_MY2023_Rx" SG_ 394 TjaMsgTxt_D_Dsply 1;
BA_ "U_P702_MY2024_Rx" SG_ 394 TjaMsgTxt_D_Dsply 1;
BA_ "U_V713N_MY2022_Rx" SG_ 394 TjaMsgTxt_D_Dsply 1;
BA_ "U_V713AV_MY2022_Rx" SG_ 394 TjaMsgTxt_D_Dsply 1;
BA_ "U_V710_MY2023_Rx" SG_ 394 TjaMsgTxt_D_Dsply 1;
BA_ "MetaData" SG_ 394 HaDsply_No_Cnt 1;
BA_ "U_V713AV_MY2022_Rx" SG_ 394 HaDsply_No_Cnt 1;
BA_ "U_P708_MY2023_Rx" SG_ 394 HaDsply_No_Cnt 1;
BA_ "U_V710_MY2023_Rx" SG_ 394 HaDsply_No_Cnt 1;
BA_ "U_P702_MY2024_Rx" SG_ 394 HaDsply_No_Cnt 1;
BA_ "U_V713N_MY2022_Rx" SG_ 394 FcwDeny_B_Dsply 1;
BA_ "U_V713AV_MY2022_Rx" SG_ 394 FcwDeny_B_Dsply 1;
BA_ "U_P708_MY2023_Rx" SG_ 394 FcwDeny_B_Dsply 1;
BA_ "U_V710_MY2023_Rx" SG_ 394 FcwDeny_B_Dsply 1;
BA_ "U_P702_MY2024_Rx" SG_ 394 FcwDeny_B_Dsply 1;
BA_ "U_V713N_MY2022_Rx" SG_ 394 FcwMemStat_B_Actl 1;
BA_ "U_V713AV_MY2022_Rx" SG_ 394 FcwMemStat_B_Actl 1;
BA_ "U_P708_MY2023_Rx" SG_ 394 FcwMemStat_B_Actl 1;
BA_ "U_V710_MY2023_Rx" SG_ 394 FcwMemStat_B_Actl 1;
BA_ "U_P702_MY2024_Rx" SG_ 394 FcwMemStat_B_Actl 1;
BA_ "U_V713N_MY2022_Rx" SG_ 394 AccTGap_B_Dsply 1;
BA_ "U_V713AV_MY2022_Rx" SG_ 394 AccTGap_B_Dsply 1;
BA_ "U_P708_MY2023_Rx" SG_ 394 AccTGap_B_Dsply 1;
BA_ "U_P702_MY2024_Rx" SG_ 394 AccTGap_B_Dsply 1;
BA_ "U_V710_MY2023_Rx" SG_ 394 AccTGap_B_Dsply 1;
BA_ "U_V713N_MY2022_Rx" SG_ 394 CadsAlignIncplt_B_Actl 1;
BA_ "U_V713AV_MY2022_Rx" SG_ 394 CadsAlignIncplt_B_Actl 1;
BA_ "U_P708_MY2023_Rx" SG_ 394 CadsAlignIncplt_B_Actl 1;
BA_ "U_V710_MY2023_Rx" SG_ 394 CadsAlignIncplt_B_Actl 1;
BA_ "U_P702_MY2024_Rx" SG_ 394 CadsAlignIncplt_B_Actl 1;
BA_ "U_V713N_MY2022_Rx" SG_ 394 AccFllwMde_B_Dsply 1;
BA_ "U_V713AV_MY2022_Rx" SG_ 394 AccFllwMde_B_Dsply 1;
BA_ "U_P708_MY2023_Rx" SG_ 394 AccFllwMde_B_Dsply 1;
BA_ "U_P702_MY2024_Rx" SG_ 394 AccFllwMde_B_Dsply 1;
BA_ "U_V710_MY2023_Rx" SG_ 394 AccFllwMde_B_Dsply 1;
BA_ "U_V713N_MY2022_Rx" SG_ 394 CadsRadrBlck_B_Actl 1;
BA_ "U_V713AV_MY2022_Rx" SG_ 394 CadsRadrBlck_B_Actl 1;
BA_ "U_P708_MY2023_Rx" SG_ 394 CadsRadrBlck_B_Actl 1;
BA_ "U_V710_MY2023_Rx" SG_ 394 CadsRadrBlck_B_Actl 1;
BA_ "U_P702_MY2024_Rx" SG_ 394 CadsRadrBlck_B_Actl 1;
BA_ "U_V713N_MY2022_Rx" SG_ 394 CmbbPostEvnt_B_Dsply 1;
BA_ "U_V713AV_MY2022_Rx" SG_ 394 CmbbPostEvnt_B_Dsply 1;
BA_ "U_P708_MY2023_Rx" SG_ 394 CmbbPostEvnt_B_Dsply 1;
BA_ "U_V710_MY2023_Rx" SG_ 394 CmbbPostEvnt_B_Dsply 1;
BA_ "U_P702_MY2024_Rx" SG_ 394 CmbbPostEvnt_B_Dsply 1;
BA_ "U_V713N_MY2022_Rx" SG_ 394 AccStopMde_B_Dsply 1;
BA_ "U_V713AV_MY2022_Rx" SG_ 394 AccStopMde_B_Dsply 1;
BA_ "U_P708_MY2023_Rx" SG_ 394 AccStopMde_B_Dsply 1;
BA_ "U_P702_MY2024_Rx" SG_ 394 AccStopMde_B_Dsply 1;
BA_ "U_V710_MY2023_Rx" SG_ 394 AccStopMde_B_Dsply 1;
BA_ "U_V713N_MY2022_Rx" SG_ 394 FcwMemSens_D_Actl 1;
BA_ "U_V713AV_MY2022_Rx" SG_ 394 FcwMemSens_D_Actl 1;
BA_ "U_P708_MY2023_Rx" SG_ 394 FcwMemSens_D_Actl 1;
BA_ "U_V710_MY2023_Rx" SG_ 394 FcwMemSens_D_Actl 1;
BA_ "U_P702_MY2024_Rx" SG_ 394 FcwMemSens_D_Actl 1;
BA_ "U_V713N_MY2022_Rx" SG_ 394 FcwMsgTxt_D_Rq 1;
BA_ "U_V713AV_MY2022_Rx" SG_ 394 FcwMsgTxt_D_Rq 1;
BA_ "U_P708_MY2023_Rx" SG_ 394 FcwMsgTxt_D_Rq 1;
BA_ "U_V710_MY2023_Rx" SG_ 394 FcwMsgTxt_D_Rq 1;
BA_ "U_P702_MY2024_Rx" SG_ 394 FcwMsgTxt_D_Rq 1;
BA_ "GenSigStartValue" SG_ 394 AccTGap_D_Dsply 3;
BA_ "U_V713N_MY2022_Rx" SG_ 394 AccTGap_D_Dsply 1;
BA_ "U_V713AV_MY2022_Rx" SG_ 394 AccTGap_D_Dsply 1;
BA_ "U_P708_MY2023_Rx" SG_ 394 AccTGap_D_Dsply 1;
BA_ "U_P702_MY2024_Rx" SG_ 394 AccTGap_D_Dsply 1;
BA_ "U_V710_MY2023_Rx" SG_ 394 AccTGap_D_Dsply 1;
BA_ "GenSigStartValue" SG_ 394 AccMemEnbl_B_RqDrv 1;
BA_ "U_V713N_MY2022_Rx" SG_ 394 AccMemEnbl_B_RqDrv 1;
BA_ "U_V713AV_MY2022_Rx" SG_ 394 AccMemEnbl_B_RqDrv 1;
BA_ "U_P708_MY2023_Rx" SG_ 394 AccMemEnbl_B_RqDrv 1;
BA_ "U_V710_MY2023_Rx" SG_ 394 AccMemEnbl_B_RqDrv 1;
BA_ "U_P702_MY2024_Rx" SG_ 394 AccMemEnbl_B_RqDrv 1;
BA_ "MetaData" SG_ 394 HaDsply_No_Cs 1;
BA_ "U_V713AV_MY2022_Rx" SG_ 394 HaDsply_No_Cs 1;
BA_ "U_P708_MY2023_Rx" SG_ 394 HaDsply_No_Cs 1;
BA_ "U_V710_MY2023_Rx" SG_ 394 HaDsply_No_Cs 1;
BA_ "U_P702_MY2024_Rx" SG_ 394 HaDsply_No_Cs 1;
BA_ "U_V713N_MY2022_Rx" SG_ 394 AccWarn_D_Dsply 1;
BA_ "U_V713AV_MY2022_Rx" SG_ 394 AccWarn_D_Dsply 1;
BA_ "U_P708_MY2023_Rx" SG_ 394 AccWarn_D_Dsply 1;
BA_ "U_P702_MY2024_Rx" SG_ 394 AccWarn_D_Dsply 1;
BA_ "U_V710_MY2023_Rx" SG_ 394 AccWarn_D_Dsply 1;
BA_ "U_V713N_MY2022_Rx" SG_ 394 FcwVisblWarn_B_Rq 1;
BA_ "U_V713AV_MY2022_Rx" SG_ 394 FcwVisblWarn_B_Rq 1;
BA_ "U_P708_MY2023_Rx" SG_ 394 FcwVisblWarn_B_Rq 1;
BA_ "U_V710_MY2023_Rx" SG_ 394 FcwVisblWarn_B_Rq 1;
BA_ "U_P702_MY2024_Rx" SG_ 394 FcwVisblWarn_B_Rq 1;
BA_ "U_V713N_MY2022_Rx" SG_ 394 FcwAudioWarn_B_Rq 1;
BA_ "U_V713AV_MY2022_Rx" SG_ 394 FcwAudioWarn_B_Rq 1;
BA_ "U_P708_MY2023_Rx" SG_ 394 FcwAudioWarn_B_Rq 1;
BA_ "U_V710_MY2023_Rx" SG_ 394 FcwAudioWarn_B_Rq 1;
BA_ "U_P702_MY2024_Rx" SG_ 394 FcwAudioWarn_B_Rq 1;
BA_ "GenSigSendType" SG_ 1068 TrlrAidMsgTxt_D_Rq 3;
BA_ "U_V713N_MY2022_Rx" SG_ 1068 TrlrAidMsgTxt_D_Rq 1;
BA_ "U_V713AV_MY2022_Rx" SG_ 1068 TrlrAidMsgTxt_D_Rq 1;
BA_ "U_V710_MY2023_Rx" SG_ 1068 TrlrAidMsgTxt_D_Rq 1;
BA_ "U_P702_MY2024_Rx" SG_ 1068 TrlrAidMsgTxt_D_Rq 1;
BA_ "GenSigStartValue" SG_ 1019 PersIndexIpc_D_Actl 4;
BA_ "GenSigSendType" SG_ 1019 PersIndexIpc_D_Actl 3;
BA_ "U_P708_MY2023_Rx" SG_ 1019 PersIndexIpc_D_Actl 1;
BA_ "U_V713N_MY2022_Tx" SG_ 1019 PersIndexIpc_D_Actl 1;
BA_ "U_V713AV_MY2022_Tx" SG_ 1019 PersIndexIpc_D_Actl 1;
BA_ "U_P708_MY2023_Tx" SG_ 1019 PersIndexIpc_D_Actl 1;
BA_ "U_V710_MY2023_Tx" SG_ 1019 PersIndexIpc_D_Actl 1;
BA_ "U_P702_MY2024_Tx" SG_ 1019 PersIndexIpc_D_Actl 1;
BA_ "GenSigSendType" SG_ 1019 FeatNoIpcActl 3;
BA_ "U_P708_MY2023_Rx" SG_ 1019 FeatNoIpcActl 1;
BA_ "U_V713N_MY2022_Tx" SG_ 1019 FeatNoIpcActl 1;
BA_ "U_V713AV_MY2022_Tx" SG_ 1019 FeatNoIpcActl 1;
BA_ "U_P708_MY2023_Tx" SG_ 1019 FeatNoIpcActl 1;
BA_ "U_V710_MY2023_Tx" SG_ 1019 FeatNoIpcActl 1;
BA_ "U_P702_MY2024_Tx" SG_ 1019 FeatNoIpcActl 1;
BA_ "GenSigSendType" SG_ 1019 FeatConfigIpcActl 3;
BA_ "U_P708_MY2023_Rx" SG_ 1019 FeatConfigIpcActl 1;
BA_ "U_V713N_MY2022_Tx" SG_ 1019 FeatConfigIpcActl 1;
BA_ "U_V713AV_MY2022_Tx" SG_ 1019 FeatConfigIpcActl 1;
BA_ "U_P708_MY2023_Tx" SG_ 1019 FeatConfigIpcActl 1;
BA_ "U_V710_MY2023_Tx" SG_ 1019 FeatConfigIpcActl 1;
BA_ "U_P702_MY2024_Tx" SG_ 1019 FeatConfigIpcActl 1;
BA_ "WakeupSignal" SG_ 909 IgnPsswrdDsply_B_Rq 1;
BA_ "U_V713N_MY2022_Rx" SG_ 909 IgnPsswrdDsply_B_Rq 1;
BA_ "U_V713AV_MY2022_Rx" SG_ 909 IgnPsswrdDsply_B_Rq 1;
BA_ "U_V710_MY2023_Rx" SG_ 909 IgnPsswrdDsply_B_Rq 1;
BA_ "U_P708_MY2023_Rx" SG_ 909 IgnPsswrdDsply_B_Rq 1;
BA_ "U_P702_MY2024_Rx" SG_ 909 IgnPsswrdDsply_B_Rq 1;
BA_ "WakeupSignal" SG_ 909 ElPwPoint_D_Rq 1;
BA_ "U_V713N_MY2022_Rx" SG_ 909 PoliceIdlMde_D_Stat 1;
BA_ "U_V713AV_MY2022_Rx" SG_ 909 PoliceIdlMde_D_Stat 1;
BA_ "U_V710_MY2023_Rx" SG_ 909 PoliceIdlMde_D_Stat 1;
BA_ "U_P708_MY2023_Rx" SG_ 909 PoliceIdlMde_D_Stat 1;
BA_ "U_P702_MY2024_Rx" SG_ 909 PoliceIdlMde_D_Stat 1;
BA_ "U_V713N_MY2022_Rx" SG_ 909 DrLatchMsgTxt_D_Rq 1;
BA_ "U_V713AV_MY2022_Rx" SG_ 909 DrLatchMsgTxt_D_Rq 1;
BA_ "U_P708_MY2023_Rx" SG_ 909 DrLatchMsgTxt_D_Rq 1;
BA_ "U_V710_MY2023_Rx" SG_ 909 DrLatchMsgTxt_D_Rq 1;
BA_ "U_P702_MY2024_Rx" SG_ 909 DrLatchMsgTxt_D_Rq 1;
BA_ "GenSigStartValue" SG_ 909 WiprFront_D_Stat2 15;
BA_ "U_V710_MY2023_Rx" SG_ 909 WiprFront_D_Stat2 1;
BA_ "U_P708_MY2023_Rx" SG_ 909 WiprFront_D_Stat2 1;
BA_ "U_P702_MY2024_Rx" SG_ 909 WiprFront_D_Stat2 1;
BA_ "WakeupSignal" SG_ 909 HazrdLght_B_Stat 1;
BA_ "U_V710_MY2023_Rx" SG_ 909 HazrdLght_B_Stat 1;
BA_ "U_P708_MY2023_Rx" SG_ 909 HazrdLght_B_Stat 1;
BA_ "U_P702_MY2024_Rx" SG_ 909 HazrdLght_B_Stat 1;
BA_ "U_V713N_MY2022_Rx" SG_ 909 TurnLghtSwtch_D_Stat2 1;
BA_ "U_V713AV_MY2022_Rx" SG_ 909 TurnLghtSwtch_D_Stat2 1;
BA_ "U_P708_MY2023_Rx" SG_ 909 TurnLghtSwtch_D_Stat2 1;
BA_ "U_P702_MY2024_Rx" SG_ 909 TurnLghtSwtch_D_Stat2 1;
BA_ "GenSigStartValue" SG_ 909 HeadLghtHiPrmsn_D_Stat 3;
BA_ "U_V713N_MY2022_Rx" SG_ 909 SteWhlLckMsgTxt_D_Rq 1;
BA_ "U_V713AV_MY2022_Rx" SG_ 909 SteWhlLckMsgTxt_D_Rq 1;
BA_ "U_V710_MY2023_Rx" SG_ 909 SteWhlLckMsgTxt_D_Rq 1;
BA_ "U_P702_MY2024_Rx" SG_ 909 SteWhlLckMsgTxt_D_Rq 1;
BA_ "WakeupSignal" SG_ 909 immoMsgTxt_D_Rq 1;
BA_ "U_V713N_MY2022_Rx" SG_ 909 immoMsgTxt_D_Rq 1;
BA_ "U_V713AV_MY2022_Rx" SG_ 909 immoMsgTxt_D_Rq 1;
BA_ "U_V710_MY2023_Rx" SG_ 909 immoMsgTxt_D_Rq 1;
BA_ "U_P708_MY2023_Rx" SG_ 909 immoMsgTxt_D_Rq 1;
BA_ "U_P702_MY2024_Rx" SG_ 909 immoMsgTxt_D_Rq 1;
BA_ "WakeupSignal" SG_ 909 PrsnlDevcChrgEnbl_B_Rq 1;
BA_ "U_CDX74X_MY2024_Rx" SG_ 909 PrsnlDevcChrgEnbl_B_Rq 1;
BA_ "U_V710_MY2023_Rx" SG_ 909 PrsnlDevcChrgEnbl_B_Rq 1;
BA_ "U_P702_MY2024_Rx" SG_ 909 PrsnlDevcChrgEnbl_B_Rq 1;
BA_ "U_P708_MY2023_Rx" SG_ 909 PrsnlDevcChrgEnbl_B_Rq 1;
BA_ "U_V713N_MY2022_Rx" SG_ 909 TracKeyMde_D_Stat 1;
BA_ "U_V713AV_MY2022_Rx" SG_ 909 TracKeyMde_D_Stat 1;
BA_ "U_P708_MY2023_Rx" SG_ 909 TracKeyMde_D_Stat 1;
BA_ "U_V710_MY2023_Rx" SG_ 909 TracKeyMde_D_Stat 1;
BA_ "U_P702_MY2024_Rx" SG_ 909 TracKeyMde_D_Stat 1;
BA_ "U_V713N_MY2022_Rx" SG_ 909 Keycode_Status 1;
BA_ "U_V713AV_MY2022_Rx" SG_ 909 Keycode_Status 1;
BA_ "U_V710_MY2023_Rx" SG_ 909 Keycode_Status 1;
BA_ "U_P708_MY2023_Rx" SG_ 909 Keycode_Status 1;
BA_ "U_P702_MY2024_Rx" SG_ 909 Keycode_Status 1;
BA_ "U_V713N_MY2022_Rx" SG_ 909 PEBackupSlot_Stats 1;
BA_ "U_V713AV_MY2022_Rx" SG_ 909 PEBackupSlot_Stats 1;
BA_ "U_V710_MY2023_Rx" SG_ 909 PEBackupSlot_Stats 1;
BA_ "U_P708_MY2023_Rx" SG_ 909 PEBackupSlot_Stats 1;
BA_ "U_P702_MY2024_Rx" SG_ 909 PEBackupSlot_Stats 1;
BA_ "MetaData" SG_ 909 KeyMykeyTot_No_Cnt 1;
BA_ "U_V713N_MY2022_Rx" SG_ 909 KeyMykeyTot_No_Cnt 1;
BA_ "U_V713AV_MY2022_Rx" SG_ 909 KeyMykeyTot_No_Cnt 1;
BA_ "U_V710_MY2023_Rx" SG_ 909 KeyMykeyTot_No_Cnt 1;
BA_ "U_P702_MY2024_Rx" SG_ 909 KeyMykeyTot_No_Cnt 1;
BA_ "MetaData" SG_ 909 KeyAdmnTot_No_Cnt 1;
BA_ "U_V713N_MY2022_Rx" SG_ 909 KeyAdmnTot_No_Cnt 1;
BA_ "U_V713AV_MY2022_Rx" SG_ 909 KeyAdmnTot_No_Cnt 1;
BA_ "U_V710_MY2023_Rx" SG_ 909 KeyAdmnTot_No_Cnt 1;
BA_ "U_P708_MY2023_Rx" SG_ 909 KeyAdmnTot_No_Cnt 1;
BA_ "U_P702_MY2024_Rx" SG_ 909 KeyAdmnTot_No_Cnt 1;
BA_ "GenSigSendType" SG_ 1824 TesterPhysicalReqIPC 3;
BA_ "U_V713N_MY2022_Rx" SG_ 1824 TesterPhysicalReqIPC 1;
BA_ "U_V713AV_MY2022_Rx" SG_ 1824 TesterPhysicalReqIPC 1;
BA_ "U_P708_MY2023_Rx" SG_ 1824 TesterPhysicalReqIPC 1;
BA_ "U_V710_MY2023_Rx" SG_ 1824 TesterPhysicalReqIPC 1;
VAL_ 974 LowFuelDsplyType_B_Rq 1 "Volume" 0 "Miles" ;
VAL_ 974 PwBedPnlEnblScnd_B_Rq 1 "Enable" 0 "Disable" ;
VAL_ 974 DcacSysScnd_B_Falt 1 "Yes" 0 "No" ;
VAL_ 974 DcacOnScnd_B_Rq 1 "Enable" 0 "Disable" ;
VAL_ 974 DcacGfciTestScnd_B_Rq 1 "Pressed" 0 "Not_Pressed" ;
VAL_ 974 DcacGfciTest_B_Rq 1 "Pressed" 0 "Not_Pressed" ;
VAL_ 974 EngExhMdeHrStrt_D_Stat 31 "NotUsed_7" 30 "NotUsed_6" 29 "NotUsed_5" 28 "NotUsed_4" 27 "NotUsed_3" 26 "NotUsed_2" 25 "NotUsed_1" 24 "Hour23_11pm" 23 "Hour22_10pm" 22 "Hour21_9pm" 21 "Hour20_8pm" 20 "Hour19_7pm" 19 "Hour18_6pm" 18 "Hour17_5pm" 17 "Hour16_4pm" 16 "Hour15_3pm" 15 "Hour14_2pm" 14 "Hour13_1pm" 13 "Hour12_12pm" 12 "Hour11_11am" 11 "Hour10_10am" 10 "Hour9_9am" 9 "Hour8_8am" 8 "Hour7_7am" 7 "Hour6_6am" 6 "Hour5_5am" 5 "Hour4_4am" 4 "Hour3_3am" 3 "Hour2_2am" 2 "Hour1_1am" 1 "Hour0_12am" 0 "Null" ;
VAL_ 974 EngExhMdeHrEnd_D_Stat 31 "NotUsed_7" 30 "NotUsed_6" 29 "NotUsed_5" 28 "NotUsed_4" 27 "NotUsed_3" 26 "NotUsed_2" 25 "NotUsed_1" 24 "Hour23_11pm" 23 "Hour22_10pm" 22 "Hour21_9pm" 21 "Hour20_8pm" 20 "Hour19_7pm" 19 "Hour18_6pm" 18 "Hour17_5pm" 17 "Hour16_4pm" 16 "Hour15_3pm" 15 "Hour14_2pm" 14 "Hour13_1pm" 13 "Hour12_12pm" 12 "Hour11_11am" 11 "Hour10_10am" 10 "Hour9_9am" 9 "Hour8_8am" 8 "Hour7_7am" 7 "Hour6_6am" 6 "Hour5_5am" 5 "Hour4_4am" 4 "Hour3_3am" 3 "Hour2_2am" 2 "Hour1_1am" 1 "Hour0_12am" 0 "Null" ;
VAL_ 974 EngExhMdeHrEnbl_D_Stat 3 "NotUsed" 2 "Enabled" 1 "Disabled" 0 "Null" ;
VAL_ 974 DcacOut_Pw_DsplyMx 1023 "Faulty" ;
VAL_ 974 DcacOut1_Pw_Dsply 63 "Faulty" ;
VAL_ 974 DcacOut2_Pw_Dsply 63 "Faulty" ;
VAL_ 974 DcacHw_D_Confg 15 "NotUsed_11" 14 "NotUsed_10" 13 "NotUsed_9" 12 "NotUsed_8" 11 "NotUsed_7" 10 "NotUsed_6" 9 "NotUsed_5" 8 "NotUsed_4" 7 "NotUsed_3" 6 "NotUsed_2" 5 "Dual_2400WAnd7200W" 4 "Power_2300W" 3 "Power_7200W" 2 "Power_2400W" 1 "Power_2000W" 0 "NoDcacHardware" ;
VAL_ 974 DcacFaltMsgTxt_D_Rq 15 "HvacOn" 14 "OvercurrentLP" 13 "EngineRun" 12 "Service" 11 "NotAvailable" 10 "PlugWarn" 9 "PlugWarnDrive" 8 "BreakerC" 7 "BreakerB" 6 "BreakerA" 5 "FuelLow" 4 "AcOnOutput" 3 "Temperature" 2 "Gfci" 1 "Overcurrent" 0 "Ok" ;
VAL_ 974 DcacLoFuelMsgTxt_D_Rq 31 "Minute_31" 30 "Minute_30" 29 "Minute_29" 28 "Minute_28" 27 "Minute_27" 26 "Minute_26" 25 "Minute_25" 24 "Minute_24" 23 "Minute_23" 22 "Minute_22" 21 "Minute_21" 20 "Minute_20" 19 "Minute_19" 18 "Minute_18" 17 "Minute_17" 16 "Minute_16" 15 "Minute_15" 14 "Minute_14" 13 "Minute_13" 12 "Minute_12" 11 "Minute_11" 10 "Minute_10" 9 "Minute_9" 8 "Minute_8" 7 "Minute_7" 6 "Minute_6" 5 "Minute_5" 4 "Minute_4" 3 "Minute_3" 2 "Minute_2" 1 "Minute_1" 0 "Ok" ;
VAL_ 974 DcacEngOnMsgTxt_D_Rq 3 "NotUsed" 2 "DisplayQuestion" 1 "DisplayWarning" 0 "Ok" ;
VAL_ 974 DcacElPw_D_Stat 3 "NotUsed" 2 "High" 1 "Low" 0 "Off" ;
VAL_ 974 PwBedPnlEnbl_B_Rq 1 "Enable" 0 "Disable" ;
VAL_ 974 DcacOn_B_Rq 1 "Enable" 0 "Disable" ;
VAL_ 974 DcacSys_B_Falt 1 "Yes" 0 "No" ;
VAL_ 974 DcacLedCtl_D_Rq 3 "Fast_Flash" 2 "Slow_Flash" 1 "On" 0 "Off" ;
VAL_ 810 OneTEditActv_B_RqCld 1 "Yes" 0 "No" ;
VAL_ 810 ExtLghtDsply_B_StatArb 1 "On" 0 "Off" ;
VAL_ 552 ActvNseMute_D_Stat 3 "NotUsed_1" 2 "Muted" 1 "NotMuted" 0 "Inactive" ;
VAL_ 552 DSP_VoiceFBVolume_Up 1 "Update" 0 "NoUpdate" ;
VAL_ 552 DSP_TAVolume_Up 1 "Update" 0 "NoUpdate" ;
VAL_ 552 DSP_Shaker_St 1 "Active" 0 "Inactive" ;
VAL_ 552 DSP_Reg_St 0 "Invalid" 1 "Off" 2 "On" ;
VAL_ 552 DSP_PhoneVolume_Up 1 "Update" 0 "NoUpdate" ;
VAL_ 552 DSP_NavCmdVolume_Up 1 "Update" 0 "NoUpdate" ;
VAL_ 552 DSP_DSPProgram_St 7 "Reserved2" 6 "Reserved1" 5 "Voice" 4 "Rock" 0 "Invalid" 1 "Normal" 2 "Pop" 3 "Classical" ;
VAL_ 552 DSP_DSP_St 0 "Invalid" 1 "All" 2 "Driver" 3 "Passenger" 4 "Pop" 5 "Classical" 6 "Rock" ;
VAL_ 552 Audio_Demo_Status 1 "Active" 0 "Inactive" ;
VAL_ 967 NfcMyKeyCreate_D_Stat 3 "KeyAlreadyMyKey" 2 "TapTimeOut" 1 "TapNfcCard" 0 "Null" ;
VAL_ 967 CamZoomActiveState 3 "Not_Used" 2 "Inactive" 1 "Active" 0 "Invalid" ;
VAL_ 967 CamraViewSplit_D_Actl 3 "NotUsed" 2 "Inactive" 1 "Active" 0 "Invalid" ;
VAL_ 967 CamraOvrlTow_D_Actl 3 "Not_Used" 2 "Inactive" 1 "Active" 0 "Invalid" ;
VAL_ 967 CamraZoomMan_D_Actl 7 "Unknown" 6 "Invalid" 5 "Zoom_Level_V" 4 "Zoom_Level_IV" 3 "Zoom_Level_III" 2 "Zoom_Level_II" 1 "Zoom_Level_I" 0 "Off" ;
VAL_ 967 CamraOvrlStat_D_Actl 3 "Not_Used" 2 "Inactive" 1 "Active" 0 "Invalid" ;
VAL_ 967 CamraOvrlDyn_D_Actl 3 "Not_Used" 2 "Inactive" 1 "Active" 0 "Invalid" ;
VAL_ 967 CamPDCGuidStat 3 "Not_Used" 2 "Inactive" 1 "Active" 0 "Invalid" ;
VAL_ 1105 ClrExitAsstActv_B_Rq 1 "Active" 0 "Inactive" ;
VAL_ 1105 ClrExitAsstMsgTxt2_D_Rq 15 "NotUsed_7" 14 "NotUsed_6" 13 "NotUsed_5" 12 "NotUsed_4" 11 "NotUsed_3" 10 "NotUsed_2" 9 "NotUsed_1" 8 "FrontLeftRearRight" 7 "RearLeftFrontRight" 6 "FrontLeftFrontRight" 5 "RearLeftRearRight" 4 "FrontRight" 3 "FrontLeft" 2 "RearRight" 1 "RearLeft" 0 "NoMessage" ;
VAL_ 1105 TrlrRvrseEnbl_D2_Stat 7 "NotUsed" 6 "TbaActiveExpertActive" 5 "TbaActiveExpertAvail" 4 "TbaOffTrgActive" 3 "TbaOffTrgSetup" 2 "TbaSetup" 1 "TbaActive" 0 "Inactive" ;
VAL_ 1105 TrlrAidSwtchLamp_B_Rq 1 "On" 0 "Off" ;
VAL_ 1105 TrlrAidEnbl_D_RqAdas 7 "NotUsed_4" 6 "NotUsed_3" 5 "NotUsed_2" 4 "NotUsed_1" 3 "Deactivate" 2 "NotAvailable" 1 "ActiveTba" 0 "Inactive" ;
VAL_ 1105 TrlrHitchMsgTxt_D_Rq 31 "Message31" 30 "Message30" 29 "Message29" 28 "Message28" 27 "Message27" 26 "Message26" 25 "Message25" 24 "Message24" 23 "Message23" 22 "Message22" 21 "Message21" 20 "Message20" 19 "Message19" 18 "Message18" 17 "Message17" 16 "Message16" 15 "Message15" 14 "Message14" 13 "Message13" 12 "Message12" 11 "Message11" 10 "Message10" 9 "Message9" 8 "Message8" 7 "Message7" 6 "Message6" 5 "Message5" 4 "Message4" 3 "Message3" 2 "Message2" 1 "Message1" 0 "NoMessage" 63 "Message63" 47 "Message47" ;
VAL_ 1105 TrlrHitchIcon_D_Rq 15 "Icon15" 14 "Icon14" 13 "Icon13" 12 "Icon12" 11 "Icon11" 10 "Icon10" 9 "Icon9" 8 "Icon8" 7 "Icon7" 6 "Icon6" 5 "Icon5" 4 "Icon4" 3 "Icon3" 2 "Icon2" 1 "Icon1" 0 "NoIcon" ;
VAL_ 1105 CamraFrntOffRd_B_Stat 1 "Active" 0 "Inactive" ;
VAL_ 1105 TrlrHitchChime_D_Rq 7 "NotUsed_1" 6 "NotUsed_1" 5 "WarningChime" 4 "NonCriticalAlertChime" 3 "StopNowChime" 2 "ManeuveringReadyChime" 1 "TrailerFoundChime" 0 "NoChime" ;
VAL_ 1105 TrlrRvrseMsgTxt_D2_Rq 31 "Message31" 30 "Message30" 29 "Message29" 28 "Message28" 27 "Message27" 26 "Message26" 25 "Message25" 24 "Message24" 23 "Message23" 22 "Message22" 21 "Message21" 20 "Message20" 19 "Message19" 18 "Message18" 17 "Message17" 16 "Message16" 15 "Message15" 14 "Message14" 13 "Message13" 12 "Message12" 11 "Message11" 10 "Message10" 9 "Message9" 8 "Message8" 7 "Message7" 6 "Message6" 5 "Message5" 4 "Message4" 3 "Message3" 2 "Message2" 1 "Message1" 0 "NoMessage" 63 "Message63" 47 "Message47" ;
VAL_ 1105 RbaMsg_D_Rq 3 "Faulty" 2 "Unavailable" 1 "Off" 0 "Null" ;
VAL_ 1105 BrkDecel_B_RqRba 1 "Enable" 0 "Disable" ;
VAL_ 1105 BrkEnbl_B_RqRba 1 "Enable" 0 "Disable" ;
VAL_ 1105 Rba_D_Stat 3 "NotUsed" 2 "Disabled" 1 "On" 0 "Off" ;
VAL_ 1105 RbaAlrt_D_Dsply 3 "Both" 2 "Text" 1 "Graphic" 0 "Off" ;
VAL_ 1105 RbaMnu_D_Rq 3 "NotUsed" 2 "Active" 1 "Inactive" 0 "None" ;
VAL_ 1105 CamraFrntStat_D_Stat 3 "No_Data_Present" 2 "NotUsed" 1 "On" 0 "Off" ;
VAL_ 1105 TrlrHitchLamp_D_Rq2 1 "On" 0 "Off" ;
VAL_ 867 LHS_Temp_Disp_Digit3 2 "_5" 1 "_0" 0 "OFF" ;
VAL_ 867 Front_Blower_Ind 15 "Display_Blank" 14 "14_Indicators_On" 13 "13_Indicators_On" 12 "12_Indicators_On" 11 "11_Indicators_On" 10 "10_Indicators_On" 9 "9_Indicators_On" 8 "8_Indicators_On" 7 "7_Indicators_On" 6 "6_Indicators_On" 5 "5_Indicators_On" 4 "4_Indicators_On" 3 "3_Indicators_On" 2 "2_Indicators_On" 1 "1_Indicator_On" 0 "Indicators_Off" ;
VAL_ 867 EATC_LHS_Unit 2 "Fahrenheit" 1 "Celsius" 0 "Off" ;
VAL_ 866 CabnScentFanCalib_No_Rq 255 "NotDetermined" 254 "Calib_254" 1 "Calib_1" 0 "Invalid" ;
VAL_ 866 CabnScentIntns_D_Rq 7 "High" 6 "Medium_High" 5 "Medium" 4 "Medium_Low" 3 "Low" 2 "Very_Low" 1 "Off" 0 "NotDetermined" ;
VAL_ 866 CabnScentChnl_D_Rq 7 "Channel_7" 6 "Channel_6" 5 "Channel_5" 4 "Channel_4" 3 "Channel_3" 2 "Channel_2" 1 "Channel_1" 0 "Off" ;
VAL_ 866 CabnScentMde_D_Rq 3 "MasterScent" 2 "StopScent" 1 "StartOrContinueScent" 0 "NoneOrNoneYet" ;
VAL_ 866 SnowPlowOn_B_Rq 1 "On" 0 "Off" ;
VAL_ 866 Frt_Blower_Speed2 15 "NotUsed_6" 14 "NotUsed_5" 13 "NotUsed_4" 12 "NotUsed_3" 11 "NotUsed_2" 10 "Zero_Blower" 9 "Max_Blower" 8 "Min_Blower" 7 "Blower_Speed_7" 6 "Blower_Speed_6" 5 "Blower_Speed_5" 4 "Blower_Speed_4" 3 "Blower_Speed_3" 2 "Blower_Speed_2" 1 "Blower_Speed_1" 0 "No_Request" ;
VAL_ 866 Psngr_Set_Temp 31 "HI" 30 "_29_5" 29 "_29_0" 28 "_28_5" 27 "_28_0" 26 "_27_5" 25 "_27_0" 24 "_26_5" 23 "_26_0" 22 "_25_5" 21 "_25_0" 20 "_24_5" 19 "_24_0" 18 "_23_5" 17 "_23_0" 16 "_22_5" 15 "_22_0" 14 "_21_5" 13 "_21_0" 12 "_20_5" 11 "_20_0" 10 "_19_5" 9 "_19_0" 8 "_18_5" 7 "_18_0" 6 "_17_5" 5 "_17_0" 4 "_16_5" 3 "_16_0" 2 "_15_5" 1 "LO" 0 "No_Request" ;
VAL_ 866 ClimtRearView_D_Stat 3 "ThirdRow" 2 "SecondRow" 1 "Both" 0 "NotDisplayed" ;
VAL_ 866 Voice_Blower_Limit 1 "Request" 0 "NoRequest" ;
VAL_ 866 Rr_Btn_Status_2nd 31 "NotUsed_7" 30 "NotUsed_6" 29 "NotUsed_5" 28 "NotUsed_4" 27 "NotUsed_3" 26 "NotUsed_2" 25 "NotUsed_1" 24 "Third_Sync_Pressed" 23 "Third_Rr_Pwr_Pressed" 22 "Third_Auto_Pressed" 21 "Third_Pnl_Flr_Pressed" 20 "Third_Floor_Pressed" 19 "Third_Panel_Pressed" 18 "Third_Blwr_Dec_Pressed" 17 "Third_Blwr_Inc_Pressed" 16 "Rear_Lock_Pressed" 15 "RHS_Cld_Seat_Pressed" 14 "LHS_Cld_Seat_Pressed" 13 "RHS_Htd_Seat_Pressed" 12 "LHS_Htd_Seat_Pressed" 11 "Rear_Power_Pressed" 10 "AUTO_Pressed" 9 "Blwr_Dec_Pressed" 8 "Blwr_Inc_Pressed" 7 "RHS_Temp_Dec_Pressed" 6 "RHS_Temp_Inc_Pressed" 5 "LHS_Temp_Dec_Pressed" 4 "LHS_Temp_Inc_Pressed" 3 "Floor_Pressed" 2 "Panel_Floor_Pressed" 1 "Panel_Pressed" 0 "None_Pressed" ;
VAL_ 866 Rr_Btn_Status_1st 31 "NotUsed_7" 30 "NotUsed_6" 29 "NotUsed_5" 28 "NotUsed_4" 27 "NotUsed_3" 26 "NotUsed_2" 25 "NotUsed_1" 24 "Third_Sync_Pressed" 23 "Third_Rr_Pwr_Pressed" 22 "Third_Auto_Pressed" 21 "Third_Pnl_Flr_Pressed" 20 "Third_Floor_Pressed" 19 "Third_Panel_Pressed" 18 "Third_Blwr_Dec_Pressed" 17 "Third_Blwr_Inc_Pressed" 16 "Rear_Lock_Pressed" 15 "RHS_Cld_Seat_Pressed" 14 "LHS_Cld_Seat_Pressed" 13 "RHS_Htd_Seat_Pressed" 12 "LHS_Htd_Seat_Pressed" 11 "Rear_Power_Pressed" 10 "AUTO_Pressed" 9 "Blwr_Dec_Pressed" 8 "Blwr_Inc_Pressed" 7 "RHS_Temp_Dec_Pressed" 6 "RHS_Temp_Inc_Pressed" 5 "LHS_Temp_Dec_Pressed" 4 "LHS_Temp_Inc_Pressed" 3 "Floor_Pressed" 2 "Panel_Floor_Pressed" 1 "Panel_Pressed" 0 "None_Pressed" ;
VAL_ 866 Frt_Btn_Status_2nd 36 "MdeMnu_Pressed" 35 "AAR_Pressed" 34 "Heat_Pressed" 33 "RearMnu_Pressed" 32 "FrontMnu_Pressed" 63 "NotUsed_10" 62 "NotUsed_9" 61 "NotUsed_8" 60 "NotUsed_7" 59 "NotUsed_6" 58 "AUTO_Dec_Pressed" 57 "AUTO_Inc_Pressed" 56 "AUTO_Hi_Pressed" 55 "AUTO_Med_Pressed" 54 "AUTO_Lo_Pressed" 53 "RHS_Cld_Seat3_Pressed" 52 "RHS_Cld_Seat2_Pressed" 51 "RHS_Cld_Seat1_Pressed" 50 "LHS_Cld_Seat3_Pressed" 49 "LHS_Cld_Seat2_Pressed" 48 "LHS_Cld_Seat1_Pressed" 47 "RHS_Auto_Seat_Pressed" 46 "RHS_Htd_Seat3_Pressed" 45 "RHS_Htd_Seat2_Pressed" 44 "RHS_Htd_Seat1_Pressed" 43 "RHS_Seat_Off_Pressed" 42 "LHS_Auto_Seat_Pressed" 41 "LHS_Htd_Seat3_Pressed" 40 "LHS_Htd_Seat2_Pressed" 39 "LHS_Htd_Seat1_Pressed" 38 "LHS_Seat_Off_Pressed" 37 "DrvrFcsdMde_Pressed" 31 "Defrost_Pressed" 30 "Htg_Strg_Whl_Pressed" 29 "RHS_Cld_Seat_Pressed" 28 "LHS_Cld_Seat_Pressed" 27 "RHS_Htd_Seat_Pressed" 26 "LHS_Htd_Seat_Pressed" 25 "Max_Defrost_Pressed" 24 "My_Temp_Pressed" 23 "Front_Power_Pressed" 22 "Rear_Defrost_Pressed" 21 "Pnl_Flr_Ws_Pressed" 20 "Pnl_Ws_Pressed" 19 "Windscreen_Pressed" 18 "Htd_Frt_Wsh_Pressed" 17 "Auto_Recirc_Pressed" 16 "Outside_Pressed" 15 "Recirc_Pressed" 14 "Max_AC_Pressed" 13 "AUTO_Pressed" 12 "Blwr_Dec_Pressed" 11 "Blwr_Inc_Pressed" 10 "RHS_Temp_Dec_Pressed" 9 "RHS_Temp_Inc_Pressed" 8 "LHS_Temp_Dec_Pressed" 7 "LHS_Temp_Inc_Pressed" 6 "Dual_Pressed" 5 "AC_Pressed" 4 "Floor_Ws_Pressed" 3 "Floor_Pressed" 2 "Panel_Floor_Pressed" 1 "Panel_Pressed" 0 "None_Pressed" ;
VAL_ 866 Frt_Btn_Status_1st 36 "MdeMnu_Pressed" 35 "AAR_Pressed" 34 "Heat_Pressed" 33 "RearMnu_Pressed" 32 "FrontMnu_Pressed" 63 "NotUsed_10" 62 "NotUsed_9" 61 "NotUsed_8" 60 "NotUsed_7" 59 "NotUsed_6" 58 "AUTO_Dec_Pressed" 57 "AUTO_Inc_Pressed" 56 "AUTO_Hi_Pressed" 55 "AUTO_Med_Pressed" 54 "AUTO_Lo_Pressed" 53 "RHS_Cld_Seat3_Pressed" 52 "RHS_Cld_Seat2_Pressed" 51 "RHS_Cld_Seat1_Pressed" 50 "LHS_Cld_Seat3_Pressed" 49 "LHS_Cld_Seat2_Pressed" 48 "LHS_Cld_Seat1_Pressed" 47 "RHS_Auto_Seat_Pressed" 46 "RHS_Htd_Seat3_Pressed" 45 "RHS_Htd_Seat2_Pressed" 44 "RHS_Htd_Seat1_Pressed" 43 "RHS_Seat_Off_Pressed" 42 "LHS_Auto_Seat_Pressed" 41 "LHS_Htd_Seat3_Pressed" 40 "LHS_Htd_Seat2_Pressed" 39 "LHS_Htd_Seat1_Pressed" 38 "LHS_Seat_Off_Pressed" 37 "DrvrFcsdMde_Pressed" 31 "Defrost_Pressed" 30 "Htg_Strg_Whl_Pressed" 29 "RHS_Cld_Seat_Pressed" 28 "LHS_Cld_Seat_Pressed" 27 "RHS_Htd_Seat_Pressed" 26 "LHS_Htd_Seat_Pressed" 25 "Max_Defrost_Pressed" 24 "My_Temp_Pressed" 23 "Front_Power_Pressed" 22 "Rear_Defrost_Pressed" 21 "Pnl_Flr_Ws_Pressed" 20 "Pnl_Ws_Pressed" 19 "Windscreen_Pressed" 18 "Htd_Frt_Wsh_Pressed" 17 "Auto_Recirc_Pressed" 16 "Outside_Pressed" 15 "Recirc_Pressed" 14 "Max_AC_Pressed" 13 "AUTO_Pressed" 12 "Blwr_Dec_Pressed" 11 "Blwr_Inc_Pressed" 10 "RHS_Temp_Dec_Pressed" 9 "RHS_Temp_Inc_Pressed" 8 "LHS_Temp_Dec_Pressed" 7 "LHS_Temp_Inc_Pressed" 6 "Dual_Pressed" 5 "AC_Pressed" 4 "Floor_Ws_Pressed" 3 "Floor_Pressed" 2 "Panel_Floor_Pressed" 1 "Panel_Pressed" 0 "None_Pressed" ;
VAL_ 866 Frt_Blower_Speed 3 "NotUsed" 2 "Max_Blower" 1 "Min_Blower" 0 "No_Request" ;
VAL_ 866 Drv_Set_Temp 31 "HI" 30 "29_5" 29 "29_0" 28 "28_5" 27 "28_0" 26 "27_5" 25 "27_0" 24 "26_5" 23 "26_0" 22 "25_5" 21 "25_0" 20 "24_5" 19 "24_0" 18 "23_5" 17 "23_0" 16 "22_5" 15 "22_0" 14 "21_5" 13 "21_0" 12 "20_5" 11 "20_0" 10 "19_5" 9 "19_0" 8 "18_5" 7 "18_0" 6 "17_5" 5 "17_0" 4 "16_5" 3 "16_0" 2 "15_5" 1 "LO" 0 "No_Request" ;
VAL_ 861 Rr_Temp_Detents 15 "Unused5" 14 "Unused4" 13 "Unused3" 12 "Unused2" 11 "Unused1" 10 "Display_Blank" 9 "_4_Heat_Bars" 8 "_3_Heat_Bars" 7 "_2_Heat_Bars" 6 "_1_Heat_Bar" 5 "Neutral_Bar_Only" 4 "_1_Cool_Bar" 3 "_2_Cool_Bars" 2 "_3_Cool_Bars" 1 "_4_Cool_Bars" 0 "No_Bars" ;
VAL_ 861 Rr_Power_Btn_Stt 3 "Unused" 2 "Disabled" 1 "Active" 0 "Enabled_Inactive" ;
VAL_ 861 Rr_RH_Cond_Seat_Stat 7 "Unused" 6 "Level_3_Heating" 5 "Level_2_Heating" 4 "Level_1_Heating" 3 "Level_3_Cooling" 2 "Level_2_Cooling" 1 "Level_1_Cooling" 0 "Off" ;
VAL_ 861 Rr_Pnl_Flr_Btn_Stt 3 "Unused" 2 "Disabled" 1 "Active" 0 "Enabled_Inactive" ;
VAL_ 861 Rr_LH_Cond_Seat_Stat 7 "Unused" 6 "Level_3_Heating" 5 "Level_2_Heating" 4 "Level_1_Heating" 3 "Level_3_Cooling" 2 "Level_2_Cooling" 1 "Level_1_Cooling" 0 "Off" ;
VAL_ 861 CC_Rr_Stat_User_Adj 15 "Unused9" 14 "Unused8" 13 "Unused7" 12 "Unused6" 11 "Unused5" 10 "Unused4" 9 "Unused3" 8 "Unused2" 7 "Unused1" 6 "Rr_Auto_Selection" 5 "Rr_Control_Selection" 4 "Rr_Power_Selection" 3 "Rr_Blwr_Spd_Selection" 2 "RRHS_SetPt_Selection" 1 "RLHS_SetPt_Selection" 0 "None" ;
VAL_ 861 Rr_Set_Temp_Units 2 "Fahrenheit" 1 "Celsius" 0 "Off" ;
VAL_ 861 Rr_RHS_Set_Temp_Dig3 2 "_5" 1 "_0" 0 "Off" ;
VAL_ 861 Rr_RHS_Set_Temp_Dig2 15 "Blank2" 14 "Blank1" 13 "I" 12 "H" 11 "O" 10 "L" 9 "_9" 8 "_8" 7 "_7" 6 "_6" 5 "_5" 4 "_4" 3 "_3" 2 "_2" 1 "_1" 0 "_0" ;
VAL_ 861 Rr_RHS_Set_Temp_Dig1 15 "Blank2" 14 "Blank1" 13 "I" 12 "H" 11 "O" 10 "L" 9 "_9" 8 "_8" 7 "_7" 6 "_6" 5 "_5" 4 "_4" 3 "_3" 2 "_2" 1 "_1" 0 "_0" ;
VAL_ 861 Rr_RH_Htd_Seat_Btn_Stt 3 "Unused" 2 "Disabled" 1 "Active" 0 "Enabled_Inactive" ;
VAL_ 861 Rr_RH_Cld_Seat_Btn_Stt 3 "Unused" 2 "Disabled" 1 "Active" 0 "Enabled_Inactive" ;
VAL_ 861 Rr_Panel_Btn_Stt 3 "Unused" 2 "Disabled" 1 "Active" 0 "Enabled_Inactive" ;
VAL_ 861 Rr_On_Indicator 1 "On" 0 "Off" ;
VAL_ 861 Rr_LHS_Set_Temp_Dig3 2 "_5" 1 "_0" 0 "Off" ;
VAL_ 861 Rr_LHS_Set_Temp_Dig2 15 "Blank2" 14 "Blank1" 13 "I" 12 "H" 11 "O" 10 "L" 9 "_9" 8 "_8" 7 "_7" 6 "_6" 5 "_5" 4 "_4" 3 "_3" 2 "_2" 1 "_1" 0 "_0" ;
VAL_ 861 Rr_LHS_Set_Temp_Dig1 15 "Blank2" 14 "Blank1" 13 "I" 12 "H" 11 "O" 10 "L" 9 "_9" 8 "_8" 7 "_7" 6 "_6" 5 "_5" 4 "_4" 3 "_3" 2 "_2" 1 "_1" 0 "_0" ;
VAL_ 861 Rr_LH_Htd_Seat_Btn_Stt 3 "Unused" 2 "Disabled" 1 "Active" 0 "Enabled_Inactive" ;
VAL_ 861 Rr_LH_Cld_Seat_Btn_Stt 3 "Unused" 2 "Disabled" 1 "Active" 0 "Enabled_Inactive" ;
VAL_ 861 Rr_Floor_Btn_Stt 3 "Unused" 2 "Disabled" 1 "Active" 0 "Enabled_Inactive" ;
VAL_ 861 Rr_Control_Btn_Stt 3 "Unused" 2 "Disabled" 1 "Active" 0 "Enabled_Inactive" ;
VAL_ 861 Rr_Blower_Indicate 15 "Display_Blank" 14 "14_Indicators_On" 13 "13_Indicators_On" 12 "12_Indicators_On" 11 "11_Indicators_On" 10 "10_Indicators_On" 9 "9_Indicators_On" 8 "8_Indicators_On" 7 "7_Indicators_On" 6 "6_Indicators_On" 5 "5_Indicators_On" 4 "4_Indicators_On" 3 "3_Indicators_On" 2 "2_Indicators_On" 1 "1_Indicator_On" 0 "Indicators_Off" ;
VAL_ 861 Rr_AUTO_Btn_Stt 3 "Unused" 2 "Disabled" 1 "Active" 0 "Enabled_Inactive" ;
VAL_ 865 Dsp_RotAddrBtnEv_St 15 "NotUsed_1" 14 "Pos_7Steps" 13 "Pos_6Steps" 12 "Pos_5Steps" 11 "Pos_4Steps" 10 "Pos_3Steps" 9 "Pos_2Steps" 8 "Pos_1Step" 7 "NotPressed" 6 "Neg_1Steps" 5 "Neg_2Steps" 4 "Neg_3Steps" 3 "Neg_4Steps" 2 "Neg_5Steps" 1 "Neg_6Steps" 0 "Neg_7Steps" ;
VAL_ 865 SelDrvMdeButtn_B_Stat 1 "Pressed" 0 "Not_Pressed" ;
VAL_ 865 SteEffortButtn_B_Stat 1 "Pressed" 0 "Not_Pressed" ;
VAL_ 865 SelDrvMdeSwtch_D_Stat2 3 "Faulty" 2 "SwitchState2" 1 "SwitchState1" 0 "NotPressed" ;
VAL_ 865 EngExhMdeQuiet_B_RqDrv 1 "Pressed" 0 "Not_Pressed" ;
VAL_ 865 LnchCtlSys_B_RqDrv 1 "Pressed" 0 "Not_Pressed" ;
VAL_ 865 CC_Fr_Stat_User_Adj 7 "Unused4" 6 "RHS_AUTO_St_Selection" 5 "LHS_AUTO_St_Selection" 4 "DrvrFcsdMde_Selection" 3 "Fr_Blwr_Spd_Selection" 2 "FRHS_SetPt_Selection" 1 "FLHS_SetPt_Selection" 0 "None" ;
VAL_ 865 RHS_Auto_Seat_Btn_Stt 3 "Unused" 2 "Disabled" 1 "Active" 0 "Enabled_Inactive" ;
VAL_ 865 Front_Blower_Indicate 15 "Display_Blank" 14 "14_Indicators_On" 13 "13_Indicators_On" 12 "12_Indicators_On" 11 "11_Indicators_On" 10 "10_Indicators_On" 9 "9_Indicators_On" 8 "8_Indicators_On" 7 "7_Indicators_On" 6 "6_Indicators_On" 5 "5_Indicators_On" 4 "4_Indicators_On" 3 "3_Indicators_On" 2 "2_Indicators_On" 1 "1_Indicator_On" 0 "Indicators_Off" ;
VAL_ 865 CC_Diagnostics_Active 1 "Yes" 0 "No" ;
VAL_ 865 RHS_Temp_Display_Digit3 2 "_5" 1 "_0" 0 "OFF" ;
VAL_ 865 LHS_Temp_Display_Digit3 2 "_5" 1 "_0" 0 "OFF" ;
VAL_ 865 EATC_RHS_Units 2 "Fahrenheit" 1 "Celsius" 0 "Off" ;
VAL_ 865 EATC_LHS_Units 2 "Fahrenheit" 1 "Celsius" 0 "Off" ;
VAL_ 865 LHS_Auto_Seat_Btn_Stt 3 "Unused" 2 "Disabled" 1 "Active" 0 "Enabled_Inactive" ;
VAL_ 1046 PrkBrkDynmc_D_Allw 3 "NotUsed" 2 "EPB_ECD_NotPossible" 1 "EPB_ECD_Possible" 0 "Used_at_Start_Up" ;
VAL_ 1046 BrkPrkBrkDynmc_B_Actl 1 "Active" 0 "Inactive" ;
VAL_ 1046 TRLR_SWAY_EVNT_IN_PROG 1 "Yes" 0 "No" ;
VAL_ 1046 TRLR_SWAY_CONFIG_STAT 1 "On" 0 "Off" ;
VAL_ 1046 HsaMde_D_Mem 3 "Undefined" 2 "Manual" 1 "Automatic" 0 "Off" ;
VAL_ 1046 BrkBstrVac_B_Rq 1 "Yes" 0 "No" ;
VAL_ 1046 DrvSlipCtlMde_D_Ind 3 "App_Specific_Off_Mode_3" 2 "App_Specific_Off_Mode_2" 1 "App_Specific_Off_Mode_1" 0 "Default_Mode" ;
VAL_ 1046 DrvSlipCtlLamp_D_Rq 3 "Fast_Flash" 2 "Slow_Flash" 1 "On" 0 "Off" ;
VAL_ 1046 TCMode 1 "Active" 0 "Inactive" ;
VAL_ 1046 HILL_DESC_MC 7 "Fault_Detected" 6 "Cooling_Down" 5 "Abort_Apply_Brakes" 4 "Active" 3 "Disabled" 2 "Enabled" 1 "Off_Road" 0 "Normal" ;
VAL_ 1046 DrvAntiLckLamp_D_Rq 3 "Fast_Flash" 2 "Slow_Flash" 1 "On" 0 "Off" ;
VAL_ 1046 ChimeBrk_B_Rq 1 "Yes" 0 "No" ;
VAL_ 1046 BrkLamp_B_Rq 1 "Yes" 0 "No" ;
VAL_ 1046 Abs_B_Falt 1 "Yes" 0 "No" ;
VAL_ 1046 StabCtlBrk_B_Avail 1 "Yes" 0 "No" ;
VAL_ 1046 DrvHdcWarnInfo_D_Rq 3 "Undefined" 2 "Lamp_On_Continuously" 1 "Lamp_Flashing" 0 "Lamp_Off_Continuously" ;
VAL_ 1046 DrvHdcMsg_D_Rq 7 "Undefined" 6 "Speed_too_High" 5 "Temporarily_Unavailable" 4 "System_Fault" 3 "Select_Gear" 2 "Off" 1 "On" 0 "No_Message" ;
VAL_ 1046 DrvHdcLampInfo_D_Rq 3 "Fast_Flash" 2 "Slow_Flash" 1 "On" 0 "Off" ;
VAL_ 1046 RearDiffElckrOpen_B_Rq 1 "Yes" 0 "No" ;
VAL_ 1046 BpedMove_D_Actl 3 "Unknown" 2 "DriverApplyingBrakePedal" 1 "NoAutonomousBrkPdlMovement" 0 "AutonomousBrkPedalMove" ;
VAL_ 1046 RearDiffLck_Tq2_RqMx 4095 "Faulty" ;
VAL_ 1046 HdcMde_D_Actl 7 "Fault" 6 "Temporarily_Unavailable" 5 "NotEnabled_WrongGearSel" 4 "NotEnabled_SpdLimitExceed" 3 "Active_Braking" 2 "Not_Active_Braking" 1 "Off" 0 "Undefined" ;
VAL_ 534 WhlDirRr_D_Actl 3 "Faulty" 2 "NoDataExists" 1 "Backward" 0 "Forward" ;
VAL_ 534 WhlDirRl_D_Actl 3 "Faulty" 2 "NoDataExists" 1 "Backward" 0 "Forward" ;
VAL_ 534 WhlDirFr_D_Actl 3 "Faulty" 2 "NoDataExists" 1 "Backward" 0 "Forward" ;
VAL_ 534 WhlDirFl_D_Actl 3 "Faulty" 2 "NoDataExists" 1 "Backward" 0 "Forward" ;
VAL_ 402 CamraFrntBttn_D_Stat3 1 "Pressed" 0 "Not_Pressed" ;
VAL_ 402 PrkAidSwtch_D_RqMnu 1 "Pressed" 0 "Not_Pressed" ;
VAL_ 402 ApaSwtch_D_RqMnu 3 "NotUsed2" 2 "NotUsed1" 1 "Pressed" 0 "Not_Pressed" ;
VAL_ 402 ApaSlotAlrtSet_D_RqDrv 3 "TemporarySuppression" 2 "Disable" 1 "Enable" 0 "None" ;
VAL_ 402 ApaSlotTrgt_D_RqDrv 15 "NotUsed_7" 14 "NotUsed_6" 13 "NotUsed_5" 12 "NotUsed_4" 11 "NotUsed_3" 10 "NotUsed_2" 9 "NotUsed_1" 8 "Front" 7 "Rear" 6 "Right3" 5 "Right2" 4 "Right1" 3 "Left3" 2 "Left2" 1 "Left1" 0 "None" ;
VAL_ 402 ApaMdeStat_D_RqDrv 7 "Faulty" 6 "Off" 5 "NotUsed2" 4 "NotUsed1" 3 "POA" 2 "PPA" 1 "SAPP" 0 "Inactive" ;
VAL_ 402 ApaFeat_D_RqDrv 7 "Faulty" 6 "Off" 5 "RePA" 4 "ParkIn" 3 "POA" 2 "PPA" 1 "SAPP" 0 "Inactive" ;
VAL_ 402 ApaFeatChange_B_RqDrv 1 "True" 0 "False" ;
VAL_ 402 CamraViewSplit_B_Rq 1 "On" 0 "Off" ;
VAL_ 402 CamraZoomMan_D_Rq 7 "Unknown" 6 "Invalid" 5 "Zoom_Level_V" 4 "Zoom_Level_IV" 3 "Zoom_Level_III" 2 "Zoom_Level_II" 1 "Zoom_Level_I" 0 "Off" ;
VAL_ 402 CamraOvrlStat_D_Rq 1 "On" 0 "Off" ;
VAL_ 402 CamraOvrlDyn_D_Rq 1 "On" 0 "Off" ;
VAL_ 402 CamAutoTowbarZoom 1 "On" 0 "Off" ;
VAL_ 402 DistanceBarSetting 1 "On" 0 "Off" ;
VAL_ 946 ValetMode_D_Mem 1 "On" 0 "Off" ;
VAL_ 946 DrStatDrvErrCnt_B_Stat 1 "Yes" 0 "No" ;
VAL_ 946 Backlit_LED_Status 15 "Unused3" 14 "Unused2" 13 "Unused1" 12 "Night_12" 11 "Night_11" 10 "Night_10" 9 "Night_9" 8 "Night_8" 7 "Night_7" 6 "Night_6" 5 "Night_5" 4 "Night_4" 3 "Night_3" 2 "Night_2" 1 "Night_1" 0 "Off" ;
VAL_ 946 TurnLghtRightOn_B_Stat 1 "On" 0 "Off" ;
VAL_ 946 TurnLghtLeftOn_B_Stat 1 "On" 0 "Off" ;
VAL_ 946 FogLghtRearOn_B_Stat 1 "On" 0 "Off" ;
VAL_ 946 TurnLghtRight_D_Rq 3 "Seq" 2 "On" 1 "Off" 0 "Null" ;
VAL_ 946 IgnKeyType_D_Actl 15 "Invalid" 14 "Unknown" 3 "Key_Not_Prgrm_Read_Failure" 2 "Key_In_Ign_My_Key" 1 "Key_In_Ign_Standard_Key" 0 "Key_Read_In_Progress" ;
VAL_ 946 Parklamp_Status 3 "Invalid" 2 "Unknown" 1 "On" 0 "Off" ;
VAL_ 946 Litval 255 "Invalid" 254 "Unknown" 5 "Day" 4 "Twilight_4" 3 "Twilight_3" 2 "Twilight_2" 1 "Twilight_1" 0 "Night" ;
VAL_ 946 Key_In_Ignition_Stat 1 "In" 0 "Out" ;
VAL_ 946 Ignition_Status 0 "Unknown" 1 "Off" 15 "Invalid" 8 "Start" 4 "Run" 2 "Accessory" ;
VAL_ 946 Dimming_Lvl 255 "Invalid" 254 "Unknown" 18 "Day_6" 17 "Day_5" 16 "Day_4" 15 "Day_3" 14 "Day_2" 13 "Day_1" 12 "Night_12" 11 "Night_11" 10 "Night_10" 9 "Night_9" 8 "Night_8" 7 "Night_7" 6 "Night_6" 5 "Night_5" 4 "Night_4" 3 "Night_3" 2 "Night_2" 1 "Night_1" 0 "Off" ;
VAL_ 946 Day_Night_Status 3 "NotUsed" 2 "Night" 1 "Day" 0 "Null" ;
VAL_ 946 Remote_Start_Status 3 "Invalid" 2 "Unknown" 1 "Remote" 0 "Null" ;
VAL_ 946 DrStatTgate_B_Actl 1 "Ajar" 0 "Closed" ;
VAL_ 946 DrStatRr_B_Actl 1 "Ajar" 0 "Closed" ;
VAL_ 946 DrStatRl_B_Actl 1 "Ajar" 0 "Closed" ;
VAL_ 946 DrStatPsngr_B_Actl 1 "Ajar" 0 "Closed" ;
VAL_ 946 FogLghtFrontOn_B_Stat 1 "On" 0 "Off" ;
VAL_ 946 DrStatInnrTgate_B_Actl 1 "Ajar" 0 "Closed" ;
VAL_ 946 DrStatHood_B_Actl 1 "Ajar" 0 "Closed" ;
VAL_ 946 DrStatDrv_B_Actl 1 "Ajar" 0 "Closed" ;
VAL_ 946 PrkBrkActv_B_Actl 1 "Active" 0 "Inactive" ;
VAL_ 946 LifeCycMde_D_Actl 3 "Transport" 2 "NotUsed" 1 "Factory" 0 "Normal" ;
VAL_ 946 Delay_Accy 1 "On" 0 "Off" ;
VAL_ 946 TurnLghtLeft_D_Rq 3 "Seq" 2 "On" 1 "Off" 0 "Null" ;
VAL_ 946 CrashEvnt_D_Stat 3 "Invalid" 2 "Fuel_Cutoff_Event" 1 "Deploy_Event" 0 "No_Event" ;
VAL_ 946 FuelPmpInhbt_B_Stat 1 "Inhibit" 0 "No_Inibit" ;
VAL_ 946 BodySrvcRqd_B_Rq 1 "Yes" 0 "No" ;
VAL_ 778 PrkAidAcsyRear_D_RqDrv 3 "NotUsed" 2 "On" 1 "Off" 0 "Null" ;
VAL_ 778 PrkAidAcsyFront_D_RqDrv 3 "NotUsed" 2 "On" 1 "Off" 0 "Null" ;
VAL_ 778 Cta_D_Rq 3 "Unused" 2 "NoDataExists" 1 "On" 0 "Off" ;
VAL_ 778 PrkAidRear_D_RqDrv 2 "Status" 3 "NotUsed" 1 "Enabled" 0 "Disabled" ;
VAL_ 778 PrkAidFront_D_RqDrv 2 "Status" 3 "NotUsed" 1 "Enabled" 0 "Disabled" ;
VAL_ 778 SteEffort_D_Rq 7 "NotUsed_3" 6 "NotUsed_2" 5 "NotUsed_1" 4 "SpecialMode_2" 3 "SpecialMode_1" 2 "Comfort" 1 "Sport" 0 "Normal" ;
VAL_ 778 ClrExitAsstEnbl_D_RqDrv 3 "NotUsed" 0 "Inactive" 2 "Enable" 1 "Disable" ;
VAL_ 778 Sod_D_Rq 2 "BLIS_On_Second_Warning_ON" 1 "BLIS_On_Second_Warning_OFF" 0 "Off" ;
VAL_ 1093 TrlBrkInitOut_D_Stat 3 "Heavy" 2 "Medium" 1 "Light" 0 "Null" ;
VAL_ 1093 TrlrBrkMde_D_Actl 1 "Electric_Over_Hydraulic" 0 "Electric" ;
VAL_ 1093 TrlrBrkDsply_B_Rq 1 "Yes" 0 "No" ;
VAL_ 1093 TrlrBrkDcnnt_B_Actl 1 "Yes" 0 "No" ;
VAL_ 1093 TrlrBrkActCnnct_B_Actl 1 "Yes" 0 "No" ;
VAL_ 1093 StopLamp_B_RqTrlrBrk 1 "Yes" 0 "No" ;
VAL_ 1093 TrlrBrkCtl_B_Falt 1 "Yes" 0 "No" ;
VAL_ 1093 TrlrBrkActCirct_B_Falt 1 "Yes" 0 "No" ;
VAL_ 999 PersIndexFcim_D_Actl 7 "Unused_3" 6 "Unused_2" 5 "Unused_1" 4 "Vehicle" 3 "PERS_4" 2 "PERS_3" 1 "PERS_2" 0 "PERS_1" ;
VAL_ 1002 PersIndexApim_D_Actl 7 "Unused_3" 6 "Unused_2" 5 "Unused_1" 4 "Vehicle" 3 "PERS_4" 2 "PERS_3" 1 "PERS_2" 0 "PERS_1" ;
VAL_ 1002 CntrStk_D_RqRecall 7 "Unused_2" 6 "Unused_1" 5 "Vehicle" 4 "PERS_4" 3 "PERS_3" 2 "PERS_2" 1 "PERS_1" 0 "Null" ;
VAL_ 1002 CntrStk_D_RqAssoc 7 "Unused_2" 6 "Cancel" 5 "Set_Keycode" 4 "RKE" 3 "Null" 2 "Key" 1 "Erase_KeyCode" 0 "Check_KeyCode" ;
VAL_ 948 TlghtTestPrecnd_D2_Stat 7 "TrailerNotConnected" 6 "NotStationary" 5 "InteractionPresent" 4 "PreconditionsPassed" 3 "BattSocLessThan75Percent" 2 "TailLightsOn" 1 "IgnitionNotOn" 0 "Null" ;
VAL_ 948 TlghtTestLght_D2_Stat 7 "TestingRearFogLights" 6 "AllOff" 5 "TestingReverseLights" 4 "TestingBrakeLights" 3 "TestingLeftTurnSignal" 2 "TestingRightTurnSignal" 1 "ParkingLightsIlluminated" 0 "Null" ;
VAL_ 948 TirePReset_D_Stat 3 "Not_Used" 2 "Nack" 1 "Ack" 0 "Null" ;
VAL_ 948 Tire_Press_ILR_Stat 4 "Alert" 15 "Not_Supported" 3 "Fault" 2 "Low" 1 "Normal" 0 "Unknown" ;
VAL_ 948 Tire_Press_IRR_Stat 4 "Alert" 15 "Not_Supported" 3 "Fault" 2 "Low" 1 "Normal" 0 "Unknown" ;
VAL_ 948 Tire_Press_LR_OLR_Stat 4 "Alert" 15 "Not_Supported" 3 "Fault" 2 "Low" 1 "Normal" 0 "Unknown" ;
VAL_ 948 Tire_Press_RR_ORR_Stat 4 "Alert" 15 "Not_Supported" 3 "Fault" 2 "Low" 1 "Normal" 0 "Unknown" ;
VAL_ 948 Tire_Press_RF_Stat 4 "Alert" 15 "Not_Supported" 3 "Fault" 2 "Low" 1 "Normal" 0 "Unknown" ;
VAL_ 948 Tire_Press_LF_Stat 4 "Alert" 15 "Not_Supported" 3 "Fault" 2 "Low" 1 "Normal" 0 "Unknown" ;
VAL_ 948 Tire_Press_System_Stat 13 "Training_Complete" 12 "Train_InsideLeftRear_tire" 11 "Train_OutsideLeftRear_tire" 10 "Train_LeftRear_tire" 9 "Train_InsideRtRear_tire" 8 "Train_OutsideRtRear_tire" 7 "Train_RightRear_tire" 14 "Tires_not_trained" 6 "Train_RightFront_tire" 5 "Train_LeftFront_tire" 4 "Systm_Activ_Composite_Stat" 3 "Low_Composite_Stat" 2 "Sensr_Fault_Composite_Stat" 1 "Systm_Fault_Composite_Stat" 0 "Unknown_Composite_Stat" ;
VAL_ 948 Tire_Press_Telltale 3 "Not_Used" 2 "Flash" 1 "On" 0 "Off" ;
VAL_ 986 PsngrLoad_M_Rq 1023 "Faulty" 1022 "NoDataExists" ;
VAL_ 986 VehPayloadScrn_D_Rq 7 "CheckLoadScreenActive" 6 "WeightCarryScreenActive" 5 "GooseneckScreenActive" 4 "FifthWheelScreenActive" 3 "WeightDistScreenActive" 2 "AddMassEstScreenActive" 1 "PayloadEstScreenActive" 0 "ScaleScreenNotActive" ;
VAL_ 986 Trlr_M_Rq 2047 "Faulty" 2046 "NoDataExists" ;
VAL_ 986 VehPayloadTare_D_Rq 1 "Request" 0 "NoRequest" ;
VAL_ 986 VehFalr_D_Rq 7 "NotUsed_3" 6 "NotUsed_2" 5 "NotUsed_1" 4 "NotComplete" 3 "Complete" 2 "RequestSecondMeasurement" 1 "RequestFirstMeasurement" 0 "NoRequest" ;
VAL_ 986 TailLghtLoadMde_D_Rq 7 "NotUsed_3" 6 "NotUsed_2" 5 "NotUsed_1" 4 "DeactivateAll" 3 "ActivateFalrMode" 2 "ActivateHitchLoadMode" 1 "ActivatePayloadMode" 0 "NoCommand" ;
VAL_ 986 LightAmbIntsty_No_Rq 0 "Off" ;
VAL_ 993 StmsScrnDrvOn_B_Rq 1 "On" 0 "Off" ;
VAL_ 993 EmButtn_D_Stat 7 "ButtonAssociationFailed" 6 "ButtonAssociationExited" 5 "ButtonAssociationEntered" 4 "Button4Pressed" 3 "Button3Pressed" 2 "Button2Pressed" 1 "Button1Pressed" 0 "Null" ;
VAL_ 993 MemStoreMsgTxt_D_Rq 10 "NotUsed_2" 9 "NotUsed_1" 8 "Mem4Saved_ShowLinkMsg" 7 "Mem3Saved_ShowLinkMsg" 6 "Mem2Saved_ShowLinkMsg" 5 "Mem1Saved_ShowLinkMsg" 4 "Mem4Saved_DoNotShowLinkMsg" 3 "Mem3Saved_DoNotShowLinkMsg" 2 "Mem2Saved_DoNotShowLinkMsg" 1 "Mem1Saved_DoNotShowLinkMsg" 0 "Null" ;
VAL_ 993 MemSetButtnMsgTxt_D_Rq 3 "NotUsed" 2 "Press1or2or3" 1 "Press1or2" 0 "Null" ;
VAL_ 993 MemSwtch_D_RqRecall 7 "Unused_3" 6 "Unused_2" 5 "Unused_1" 4 "PERS_4" 3 "PERS_3" 2 "PERS_2" 1 "PERS_1" 0 "Null" ;
VAL_ 993 MemSwtch_D_RqAssoc 7 "Unused_3" 6 "Unused_2" 5 "Unused_1" 4 "PERS_4" 3 "PERS_3" 2 "PERS_2" 1 "PERS_1" 0 "Null" ;
VAL_ 993 PersIndexDsm_D_Actl 7 "Unused_3" 6 "Unused_2" 5 "Unused_1" 4 "Vehicle" 3 "PERS_4" 2 "PERS_3" 1 "PERS_2" 0 "PERS_1" ;
VAL_ 993 PersStore_D_Actl 3 "Unused" 2 "Null" 1 "InProgress" 0 "Complete" ;
VAL_ 997 PersTurnSglView_D_Stat 3 "NotConfigured" 2 "Enabled" 1 "Disabled" 0 "Null" ;
VAL_ 997 PersIndexCcm_D_Actl 7 "Unused_3" 6 "Unused_2" 5 "Unused_1" 4 "Vehicle" 3 "PERS_4" 2 "PERS_3" 1 "PERS_2" 0 "PERS_1" ;
VAL_ 487 Aioc_SetExtSrcOutpMd_Rq 5 "AllocateUSBToOutput" 4 "AllocateBtAudioToOutput" 3 "AllocateBtNavigationToOut" 2 "AllocateBtPhoneToOutput" 1 "AllocateVrAudioToOutput" 0 "Inactive" 8 "DeallocateOutput" 7 "AllocateAUX3" 6 "AllocateiPodToOutput" ;
VAL_ 464 SdarsSampleRate_D_Rq 3 "NotUsed" 2 "SampleRate_48000Hz" 1 "SampleRate_44100Hz" 0 "Null" ;
VAL_ 864 MdeMnu_Buttn_Stat 1 "Pressed" 0 "Not_Pressed" ;
VAL_ 864 Front_AUTO_Blwr_Lvl 3 "High" 2 "Medium" 1 "Low" 0 "Off" ;
VAL_ 864 RearMnu_Buttn_Stat 1 "Pressed" 0 "Not_Pressed" ;
VAL_ 864 FrontMnu_Buttn_Stat 1 "Pressed" 0 "Not_Pressed" ;
VAL_ 864 DrvrFcsdMde_Btn_Stt 3 "Unused" 2 "Disabled" 1 "Active" 0 "Enabled_Inactive" ;
VAL_ 864 RHS_Cond_Seat_Status 7 "Unused" 6 "Level_3_Heating" 5 "Level_2_Heating" 4 "Level_1_Heating" 3 "Level_3_Cooling" 2 "Level_2_Cooling" 1 "Level_1_Cooling" 0 "Off" ;
VAL_ 864 LHS_Cond_Seat_Status 7 "Unused" 6 "Level_3_Heating" 5 "Level_2_Heating" 4 "Level_1_Heating" 3 "Level_3_Cooling" 2 "Level_2_Cooling" 1 "Level_1_Cooling" 0 "Off" ;
VAL_ 864 Htd_Strg_Whl_Status 3 "Level_3_Heating" 2 "Level_2_Heating" 1 "Level_1_Heating" 0 "Off" ;
VAL_ 864 Htd_Strg_Whl_Btn_Stt 3 "Unused" 2 "Disabled" 1 "Active" 0 "Enabled_Inactive" ;
VAL_ 864 Defrost_Btn_Stt 3 "Unused" 2 "Disabled" 1 "Active" 0 "Enabled_Inactive" ;
VAL_ 864 CC_Fr_Btn_User_Adj 31 "Unused15" 30 "Unused14" 29 "Unused13" 28 "Unused12" 27 "Unused11" 26 "Unused10" 25 "Unused9" 24 "Unused8" 23 "Unused7" 22 "Unused6" 21 "RHS_Cld_St_Selection" 20 "LHS_Cld_St_Selection" 19 "UFC_Interrupted" 18 "UFC_Complete" 17 "UFC_Active" 16 "Htd_WS_Selection" 15 "RHS_Htd_St_Selection" 14 "LHS_Htd_St_Selection" 13 "HSW_Selection" 12 "Dual_Selection" 11 "Rear_Defrost_Selection" 10 "Max_Defrost_Selection" 9 "Defrost_Selection" 8 "Fr_Air_Dist_Selection" 7 "Max_AC_Selection" 6 "Fr_Power_Selection" 5 "Recirc_Selection" 4 "AC_Selection" 3 "Fr_Auto_Selection" 2 "Use_MyTemp_Selection" 1 "Save_MyTemp_Selection" 0 "None" ;
VAL_ 864 RHS_Htd_Seat_Btn_Stt 3 "Unused" 2 "Disabled" 1 "Active" 0 "Enabled_Inactive" ;
VAL_ 864 RHS_Cld_Seat_Btn_Stt 3 "Unused" 2 "Disabled" 1 "Active" 0 "Enabled_Inactive" ;
VAL_ 864 Outside_Btn_Stt 3 "Unused" 2 "Disabled" 1 "Active" 0 "Enabled_Inactive" ;
VAL_ 864 LHS_Htd_Seat_Btn_Stt 3 "Unused" 2 "Disabled" 1 "Active" 0 "Enabled_Inactive" ;
VAL_ 864 LHS_Cld_Seat_Btn_Stt 3 "Unused" 2 "Disabled" 1 "Active" 0 "Enabled_Inactive" ;
VAL_ 864 Htd_Frt_Wsh_Btn_Stt 3 "Unused" 2 "Disabled" 1 "Active" 0 "Enabled_Inactive" ;
VAL_ 864 Auto_Recirc_Btn_Stt 3 "Unused" 2 "Disabled" 1 "Active" 0 "Enabled_Inactive" ;
VAL_ 864 Recirc_Btn_Stt 3 "Unused" 2 "Disabled" 1 "Active" 0 "Enabled_Inactive" ;
VAL_ 864 Rear_Defrost_Btn_Stt 3 "Unused" 2 "Disabled" 1 "Active" 0 "Enabled_Inactive" ;
VAL_ 864 My_Temp_Btn_Stt 3 "Unused" 2 "Disabled" 1 "Active" 0 "Enabled_Inactive" ;
VAL_ 864 Max_Defrost_Btn_Stt 3 "Unused" 2 "Disabled" 1 "Active" 0 "Enabled_Inactive" ;
VAL_ 864 Max_AC_Btn_Stt 3 "Unused" 2 "Disabled" 1 "Active" 0 "Enabled_Inactive" ;
VAL_ 864 Front_AUTO_Label 3 "Full" 2 "Mode" 1 "Blower" 0 "Off" ;
VAL_ 864 Windscreen_Btn_Stt 3 "Unused" 2 "Disabled" 1 "Active" 0 "Enabled_Inactive" ;
VAL_ 864 Panel_Btn_Stt 3 "Unused" 2 "Disabled" 1 "Active" 0 "Enabled_Inactive" ;
VAL_ 864 Front_Power_Btn_Stt 3 "Unused" 2 "Disabled" 1 "Active" 0 "Enabled_Inactive" ;
VAL_ 864 Front_AUTO_Btn_Stt 3 "Unused" 2 "Disabled" 1 "Active" 0 "Enabled_Inactive" ;
VAL_ 864 Floor_Btn_Stt 3 "Unused" 2 "Disabled" 1 "Active" 0 "Enabled_Inactive" ;
VAL_ 864 Dual_Button_Stt 3 "Unused" 2 "Disabled" 1 "Active" 0 "Enabled_Inactive" ;
VAL_ 864 AC_Btn_Stt 3 "Unused" 2 "Disabled" 1 "Active" 0 "Enabled_Inactive" ;
VAL_ 994 PersCtaSplitView_D_Rq 3 "EnabledFull" 2 "Enabled_180SwitchOnly" 1 "Disabled" 0 "Null" ;
VAL_ 994 Pers4OptIn_B_Stats 1 "OPTED_IN" 0 "NOT_OPTED_IN" ;
VAL_ 994 Pers3OptIn_B_Stats 1 "OPTED_IN" 0 "NOT_OPTED_IN" ;
VAL_ 994 Pers2OptIn_B_Stats 1 "OPTED_IN" 0 "NOT_OPTED_IN" ;
VAL_ 994 Pers1OptIn_B_Stats 1 "OPTED_IN" 0 "NOT_OPTED_IN" ;
VAL_ 994 CtrStkPersIndex_D_Actl 7 "Unused_3" 6 "Unused_2" 5 "Unused_1" 4 "Vehicle" 3 "PERS_4" 2 "PERS_3" 1 "PERS_2" 0 "PERS_1" ;
VAL_ 994 PersStore_D_Rq 7 "Unused_2" 6 "Unused_1" 5 "Vehicle" 4 "PERS_4" 3 "PERS_3" 2 "PERS_2" 1 "PERS_1" 0 "Null" ;
VAL_ 994 CtrStkDsplyOp_D_Rq 7 "Unused_2" 6 "Unused_1" 5 "Copy" 4 "Restore" 3 "Upload" 2 "Set" 1 "Query" 0 "Null" ;
VAL_ 394 AccStopStat_D_Dsply 3 "PressResume" 2 "Stopped" 1 "ResumeReady" 0 "NoDisplay" ;
VAL_ 394 AccTrgDist2_D_Dsply 15 "DIST_ACTIVE_13_Farthest" 14 "DIST_ACTIVE_12" 13 "DIST_ACTIVE_11" 12 "DIST_ACTIVE_10" 11 "DIST_ACTIVE_9" 10 "DIST_ACTIVE_8" 9 "DIST_ACTIVE_7" 8 "DIST_ACTIVE_6" 7 "DIST_ACTIVE_5" 6 "DIST_ACTIVE_4" 5 "DIST_ACTIVE_3" 4 "DIST_ACTIVE_2" 3 "DIST_ACTIVE_1_Closest" 2 "DIST_ACTIVE_No_Target" 1 "DIST_STANDBY" 0 "DIST_OFF" ;
VAL_ 394 AccStopRes_B_Dsply 1 "Yes" 0 "No" ;
VAL_ 394 TjaWarn_D_Rq 7 "HardTakeOverEyesOff" 6 "SoftTakeOverEyesOff" 5 "HaLaneDeptWarningLeft" 4 "HaLaneDeptWarningRight" 3 "HardTakeOverLevel2" 2 "HardTakeOverLevel1" 1 "TrafficJamAssistCancel" 0 "NoWarning" ;
VAL_ 394 Tja_D_Stat 7 "ExtendedActive" 6 "ActiveWarningRight" 5 "ActiveWarningLeft" 4 "ActiveInterventionRight" 3 "ActiveInterventionLeft" 2 "Active" 1 "Standby" 0 "Off" ;
VAL_ 394 IaccLamp_D_Rq 3 "NotUsed_2" 2 "NotUsed_1" 1 "DisplayIaccIcon" 0 "DoNotDisplayIaccIcon" ;
VAL_ 394 AccMsgTxt_D2_Rq 15 "Brakes_Warm" 14 "NCC_Enabled_Warning" 13 "IACC_TJA_Selected" 12 "ACC_TJA_Selected" 11 "IACC_Selected" 10 "Press_Brake_To_Hold" 9 "Only_Following_In_Low_Spd" 8 "TJA_Unavailable" 7 "Shift_Down" 6 "IACC_Unavailable" 5 "ACC_Selected" 4 "ACC_Overridden" 3 "Brake_Capacity_Warning" 2 "ACC_Cancelled" 1 "ACC_Unavailable" 0 "No_Text" ;
VAL_ 394 TjaMsgTxt_D_Dsply 7 "Disclaimer" 6 "SmartOffering" 5 "HaSelected" 4 "HaUnavailable" 3 "TurnOnAdaptCruiseControl" 2 "TrafficJamAssistSelected" 1 "TrafficJamAssistUnavailabl" 0 "NoMessage" ;
VAL_ 394 FcwDeny_B_Dsply 1 "Yes" 0 "No" ;
VAL_ 394 FcwMemStat_B_Actl 1 "On" 0 "Off" ;
VAL_ 394 AccTGap_B_Dsply 1 "Yes" 0 "No" ;
VAL_ 394 CadsAlignIncplt_B_Actl 1 "Yes" 0 "No" ;
VAL_ 394 AccFllwMde_B_Dsply 1 "Yes" 0 "No" ;
VAL_ 394 CadsRadrBlck_B_Actl 1 "Yes" 0 "No" ;
VAL_ 394 CmbbPostEvnt_B_Dsply 1 "Yes" 0 "No" ;
VAL_ 394 AccStopMde_B_Dsply 1 "Yes" 0 "No" ;
VAL_ 394 FcwMemSens_D_Actl 3 "FCW_Sensitivity_3" 2 "FCW_Sensitivity_2" 1 "FCW_Sensitivity_1" 0 "Not_Used" ;
VAL_ 394 FcwMsgTxt_D_Rq 7 "Undefined_3" 6 "Undefined_2" 5 "Low_Visibility" 4 "Unavailable_DueTo_LowSpeed" 3 "Available" 2 "Unavailable" 1 "Off" 0 "No_Text" ;
VAL_ 394 AccTGap_D_Dsply 7 "Undefined_2" 6 "Undefined_1" 5 "Time_Gap_5" 4 "Time_Gap_4" 3 "Time_Gap_3" 2 "Time_Gap_2" 1 "Time_Gap_1" 0 "Not_Used" ;
VAL_ 394 AccMemEnbl_B_RqDrv 1 "Adaptive_Cruise" 0 "Normal_Cruise" ;
VAL_ 394 AccWarn_D_Dsply 3 "BrakeReleaseWarn_In_StopMd" 2 "Brake_Capacity_Warning" 1 "Cancel_Warning" 0 "No_Warning" ;
VAL_ 394 FcwVisblWarn_B_Rq 1 "On" 0 "Off" ;
VAL_ 394 FcwAudioWarn_B_Rq 1 "On" 0 "Off" ;
VAL_ 1068 TrlrAidMsgTxt_D_Rq 31 "Message31" 30 "Message30" 29 "Message29" 28 "Message28" 27 "Message27" 26 "Message26" 25 "Message25" 24 "Message24" 23 "Message23" 22 "Message22" 21 "Message21" 20 "Message20" 19 "Message19" 18 "Message18" 17 "Message17" 16 "Message16" 15 "Message15" 14 "Message14" 13 "Message13" 12 "Message12" 11 "Message11" 10 "Message10" 9 "Message9" 8 "Message8" 7 "Message7" 6 "Message6" 5 "Message5" 4 "Message4" 3 "Message3" 2 "Message2" 1 "Message1" 0 "NoMessage" ;
VAL_ 1019 PersIndexIpc_D_Actl 7 "Unused_3" 6 "Unused_2" 5 "Unused_1" 4 "Vehicle" 3 "PERS_4" 2 "PERS_3" 1 "PERS_2" 0 "PERS_1" ;
VAL_ 909 IgnPsswrdDsply_B_Rq 1 "Active" 0 "Inactive" ;
VAL_ 909 ElPwPoint_D_Rq 3 "On" 2 "Off2" 1 "Off1" 0 "Null" ;
VAL_ 909 PoliceIdlMde_D_Stat 15 "NotUsed_7" 14 "NotUsed_6" 13 "NotUsed_5" 12 "NotUsed_4" 11 "NotUsed_3" 10 "UtilityIdleActive" 9 "PepsActive" 8 "Decommissioned" 7 "ActiveFault" 6 "ArmFault" 5 "PrearmedFault" 4 "OffFault" 3 "Active" 2 "Arm" 1 "Prearmed" 0 "Off" ;
VAL_ 909 DrLatchMsgTxt_D_Rq 7 "Message7" 6 "Message6" 5 "Message5" 4 "Message4" 3 "Message3" 2 "Message2" 1 "Message1" 0 "NoMessage" ;
VAL_ 909 WiprFront_D_Stat2 15 "NO_DATA_EXISTS" 14 "STALLED" 13 "NotUsed" 12 "AUTO_ADJUST" 11 "COURTESYWIPE" 10 "AUTO_HIGH" 9 "AUTO_LOW" 8 "WASH" 7 "MIST_FLICK" 6 "MAN_HIGH" 5 "MAN_LOW" 4 "MAN_INT_ON" 3 "MAN_INT_OFF" 2 "OFF_MOVING" 1 "AUTO_OFF" 0 "OFF" ;
VAL_ 909 HazrdLght_B_Stat 1 "On" 0 "Off" ;
VAL_ 909 TurnLghtSwtch_D_Stat2 3 "NotUsed" 2 "Right" 1 "Left" 0 "Off" ;
VAL_ 909 HeadLghtHiPrmsn_D_Stat 3 "CancelAndSuppress" 2 "Cancel" 1 "Hold" 0 "AllowChange" ;
VAL_ 909 SecurityMsgTxt_D_Rq 3 "Message3" 2 "Message2" 1 "Message1" 0 "NoMessage" ;
VAL_ 909 SteWhlLckMsgTxt_D_Rq 3 "Message_3" 2 "Message_2" 1 "Message_1" 0 "No_Message" ;
VAL_ 909 immoMsgTxt_D_Rq 15 "Immo_Msg_15" 14 "Immo_Msg_14" 13 "Immo_Msg_13" 12 "Immo_Msg_12" 11 "Immo_Msg_11" 10 "Immo_Msg_10" 9 "Immo_Msg_9" 8 "Immo_Msg_8" 7 "Immo_Msg_7" 6 "Immo_Msg_6" 5 "Immo_Msg_5" 4 "Immo_Msg_4" 3 "Immo_Msg_3" 2 "Immo_Msg_2" 1 "Immo_Msg_1" 0 "Immo_Msg_0_Null" ;
VAL_ 909 PrsnlDevcChrgEnbl_B_Rq 1 "Active" 0 "Inactive" ;
VAL_ 909 PrmtrAlrmEvnt_D_Stat 15 "Diag_Tamper" 14 "Trailer" 13 "Shock_Sensor" 12 "Post_Crash" 11 "Panic" 10 "Intrusion" 9 "Inclination" 8 "Ign_Tamper" 7 "LG_Door" 6 "Decklid" 5 "Hood" 4 "PR_Door" 3 "PF_Door" 2 "DR_Door" 1 "DF_Door" 0 "Null" ;
VAL_ 909 TracKeyMde_D_Stat 3 "NotUsed" 2 "NotActive" 1 "Active" 0 "ModeNotDetermined" ;
VAL_ 909 PEBackupSlot_Stats 3 "No_Valid_FOB_In_Slot" 2 "MyKey_FOB_In_Slot" 1 "Standard_FOB_In_Slot" 0 "Null" ;
VAL_ 909 KeyMykeyTot_No_Cnt 13 "Thirteen" 12 "Twelve" 11 "Eleven" 10 "Ten" 9 "Nine" 8 "Eight" 7 "Seven" 6 "Six" 5 "Five" 4 "Four" 3 "Three" 2 "Two" 1 "One" 0 "Zero" 15 "Invalid" 14 "Unlimited" ;
VAL_ 909 KeyAdmnTot_No_Cnt 13 "Thirteen" 12 "Twelve" 11 "Eleven" 10 "Ten" 9 "Nine" 8 "Eight" 7 "Seven" 6 "Six" 5 "Five" 4 "Four" 3 "Three" 2 "Two" 1 "One" 0 "Zero" 15 "Invalid" 14 "Unlimited" ;
